VERSION "dbc-export 1 2025.20.8"

NS_ :

BS_:

BU_: BMS CC CMP CMPD CP DAS DI DIF DIR EPBL EPBR EVSE FC GTW HCML HCMR HVP ICR PCS PM PMF PMR PTC SCCM SCM SCS SDCR TAS UMC VC VCFRONT VCLEFT VCRIGHT VCSEC

BO_ 755 UI_hvacRequest: 8 GTW
 SG_ UI_hvacReqTempSetpointLeft : 0|5@1+ (0.5,15) [15|28] "degC" Vector__XXX
 SG_ UI_hvacReqAutoBlowerLevel : 5|3@1+ (1,0) [0|7] "" Vector__XXX
 SG_ UI_hvacReqTempSetpointRight : 8|5@1+ (0.5,15) [15|28] "degC" Vector__XXX
 SG_ UI_hvacReqAirDistributionMode : 13|3@1+ (1,0) [0|7] "" Vector__XXX
 SG_ UI_hvacReqBlowerSegment : 16|4@1+ (1,0) [0|15] "" Vector__XXX
 SG_ UI_hvacReqRecirc : 20|2@1+ (1,0) [0|3] "" Vector__XXX
 SG_ UI_hvacReqACDisable : 22|2@1+ (1,0) [0|3] "" Vector__XXX
 SG_ UI_hvacDefogState : 24|2@1+ (1,0) [0|3] "" Vector__XXX
 SG_ UI_hvacReqUserPowerState : 26|3@1+ (1,0) [0|7] "" Vector__XXX
 SG_ UI_hvacReqSecondRowState : 29|3@1+ (1,0) [0|7] "" Vector__XXX
 SG_ UI_hvacUseModeledDuctTemp : 32|1@1+ (1,0) [0|1] "" Vector__XXX
 SG_ UI_hvacReqKeepClimateOn : 33|2@1+ (1,0) [0|3] "" Vector__XXX
 SG_ UI_hvacReqBioWeaponDefMode : 35|1@1+ (1,0) [0|1] "" Vector__XXX
 SG_ UI_hvacLatchPassengerPresent : 39|1@1+ (1,0) [0|1] "" Vector__XXX
 SG_ UI_enableHvacControlsFeatures1 : 44|1@1+ (1,0) [0|1] "" Vector__XXX
 SG_ UI_enableHvacNotifications : 45|1@1+ (1,0) [0|1] "" Vector__XXX
 SG_ UI_hvacPhoneCallAirFlowAdjustEna : 46|1@1+ (1,0) [0|1] "" Vector__XXX
 SG_ UI_enableHvacVOCPurgeRoutine : 47|1@1+ (1,0) [0|1] "" Vector__XXX
 SG_ UI_enableCustomerTHSAlerts : 53|1@1+ (1,0) [0|1] "" Vector__XXX
 SG_ UI_evapDryingSelectiveEnable : 54|1@1+ (1,0) [0|1] "" Vector__XXX
 SG_ UI_enableHvacWeatherDataBasedHum : 55|1@1+ (1,0) [0|1] "" Vector__XXX
 SG_ UI_hvacReqTempSetpointCOP : 56|2@1+ (1,0) [0|3] "" Vector__XXX
 SG_ UI_hvacClimateNudgeStatus : 58|3@1+ (1,0) [0|7] "" Vector__XXX
 SG_ UI_enableHvacControlsFeatures2 : 61|1@1+ (1,0) [0|1] "" Vector__XXX
 SG_ UI_enableHvacAPFoggingMonitor : 62|1@1+ (1,0) [0|1] "" Vector__XXX
 SG_ UI_enableHvacLimpMode : 63|1@1+ (1,0) [0|1] "" Vector__XXX

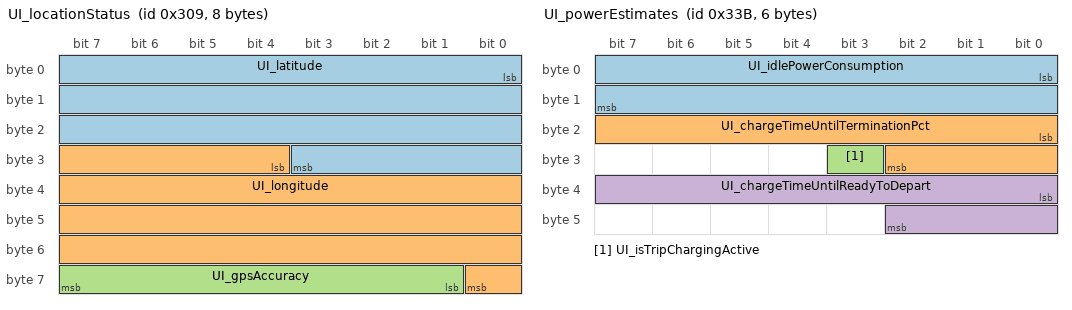
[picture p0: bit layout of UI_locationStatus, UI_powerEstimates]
BO_ 777 UI_locationStatus: 8 GTW
 SG_ UI_latitude : 0|28@1- (1.0e-06,0) [-134.217728|134.217727] "deg" Vector__XXX
 SG_ UI_longitude : 28|29@1- (1.0e-06,0) [-268.435456|268.435455] "deg" Vector__XXX
 SG_ UI_gpsAccuracy : 57|7@1+ (0.2,0) [0|25.2] "m" Vector__XXX

BO_ 1523 UI_odo: 3 GTW
 SG_ UI_odometer : 0|24@1+ (0.1,0) [0|1677721.4] "km" Vector__XXX

BO_ 948 UI_peripheralPowerRequests: 1 GTW
 SG_ UI_usbFrontHubPowerStateRequest : 0|2@1+ (1,0) [1|3] "" Vector__XXX

BO_ 827 UI_powerEstimates: 6 GTW
 SG_ UI_idlePowerConsumption : 0|16@1+ (0.001,0) [0|50] "kW" Vector__XXX
 SG_ UI_chargeTimeUntilTerminationPct : 16|11@1+ (1,0) [0|2046] "min" Vector__XXX
 SG_ UI_isTripChargingActive : 27|1@1+ (1,0) [0|1] "" Vector__XXX
 SG_ UI_chargeTimeUntilReadyToDepart : 32|11@1+ (1,0) [0|2046] "min" Vector__XXX

BO_ 661 UI_powerRationalityConfig: 8 GTW
 SG_ UI_powerRationalityConfigIndex M : 56|8@1+ (1,0) [0|255] "" Vector__XXX
 SG_ UI_vcleftCfgRationalityThreshold m0 : 0|4@1+ (1,0) [1|15] "" Vector__XXX
 SG_ UI_vcleftCfgRationalityTime0 m0 : 4|4@1+ (1,0) [1|15] "" Vector__XXX
 SG_ UI_vcleftCfgRationalityThre_0001 m0 : 8|4@1+ (1,0) [1|15] "" Vector__XXX
 SG_ UI_vcleftCfgRationalityTime1 m0 : 12|4@1+ (1,0) [1|15] "" Vector__XXX
 SG_ UI_vcleftCfgRationalityStaticA m1 : 0|16@1+ (50,0) [0|3276700] "-" Vector__XXX
 SG_ UI_vcleftCfgRationalityStaticB m1 : 16|16@1- (1,0) [-32768|32767] "-" Vector__XXX
 SG_ UI_vcleftCfgRationalityStaticC m1 : 32|16@1- (50,0) [-1638400|1638350] "-" Vector__XXX
 SG_ UI_vcleftCfgRationalityDynamicA m2 : 0|16@1+ (50,0) [0|3276700] "-" Vector__XXX
 SG_ UI_vcleftCfgRationalityDynamicB m2 : 16|16@1- (1,0) [-32768|32767] "-" Vector__XXX
 SG_ UI_vcleftCfgRationalityDynamicC m2 : 32|16@1- (50,0) [-1638400|1638350] "-" Vector__XXX
 SG_ UI_vcrightCfgRationalityThreshol m3 : 0|4@1+ (1,0) [1|15] "" Vector__XXX
 SG_ UI_vcrightCfgRationalityTime0 m3 : 4|4@1+ (1,0) [1|15] "" Vector__XXX
 SG_ UI_vcrightCfgRationalityThr_0001 m3 : 8|4@1+ (1,0) [1|15] "" Vector__XXX
 SG_ UI_vcrightCfgRationalityTime1 m3 : 12|4@1+ (1,0) [1|15] "" Vector__XXX
 SG_ UI_vcrightCfgRationalityStaticA m4 : 0|16@1+ (50,0) [0|3276700] "-" Vector__XXX
 SG_ UI_vcrightCfgRationalityStaticB m4 : 16|16@1- (1,0) [-32768|32767] "-" Vector__XXX
 SG_ UI_vcrightCfgRationalityStaticC m4 : 32|16@1- (50,0) [-1638400|1638350] "-" Vector__XXX
 SG_ UI_vcrightCfgRationalityDynamicA m5 : 0|16@1+ (50,0) [0|3276700] "-" Vector__XXX
 SG_ UI_vcrightCfgRationalityDynamicB m5 : 16|16@1- (1,0) [-32768|32767] "-" Vector__XXX
 SG_ UI_vcrightCfgRationalityDynamicC m5 : 32|16@1- (50,0) [-1638400|1638350] "-" Vector__XXX
 SG_ UI_vcleftCfgCutoffThreshold0 m6 : 0|4@1+ (1,0) [1|15] "" Vector__XXX
 SG_ UI_vcleftCfgCutoffTime0 m6 : 4|4@1+ (1,0) [1|15] "" Vector__XXX
 SG_ UI_vcleftCfgCutoffThreshold1 m6 : 8|4@1+ (1,0) [1|15] "" Vector__XXX
 SG_ UI_vcleftCfgCutoffTime1 m6 : 12|4@1+ (1,0) [1|15] "" Vector__XXX
 SG_ UI_vcleftCfgCutoffStaticA m7 : 0|16@1+ (50,0) [0|3276700] "-" Vector__XXX
 SG_ UI_vcleftCfgCutoffStaticB m7 : 16|16@1- (1,0) [-32768|32767] "-" Vector__XXX
 SG_ UI_vcleftCfgCutoffStaticC m7 : 32|16@1- (50,0) [-1638400|1638350] "-" Vector__XXX
 SG_ UI_vcleftCfgCutoffDynamicA m8 : 0|16@1+ (50,0) [0|3276700] "-" Vector__XXX
 SG_ UI_vcleftCfgCutoffDynamicB m8 : 16|16@1- (1,0) [-32768|32767] "-" Vector__XXX
 SG_ UI_vcleftCfgCutoffDynamicC m8 : 32|16@1- (50,0) [-1638400|1638350] "-" Vector__XXX
 SG_ UI_vcrightCfgCutoffThreshold0 m9 : 0|4@1+ (1,0) [1|15] "" Vector__XXX
 SG_ UI_vcrightCfgCutoffTime0 m9 : 4|4@1+ (1,0) [1|15] "" Vector__XXX
 SG_ UI_vcrightCfgCutoffThreshold1 m9 : 8|4@1+ (1,0) [1|15] "" Vector__XXX
 SG_ UI_vcrightCfgCutoffTime1 m9 : 12|4@1+ (1,0) [1|15] "" Vector__XXX
 SG_ UI_vcrightCfgCutoffStaticA m10 : 0|16@1+ (50,0) [0|3276700] "-" Vector__XXX
 SG_ UI_vcrightCfgCutoffStaticB m10 : 16|16@1- (1,0) [-32768|32767] "-" Vector__XXX
 SG_ UI_vcrightCfgCutoffStaticC m10 : 32|16@1- (50,0) [-1638400|1638350] "-" Vector__XXX
 SG_ UI_vcrightCfgCutoffDynamicA m11 : 0|16@1+ (50,0) [0|3276700] "-" Vector__XXX
 SG_ UI_vcrightCfgCutoffDynamicB m11 : 16|16@1- (1,0) [-32768|32767] "-" Vector__XXX
 SG_ UI_vcrightCfgCutoffDynamicC m11 : 32|16@1- (50,0) [-1638400|1638350] "-" Vector__XXX

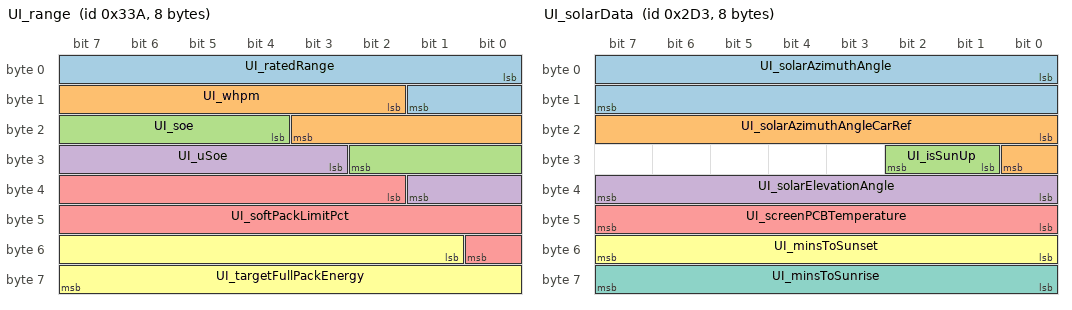
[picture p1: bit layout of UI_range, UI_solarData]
BO_ 826 UI_range: 8 GTW
 SG_ UI_ratedRange : 0|10@1+ (1,0) [0|1023] "mi" Vector__XXX
 SG_ UI_whpm : 10|10@1+ (1,0) [0|1023] "" Vector__XXX
 SG_ UI_soe : 20|7@1+ (1,0) [0|127] "%" Vector__XXX
 SG_ UI_uSoe : 27|7@1+ (1,0) [0|127] "%" Vector__XXX
 SG_ UI_softPackLimitPct : 34|15@1+ (0.003051851,0) [0|100.000001717] "%" Vector__XXX
 SG_ UI_targetFullPackEnergy : 49|15@1+ (0.006103702,0) [0|200.000003434] "kWh" Vector__XXX

BO_ 723 UI_solarData: 8 GTW
 SG_ UI_solarAzimuthAngle : 0|16@1- (1,0) [-32768|32767] "degrees" Vector__XXX
 SG_ UI_solarAzimuthAngleCarRef : 16|9@1- (1,0) [-256|254] "degrees" Vector__XXX
 SG_ UI_isSunUp : 25|2@1+ (1,0) [0|2] "" Vector__XXX
 SG_ UI_solarElevationAngle : 32|8@1- (1,0) [-128|126] "degrees" Vector__XXX
 SG_ UI_screenPCBTemperature : 40|8@1- (0.5,40) [-20|100] "degC" Vector__XXX
 SG_ UI_minsToSunset : 48|8@1+ (10,0) [0|2550] "min" Vector__XXX
 SG_ UI_minsToSunrise : 56|8@1+ (10,0) [0|2550] "min" Vector__XXX

BO_ 851 UI_status: 8 GTW
 SG_ UI_touchActive : 0|1@1+ (1,0) [0|1] "" Vector__XXX
 SG_ UI_audioActive : 1|1@1+ (1,0) [0|1] "" Vector__XXX
 SG_ UI_bluetoothActive : 2|1@1+ (1,0) [0|1] "" Vector__XXX
 SG_ UI_cellActive : 3|1@1+ (1,0) [0|1] "" Vector__XXX
 SG_ UI_displayReady : 4|1@1+ (1,0) [0|1] "" Vector__XXX
 SG_ UI_displayOn : 5|1@1+ (1,0) [0|1] "" Vector__XXX
 SG_ UI_wifiActive : 6|1@1+ (1,0) [0|1] "" Vector__XXX
 SG_ UI_wifiConnected : 7|1@1+ (1,0) [0|1] "" Vector__XXX
 SG_ UI_systemActive : 8|1@1+ (1,0) [0|1] "" Vector__XXX
 SG_ UI_readyForDrive : 9|1@1+ (1,0) [0|1] "" Vector__XXX
 SG_ UI_cellConnected : 10|1@1+ (1,0) [0|1] "" Vector__XXX
 SG_ UI_vpnActive : 11|1@1+ (1,0) [0|1] "" Vector__XXX
 SG_ UI_autopilotTrial : 12|2@1+ (1,0) [0|3] "" Vector__XXX
 SG_ UI_factoryReset : 14|2@1+ (1,0) [1|3] "" Vector__XXX
 SG_ UI_gpsActive : 16|1@1+ (1,0) [0|1] "" Vector__XXX
 SG_ UI_screenshotActive : 17|1@1+ (1,0) [0|1] "" Vector__XXX
 SG_ UI_radioActive : 18|1@1+ (1,0) [0|1] "" Vector__XXX
 SG_ UI_cellNetworkTechnology : 19|4@1+ (1,0) [0|14] "" Vector__XXX
 SG_ UI_cellReceiverPower : 24|8@1+ (1,-128) [-128|127] "dB" Vector__XXX
 SG_ UI_falseTouchCounter : 32|8@1+ (1,0) [0|255] "1" Vector__XXX
 SG_ UI_developmentCar : 40|1@1+ (1,0) [0|1] "" Vector__XXX
 SG_ UI_cameraActive : 41|1@1+ (1,0) [0|1] "" Vector__XXX
 SG_ UI_cellSignalBars : 42|3@1+ (1,0) [0|6] "" Vector__XXX
 SG_ UI_trailerModeTelltale : 45|2@1+ (1,0) [0|3] "" Vector__XXX
 SG_ UI_pcbTemperature : 48|8@1- (1,40) [-20|100] "degC" Vector__XXX
 SG_ UI_cpuTemperature : 56|8@1- (1,40) [-20|100] "degC" Vector__XXX

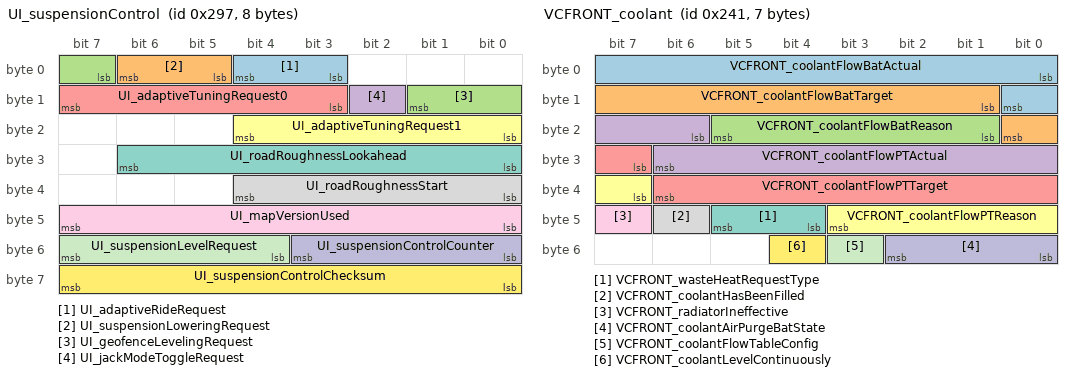
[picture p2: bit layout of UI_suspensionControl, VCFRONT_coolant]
BO_ 663 UI_suspensionControl: 8 GTW
 SG_ UI_adaptiveRideRequest : 3|2@1+ (1,0) [0|3] "" Vector__XXX
 SG_ UI_suspensionLoweringRequest : 5|2@1+ (1,0) [0|2] "" Vector__XXX
 SG_ UI_geofenceLevelingRequest : 7|3@1+ (1,0) [0|7] "" Vector__XXX
 SG_ UI_jackModeToggleRequest : 10|1@1+ (1,0) [0|1] "" Vector__XXX
 SG_ UI_adaptiveTuningRequest0 : 11|5@1- (0.1,0) [-1.6|1.5] "-" Vector__XXX
 SG_ UI_adaptiveTuningRequest1 : 16|5@1- (0.1,0) [-1.6|1.5] "-" Vector__XXX
 SG_ UI_roadRoughnessLookahead : 24|7@1+ (0.01,0) [0|1.26] "%" Vector__XXX
 SG_ UI_roadRoughnessStart : 32|5@1+ (10,0) [0|300] "m" Vector__XXX
 SG_ UI_mapVersionUsed : 40|8@1+ (1,0) [0|254] "-" Vector__XXX
 SG_ UI_suspensionControlCounter : 48|4@1+ (1,0) [0|15] "" Vector__XXX
 SG_ UI_suspensionLevelRequest : 52|4@1+ (1,0) [0|15] "" Vector__XXX
 SG_ UI_suspensionControlChecksum : 56|8@1+ (1,0) [0|255] "" Vector__XXX

BO_ 627 UI_vehicleControl: 8 GTW
 SG_ UI_powerStateRequest : 0|2@1+ (1,0) [0|3] "" Vector__XXX
 SG_ UI_childDoorLockOnRight : 2|1@1+ (1,0) [0|1] "" Vector__XXX
 SG_ UI_frontFogSwitch : 3|1@1+ (1,0) [0|1] "" Vector__XXX
 SG_ UI_summonActive : 4|1@1+ (1,0) [0|1] "" Vector__XXX
 SG_ UI_frunkRequest : 5|1@1+ (1,0) [0|1] "" Vector__XXX
 SG_ UI_wiperMode : 6|2@1+ (1,0) [1|3] "" Vector__XXX
 SG_ UI_steeringBacklightEnabled : 8|1@1+ (1,0) [0|1] "" Vector__XXX
 SG_ UI_steeringButtonMode : 9|3@1+ (1,0) [0|7] "" Vector__XXX
 SG_ UI_walkUpUnlock : 12|1@1+ (1,0) [0|1] "" Vector__XXX
 SG_ UI_walkAwayLock : 13|1@1+ (1,0) [0|1] "" Vector__XXX
 SG_ UI_unlockOnPark : 14|1@1+ (1,0) [0|1] "" Vector__XXX
 SG_ UI_globalUnlockOn : 15|1@1+ (1,0) [0|1] "" Vector__XXX
 SG_ UI_childDoorLockOnLeft : 16|1@1+ (1,0) [0|1] "" Vector__XXX
 SG_ UI_lockRequest : 17|3@1+ (1,0) [0|6] "" Vector__XXX
 SG_ UI_alarmEnabled : 20|1@1+ (1,0) [0|1] "" Vector__XXX
 SG_ UI_intrusionSensorOn : 21|1@1+ (1,0) [0|1] "" Vector__XXX
 SG_ UI_stop12vSupport : 22|1@1+ (1,0) [0|1] "" Vector__XXX
 SG_ UI_rearFogSwitch : 23|1@1+ (1,0) [0|1] "" Vector__XXX
 SG_ UI_mirrorFoldRequest : 24|2@1+ (1,0) [0|2] "" Vector__XXX
 SG_ UI_mirrorHeatRequest : 26|1@1+ (1,0) [0|1] "" Vector__XXX
 SG_ UI_remoteStartRequest : 27|3@1+ (1,0) [0|7] "" Vector__XXX
 SG_ UI_seeYouHomeLightingOn : 30|1@1+ (1,0) [0|1] "" Vector__XXX
 SG_ UI_powerOff : 31|1@1+ (1,0) [0|1] "" Vector__XXX
 SG_ UI_displayBrightnessLevel : 32|8@1+ (0.5,0) [0|127] "%" Vector__XXX
 SG_ UI_ambientLightingEnabled : 40|1@1+ (1,0) [0|1] "" Vector__XXX
 SG_ UI_autoHighBeamEnabled : 41|1@1+ (1,0) [0|1] "" Vector__XXX
 SG_ UI_frontLeftSeatHeatReq : 42|2@1+ (1,0) [0|3] "" Vector__XXX
 SG_ UI_frontRightSeatHeatReq : 44|2@1+ (1,0) [0|3] "" Vector__XXX
 SG_ UI_rearLeftSeatHeatReq : 46|2@1+ (1,0) [0|3] "" Vector__XXX
 SG_ UI_rearCenterSeatHeatReq : 48|2@1+ (1,0) [0|3] "" Vector__XXX
 SG_ UI_rearRightSeatHeatReq : 50|2@1+ (1,0) [0|3] "" Vector__XXX
 SG_ UI_autoFoldMirrorsOn : 52|1@1+ (1,0) [0|1] "" Vector__XXX
 SG_ UI_mirrorDipOnReverse : 53|1@1+ (1,0) [0|1] "" Vector__XXX
 SG_ UI_remoteClosureRequest : 54|2@1+ (1,0) [0|2] "" Vector__XXX
 SG_ UI_wiperRequest : 56|3@1+ (1,0) [1|7] "" Vector__XXX
 SG_ UI_domeLightSwitch : 59|2@1+ (1,0) [0|3] "" Vector__XXX
 SG_ UI_honkHorn : 61|1@1+ (1,0) [0|1] "" Vector__XXX
 SG_ UI_driveStateRequest : 62|1@1+ (1,0) [0|1] "" Vector__XXX
 SG_ UI_rearWindowLockout : 63|1@1+ (1,0) [0|1] "" Vector__XXX

BO_ 1285 UMC_smartAdapterInfo: 8 UMC
 SG_ SA_infoIndex M : 0|8@1+ (1,0) [0|255] "" Vector__XXX
 SG_ SA_genealogyVersion m0 : 8|8@1+ (1,0) [0|255] "" Vector__XXX
 SG_ SA_genealogyCrc m0 : 16|32@1+ (1,0) [0|4294967295] "" Vector__XXX
 SG_ SA_region m0 : 48|4@1+ (1,0) [0|15] "" Vector__XXX
 SG_ SA_OverTempThreshold m0 : 56|8@1+ (1,0) [0|255] "" Vector__XXX
 SG_ SA_partNumInt m31 : 8|32@1+ (1,0) [0|4294967295] "" Vector__XXX
 SG_ SA_partNumRev m31 : 40|8@1+ (1,0) [0|255] "" Vector__XXX
 SG_ SA_currentLimit m31 : 48|8@1+ (1,0) [0|255] "" Vector__XXX
 SG_ SA_l1Voltage m31 : 56|8@1+ (1,0) [0|255] "" Vector__XXX

BO_ 1320 UnixTimeSeconds: 4 Vector__XXX
 SG_ UnixTimeSeconds : 7|32@0+ (1,0) [0|4294967295] "s" Vector__XXX

BO_ 1847 VCFRONT_LVBMS_info: 7 VCFRONT
 SG_ VCFRONT_LVBMS_InfoIndex M : 0|8@1+ (1,0) [0|255] "" Vector__XXX
 SG_ VCFRONT_LVBMS_PcbaId m0 : 8|16@1+ (1,0) [0|65535] "" Vector__XXX
 SG_ VCFRONT_LVBMS_AssemblyId m0 : 24|16@1+ (1,0) [0|65535] "" Vector__XXX
 SG_ VCFRONT_LVBMS_SubUsageId m0 : 40|16@1+ (1,0) [0|65534] "" Vector__XXX
 SG_ VCFRONT_LVBMS_UsageId m1 : 8|16@1+ (1,0) [0|65535] "" Vector__XXX
 SG_ VCFRONT_LVBMS_AppCRC m1 : 24|32@1+ (1,0) [0|4294967295] "" Vector__XXX
 SG_ VCFRONT_LVBMS_FWBuildType m3 : 8|8@1+ (1,0) [0|255] "" Vector__XXX

BO_ 700 VCFRONT_LVThermalMotors10Hz: 8 VCFRONT
 SG_ VCFRONT_LVThermalMotorsIndex M : 0|4@1+ (1,0) [0|15] "" Vector__XXX
 SG_ VCFRONT_radiatorFanState m0 : 4|3@1+ (1,0) [0|7] "" Vector__XXX
 SG_ VCFRONT_radiatorFanTorque m0 : 8|10@1+ (0.006,-1.5) [-1.5|4.5] "Nm" Vector__XXX
 SG_ VCFRONT_radiatorFanIDc m0 : 24|7@1+ (0.5,0) [0|63] "A" Vector__XXX
 SG_ VCFRONT_mlxLINCurrentSchedule m0 : 32|2@1+ (1,0) [0|3] "" Vector__XXX
 SG_ VCFRONT_pumpPowertrainState m3 : 4|3@1+ (1,0) [0|7] "" Vector__XXX
 SG_ VCFRONT_pumpPowertrainTorque m3 : 8|10@1+ (0.006,-1.5) [-1.5|4.5] "Nm" Vector__XXX
 SG_ VCFRONT_pumpPowertrainIDc m3 : 24|7@1+ (0.5,0) [0|63] "A" Vector__XXX
 SG_ VCFRONT_pumpBatteryState m6 : 4|3@1+ (1,0) [0|7] "" Vector__XXX
 SG_ VCFRONT_pumpBatteryTorque m6 : 8|10@1+ (0.006,-1.5) [-1.5|4.5] "Nm" Vector__XXX
 SG_ VCFRONT_pumpBatteryIDc m6 : 24|7@1+ (0.5,0) [0|63] "A" Vector__XXX

BO_ 577 VCFRONT_coolant: 7 VCFRONT
 SG_ VCFRONT_coolantFlowBatActual : 0|9@1+ (0.1,0) [0|40] "LPM" Vector__XXX
 SG_ VCFRONT_coolantFlowBatTarget : 9|8@1+ (0.2,0) [0|40] "LPM" Vector__XXX
 SG_ VCFRONT_coolantFlowBatReason : 17|5@1+ (1,0) [0|31] "" Vector__XXX
 SG_ VCFRONT_coolantFlowPTActual : 22|9@1+ (0.1,0) [0|40] "LPM" Vector__XXX
 SG_ VCFRONT_coolantFlowPTTarget : 31|8@1+ (0.2,0) [0|40] "LPM" Vector__XXX
 SG_ VCFRONT_coolantFlowPTReason : 39|5@1+ (1,0) [0|31] "" Vector__XXX
 SG_ VCFRONT_wasteHeatRequestType : 44|2@1+ (1,0) [0|3] "" Vector__XXX
 SG_ VCFRONT_coolantHasBeenFilled : 46|1@1+ (1,0) [0|1] "" Vector__XXX
 SG_ VCFRONT_radiatorIneffective : 47|1@1+ (1,0) [0|1] "" Vector__XXX
 SG_ VCFRONT_coolantAirPurgeBatState : 48|3@1+ (1,0) [0|7] "" Vector__XXX
 SG_ VCFRONT_coolantFlowTableConfig : 51|1@1+ (1,0) [0|1] "" Vector__XXX
 SG_ VCFRONT_coolantLevelContinuously : 52|1@1+ (1,0) [0|1] "" Vector__XXX

BO_ 1014 VCFRONT_lightStatus: 8 VCFRONT
 SG_ VCFRONT_lowBeamLeftStatus : 0|2@1+ (1,0) [0|2] "" Vector__XXX
 SG_ VCFRONT_lowBeamRightStatus : 2|2@1+ (1,0) [0|2] "" Vector__XXX
 SG_ VCFRONT_highBeamLeftStatus : 4|2@1+ (1,0) [0|2] "" Vector__XXX
 SG_ VCFRONT_highBeamRightStatus : 6|2@1+ (1,0) [0|2] "" Vector__XXX
 SG_ VCFRONT_DRLLeftStatus : 8|2@1+ (1,0) [0|2] "" Vector__XXX
 SG_ VCFRONT_DRLRightStatus : 10|2@1+ (1,0) [0|2] "" Vector__XXX
 SG_ VCFRONT_fogLeftStatus : 12|2@1+ (1,0) [0|2] "" Vector__XXX
 SG_ VCFRONT_fogRightStatus : 14|2@1+ (1,0) [0|2] "" Vector__XXX
 SG_ VCFRONT_sideMarkersStatus : 16|2@1+ (1,0) [0|2] "" Vector__XXX
 SG_ VCFRONT_sideRepeaterLeftStatus : 18|2@1+ (1,0) [0|2] "" Vector__XXX
 SG_ VCFRONT_sideRepeaterRightStatus : 20|2@1+ (1,0) [0|2] "" Vector__XXX
 SG_ VCFRONT_turnSignalLeftStatus : 22|2@1+ (1,0) [0|2] "" Vector__XXX
 SG_ VCFRONT_turnSignalRightStatus : 24|2@1+ (1,0) [0|2] "" Vector__XXX
 SG_ VCFRONT_parkLeftStatus : 26|2@1+ (1,0) [0|2] "" Vector__XXX
 SG_ VCFRONT_parkRightStatus : 28|2@1+ (1,0) [0|2] "" Vector__XXX
 SG_ VCFRONT_lowBeamLeftReadyForAimin : 30|1@1+ (1,0) [0|1] "" Vector__XXX
 SG_ VCFRONT_lowBeamRightReadyForAimi : 31|1@1+ (1,0) [0|1] "" Vector__XXX
 SG_ VCFRONT_lowBeamsOnForDRL : 32|1@1+ (1,0) [0|1] "" Vector__XXX
 SG_ VC_rightHeadlampHealth : 33|3@1+ (1,0) [0|7] "" Vector__XXX
 SG_ VC_leftHeadlampHealth : 36|3@1+ (1,0) [0|7] "" Vector__XXX
 SG_ VCFRONT_lightStatusMuxIndex M : 39|3@1+ (1,0) [0|7] "" Vector__XXX
 SG_ VCFRONT_isAdaptiveHighBeamAvaila m1 : 42|1@1+ (1,0) [0|1] "" Vector__XXX
 SG_ VCFRONT_isAdaptiveHighBeamFaulte m1 : 43|1@1+ (1,0) [0|1] "" Vector__XXX
 SG_ VCFRONT_isBendLightingAvailable m1 : 44|1@1+ (1,0) [0|1] "" Vector__XXX
 SG_ VCFRONT_advancedDrivingBeamStatu m1 : 45|2@1+ (1,0) [0|3] "" Vector__XXX
 SG_ VCFRONT_headlampBendAngle m1 : 47|8@1- (0.1,0) [-12.7|12.7] "deg" Vector__XXX
 SG_ VCFRONT_headlampRoadClass m1 : 55|2@1+ (1,0) [0|3] "" Vector__XXX

BO_ 1013 VCFRONT_lighting: 8 VCFRONT
 SG_ VCFRONT_indicatorLeftRequest : 0|2@1+ (1,0) [0|3] "" Vector__XXX
 SG_ VCFRONT_indicatorRightRequest : 2|2@1+ (1,0) [0|3] "" Vector__XXX
 SG_ VCFRONT_hazardLightRequest : 4|4@1+ (1,0) [0|15] "" Vector__XXX
 SG_ VCFRONT_ambientLightingBrightnes : 8|8@1+ (0.5,0) [0|127] "%" Vector__XXX
 SG_ VCFRONT_switchLightingBrightness : 16|8@1+ (0.5,0) [0|127] "%" Vector__XXX
 SG_ VCFRONT_courtesyLightingRequest : 24|1@1+ (1,0) [0|1] "" Vector__XXX
 SG_ VCFRONT_hazardSwitchBacklight : 27|1@1+ (1,0) [0|1] "" Vector__XXX
 SG_ VCFRONT_highBeamControlState : 28|2@1+ (1,0) [0|3] "" Vector__XXX
 SG_ VCFRONT_dynamicBrakeLightState : 30|2@1+ (1,0) [0|3] "" Vector__XXX
 SG_ VCFRONT_lightingCoreState : 32|4@1+ (1,0) [0|14] "" Vector__XXX
 SG_ VCFRONT_intHighBeamsFunctionStat : 36|1@1+ (1,0) [0|1] "" Vector__XXX
 SG_ VCFRONT_latchedHighBeamsFunction : 37|1@1+ (1,0) [0|1] "" Vector__XXX
 SG_ VCFRONT_frontFogFunctionState : 38|1@1+ (1,0) [0|1] "" Vector__XXX
 SG_ VCFRONT_headlightsReadyOrTimedOu : 39|1@1+ (1,0) [0|1] "" Vector__XXX
 SG_ VCFRONT_turnIndicatorStalk : 40|2@1+ (1,0) [0|2] "" Vector__XXX
 SG_ VCFRONT_highBeamLatchingState : 42|2@1+ (1,0) [1|3] "" Vector__XXX
 SG_ VCFRONT_lightingCustomState : 44|5@1+ (1,0) [0|31] "" Vector__XXX
 SG_ VC_fastFlashHazardsActive : 49|1@1+ (1,0) [0|1] "" Vector__XXX
 SG_ VCFRONT_indicatorLeftInternal : 50|2@1+ (1,0) [0|3] "" Vector__XXX
 SG_ VCFRONT_indicatorRightInternal : 52|2@1+ (1,0) [0|3] "" Vector__XXX

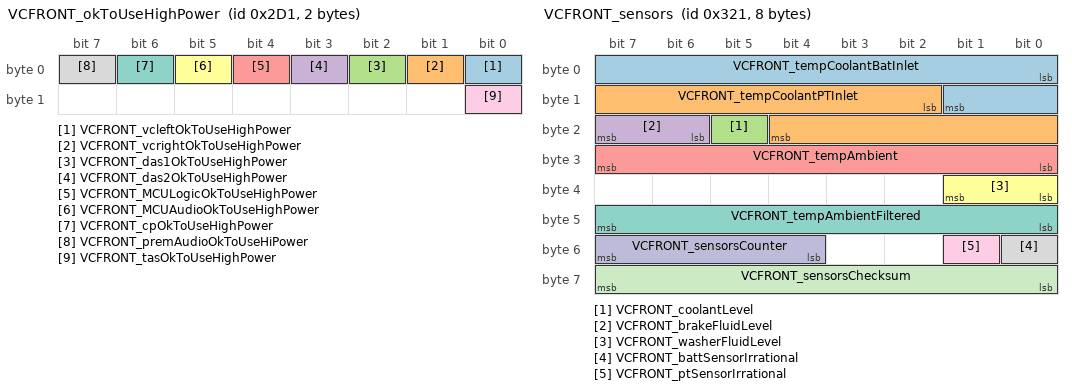
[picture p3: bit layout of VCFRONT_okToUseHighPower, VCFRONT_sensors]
BO_ 721 VCFRONT_okToUseHighPower: 2 VCFRONT
 SG_ VCFRONT_vcleftOkToUseHighPower : 0|1@1+ (1,0) [0|1] "" Vector__XXX
 SG_ VCFRONT_vcrightOkToUseHighPower : 1|1@1+ (1,0) [0|1] "" Vector__XXX
 SG_ VCFRONT_das1OkToUseHighPower : 2|1@1+ (1,0) [0|1] "" Vector__XXX
 SG_ VCFRONT_das2OkToUseHighPower : 3|1@1+ (1,0) [0|1] "" Vector__XXX
 SG_ VCFRONT_MCULogicOkToUseHighPower : 4|1@1+ (1,0) [0|1] "" Vector__XXX
 SG_ VCFRONT_MCUAudioOkToUseHighPower : 5|1@1+ (1,0) [0|1] "" Vector__XXX
 SG_ VCFRONT_cpOkToUseHighPower : 6|1@1+ (1,0) [0|1] "" Vector__XXX
 SG_ VCFRONT_premAudioOkToUseHiPower : 7|1@1+ (1,0) [0|1] "" Vector__XXX
 SG_ VCFRONT_tasOkToUseHighPower : 8|1@1+ (1,0) [0|1] "" Vector__XXX

BO_ 957 VCFRONT_parkedEnergyLoss: 8 VCFRONT
 SG_ VCFRONT_energyLossIndex M : 0|3@1+ (1,0) [0|7] "" Vector__XXX
 SG_ VCFRONT_userEnergyLossSinceDrive m1 : 8|14@1+ (0.01,0) [0|163.83] "kWh" Vector__XXX
 SG_ VCFRONT_preconditioningEner_0001 m1 : 22|14@1+ (0.01,0) [0|163.83] "kWh" Vector__XXX
 SG_ VCFRONT_cabinOverheatEnergy_0001 m1 : 36|14@1+ (0.01,0) [0|163.83] "kWh" Vector__XXX
 SG_ VCFRONT_mobileAppEnergyLoss_0001 m1 : 50|14@1+ (0.01,0) [0|163.83] "kWh" Vector__XXX
 SG_ VCFRONT_summonStandbyEnergy_0001 m2 : 8|14@1+ (0.01,0) [0|163.83] "kWh" Vector__XXX
 SG_ VCFRONT_sentryModeEnergyLos_0001 m2 : 22|14@1+ (0.01,0) [0|163.83] "kWh" Vector__XXX
 SG_ VCFRONT_backgroundEnergyLos_0001 m2 : 36|14@1+ (0.01,0) [0|163.83] "kWh" Vector__XXX
 SG_ VCFRONT_evapDryingEnergyLos_0001 m2 : 50|14@1+ (0.01,0) [0|163.83] "kWh" Vector__XXX
 SG_ VCFRONT_userEnergyLossSinceCharg m3 : 8|14@1+ (0.01,0) [0|163.83] "kWh" Vector__XXX
 SG_ VCFRONT_preconditioningEnergyLos m3 : 22|14@1+ (0.01,0) [0|163.83] "kWh" Vector__XXX
 SG_ VCFRONT_cabinOverheatEnergyLossS m3 : 36|14@1+ (0.01,0) [0|163.83] "kWh" Vector__XXX
 SG_ VCFRONT_mobileAppEnergyLossSince m3 : 50|14@1+ (0.01,0) [0|163.83] "kWh" Vector__XXX
 SG_ VCFRONT_summonStandbyEnergyLossS m4 : 8|14@1+ (0.01,0) [0|163.83] "kWh" Vector__XXX
 SG_ VCFRONT_sentryModeEnergyLossSinc m4 : 22|14@1+ (0.01,0) [0|163.83] "kWh" Vector__XXX
 SG_ VCFRONT_backgroundEnergyLossSinc m4 : 36|14@1+ (0.01,0) [0|163.83] "kWh" Vector__XXX
 SG_ VCFRONT_evapDryingEnergyLossSinc m4 : 50|14@1+ (0.01,0) [0|163.83] "kWh" Vector__XXX

BO_ 801 VCFRONT_sensors: 8 VCFRONT
 SG_ VCFRONT_tempCoolantBatInlet : 0|10@1+ (0.125,-40) [-40|85] "degC" Vector__XXX
 SG_ VCFRONT_tempCoolantPTInlet : 10|11@1+ (0.125,-40) [-40|200] "degC" Vector__XXX
 SG_ VCFRONT_coolantLevel : 21|1@1+ (1,0) [0|1] "" Vector__XXX
 SG_ VCFRONT_brakeFluidLevel : 22|2@1+ (1,0) [1|3] "" Vector__XXX
 SG_ VCFRONT_tempAmbient : 24|8@1+ (0.5,-40) [-39.5|80] "degC" Vector__XXX
 SG_ VCFRONT_washerFluidLevel : 32|2@1+ (1,0) [1|3] "" Vector__XXX
 SG_ VCFRONT_tempAmbientFiltered : 40|8@1+ (0.5,-40) [-39.5|80] "degC" Vector__XXX
 SG_ VCFRONT_battSensorIrrational : 48|1@1+ (1,0) [0|1] "" Vector__XXX
 SG_ VCFRONT_ptSensorIrrational : 49|1@1+ (1,0) [0|1] "" Vector__XXX
 SG_ VCFRONT_sensorsCounter : 52|4@1+ (1,0) [0|15] "" Vector__XXX
 SG_ VCFRONT_sensorsChecksum : 56|8@1+ (1,0) [0|255] "" Vector__XXX

BO_ 1349 VCFRONT_systemStatus: 8 VCFRONT
 SG_ VCFRONT_systemStatusMuxIndex M : 0|2@1+ (1,0) [0|3] "" Vector__XXX
 SG_ VCFRONT_systemStatusCounter : 52|4@1+ (1,0) [0|15] "" Vector__XXX
 SG_ VCFRONT_systemStatusChecksum : 56|8@1+ (1,0) [0|255] "" Vector__XXX
 SG_ VCFRONT_loadShedReason m1 : 3|9@1+ (1,0) [0|511] "" Vector__XXX
 SG_ VCFRONT_VCRightEFuseLoadShedStag m1 : 12|5@1+ (1,0) [0|31] "" Vector__XXX
 SG_ VCFRONT_VCLeftEFuseLoadShedStage m1 : 20|5@1+ (1,0) [0|31] "" Vector__XXX
 SG_ VCFRONT_DCDCSaturationLoadShedSt m1 : 28|5@1+ (1,0) [0|31] "" Vector__XXX
 SG_ VCFRONT_vehicleLoadShedStage m1 : 36|2@1+ (1,0) [0|3] "" Vector__XXX
 SG_ VCFRONT_HVFaultVehicleLoadShedRe m1 : 38|1@1+ (1,0) [0|1] "" Vector__XXX
 SG_ VCFRONT_postCrashVehicleLoadShed m1 : 39|1@1+ (1,0) [0|1] "" Vector__XXX
 SG_ VCFRONT_HVFaultVehicleLoadShedAc m1 : 40|1@1+ (1,0) [0|1] "" Vector__XXX
 SG_ VCFRONT_factoryVehicleLoadShedAc m1 : 41|1@1+ (1,0) [0|1] "" Vector__XXX
 SG_ VCFRONT_anyVehicleLoadShedActive m1 : 42|1@1+ (1,0) [0|1] "" Vector__XXX
 SG_ VCFRONT_DIVehLoadShedActive m1 : 43|1@1+ (1,0) [0|1] "" Vector__XXX
 SG_ VCFRONT_HVFaultLoadShedStateDBG m1 : 44|2@1+ (1,0) [0|3] "" Vector__XXX
 SG_ VCFRONT_LVUnhealthyVehicleLoadSh m1 : 46|1@1+ (1,0) [0|1] "" Vector__XXX
 SG_ VCFRONT_loadShedStsCondenserFan m2 : 3|1@1+ (1,0) [0|1] "" Vector__XXX
 SG_ VCFRONT_loadShedStsPTPump m2 : 6|1@1+ (1,0) [0|1] "" Vector__XXX
 SG_ VCFRONT_loadShedMCUAudio m2 : 10|1@1+ (1,0) [0|1] "" Vector__XXX
 SG_ VCFRONT_loadShedHVDownTriggerDBG m2 : 11|1@1+ (1,0) [0|1] "" Vector__XXX
 SG_ VCFRONT_loadShedPCSSatTriggerDBG m2 : 12|1@1+ (1,0) [0|1] "" Vector__XXX
 SG_ VCFRONT_loadShedStsBatteryPump m2 : 13|1@1+ (1,0) [0|1] "" Vector__XXX
 SG_ VCFRONT_loadShedStsAPGlassHeater m2 : 14|1@1+ (1,0) [0|1] "" Vector__XXX
 SG_ VCFRONT_loadShedStsMCUGraphics m2 : 15|1@1+ (1,0) [0|1] "" Vector__XXX
 SG_ VCFRONT_IBSCurrentRMS_loadShed m2 : 16|7@1+ (0.05,0) [0|6.35] "A" Vector__XXX
 SG_ VCFRONT_loadShedAhLeakyBktCntDBG m2 : 23|9@1+ (0.001,0) [0|0.511] "Ah" Vector__XXX
 SG_ VCFRONT_loadShedPcs m2 : 33|1@1+ (1,0) [0|1] "" Vector__XXX
 SG_ VCFRONT_loadShedGTWDownstrmRails m2 : 35|1@1+ (1,0) [0|1] "" Vector__XXX
 SG_ VCFRONT_loadShedPCSMIATriggerDBG m2 : 36|1@1+ (1,0) [0|1] "" Vector__XXX
 SG_ VCFRONT_loadShedTAS m2 : 37|1@1+ (1,0) [0|1] "" Vector__XXX
 SG_ VCFRONT_loadShedBackStopBktCntDB m2 : 38|5@1+ (0.05,0) [0|1.55] "Ah" Vector__XXX
 SG_ VCFRONT_loadShedPCSLeakyBktCtDBG m2 : 44|6@1+ (100,0) [0|6300] "mV" Vector__XXX
 SG_ VCFRONT_loadShedUI m2 : 50|1@1+ (1,0) [0|1] "" Vector__XXX
 SG_ VCFRONT_loadShedAutoPilot m2 : 51|1@1+ (1,0) [0|1] "" Vector__XXX

BO_ 507 VCLEFT_TLCStatus: 8 VCLEFT
 SG_ VCLEFT_TLCStatusIndex M : 0|2@1+ (1,0) [0|3] "" Vector__XXX
 SG_ VCLEFT_TLCTemperature m1 : 2|8@1- (1,68) [-59|195] "degC" Vector__XXX
 SG_ VCLEFT_TLCLeftTurnVoltage m1 : 10|8@1+ (0.1,0) [0|25.4] "V" Vector__XXX
 SG_ VCLEFT_TLCRightTurnVoltage m1 : 18|8@1+ (0.1,0) [0|25.4] "V" Vector__XXX
 SG_ VCLEFT_TLCState_LeftTurn m1 : 26|3@1+ (1,0) [0|7] "" Vector__XXX
 SG_ VCLEFT_TLCState_RightTurn m1 : 29|3@1+ (1,0) [0|7] "" Vector__XXX
 SG_ VCLEFT_TLCState_Tail m1 : 32|3@1+ (1,0) [0|7] "" Vector__XXX
 SG_ VCLEFT_TLCState_Stop m1 : 35|3@1+ (1,0) [0|7] "" Vector__XXX
 SG_ VCLEFT_TLCState_Fog m1 : 38|3@1+ (1,0) [0|7] "" Vector__XXX
 SG_ VCLEFT_TLCState_Reverse m1 : 41|3@1+ (1,0) [0|7] "" Vector__XXX

BO_ 290 VCLEFT_doorStatus2: 8 VCLEFT
 SG_ VCLEFT_doorStatus2Index M : 0|1@1+ (1,0) [0|1] "" Vector__XXX
 SG_ VCLEFT_frontLatchRelDuty m1 : 8|8@1+ (1,0) [0|255] "%" Vector__XXX
 SG_ VCLEFT_BPillarCameraHeaterState m1 : 16|3@1+ (1,0) [1|7] "" Vector__XXX
 SG_ VCLEFT_doorLatchAjarSwitchVoltag m1 : 24|8@1+ (0.02,0) [0|5] "V" Vector__XXX
 SG_ VCLEFT_doorLatchAjarSwitchV_0001 m1 : 32|8@1+ (0.02,0) [0|5] "V" Vector__XXX
 SG_ VCLEFT_BPillarCameraHeaterCurren m1 : 40|6@1+ (0.02,0) [0|1.24] "A" Vector__XXX
 SG_ VCLEFT_mirrorTiltXOffset m1 : 48|8@1- (0.02,0) [-2.5|2.5] "V" Vector__XXX
 SG_ VCLEFT_mirrorTiltYOffset m1 : 56|8@1- (0.02,0) [-2.5|2.5] "V" Vector__XXX

BO_ 1186 VCLEFT_etcBluetoothStatus: 1 VCLEFT
 SG_ VCLEFT_etcBluetoothStatus : 0|2@1+ (1,0) [0|3] "" Vector__XXX

BO_ 642 VCLEFT_hvacBlowerFeedback: 8 VCLEFT
 SG_ VCLEFT_hvacBlowerFeedbackIndex M : 0|1@1+ (1,0) [0|1] "" Vector__XXX
 SG_ VCLEFT_hvacBlowerEnabled m0 : 2|1@1+ (1,0) [0|1] "" Vector__XXX
 SG_ VCLEFT_hvacBlowerOutputDuty m0 : 3|7@1+ (1,0) [0|100] "%" Vector__XXX
 SG_ VCLEFT_hvacBlowerRPMTarget m0 : 10|10@1+ (10,0) [0|10000] "rpm" Vector__XXX
 SG_ VCLEFT_hvacBlowerRPMActual m0 : 20|10@1+ (10,0) [0|10000] "rpm" Vector__XXX
 SG_ VCLEFT_hvacBlowerTorque m0 : 34|10@1+ (0.006,-1.5) [-1.5|4.5] "Nm" Vector__XXX
 SG_ VCLEFT_hvacBlowerFETTemp m0 : 44|7@1+ (2,-50) [-50|180] "degC" Vector__XXX
 SG_ VCLEFT_hvacBlowerIDc m0 : 51|7@1+ (0.5,0) [0|63] "A" Vector__XXX
 SG_ VCLEFT_hvacBlowerInitd m0 : 58|1@1+ (1,0) [0|1] "" Vector__XXX
 SG_ VCLEFT_hvacBlowerFault m0 : 59|1@1+ (1,0) [0|1] "" Vector__XXX
 SG_ VCLEFT_hvacBlowerLimitFETTemps m0 : 60|1@1+ (1,0) [0|1] "" Vector__XXX
 SG_ VCLEFT_hvacBlowerPowerOn m0 : 61|1@1+ (1,0) [0|1] "" Vector__XXX
 SG_ VCLEFT_hvacBlowerMotorID m0 : 62|2@1+ (1,0) [0|3] "" Vector__XXX

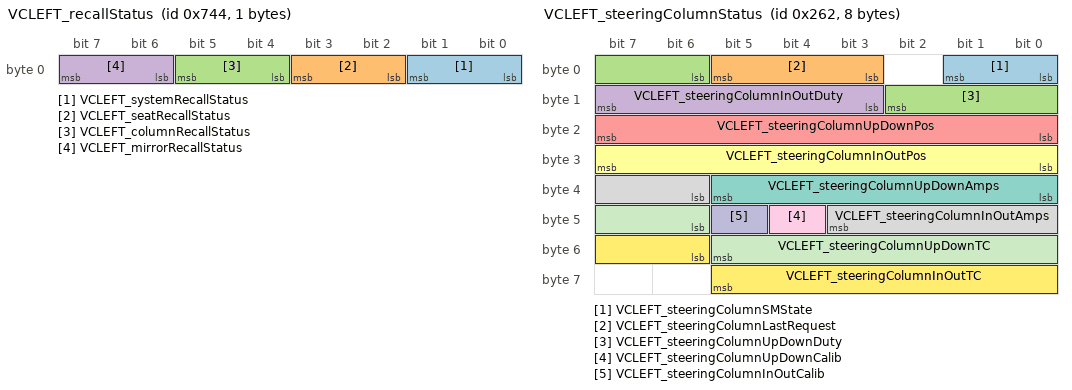
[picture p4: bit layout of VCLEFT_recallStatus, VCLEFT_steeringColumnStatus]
BO_ 1860 VCLEFT_recallStatus: 1 VCLEFT
 SG_ VCLEFT_systemRecallStatus : 0|2@1+ (1,0) [1|3] "" Vector__XXX
 SG_ VCLEFT_seatRecallStatus : 2|2@1+ (1,0) [1|3] "" Vector__XXX
 SG_ VCLEFT_columnRecallStatus : 4|2@1+ (1,0) [1|3] "" Vector__XXX
 SG_ VCLEFT_mirrorRecallStatus : 6|2@1+ (1,0) [1|3] "" Vector__XXX

BO_ 610 VCLEFT_steeringColumnStatus: 8 VCLEFT
 SG_ VCLEFT_steeringColumnSMState : 0|2@1+ (1,0) [1|3] "" Vector__XXX
 SG_ VCLEFT_steeringColumnLastRequest : 3|3@1+ (1,0) [1|7] "" Vector__XXX
 SG_ VCLEFT_steeringColumnUpDownDuty : 6|5@1- (7,0) [-100|100] "%" Vector__XXX
 SG_ VCLEFT_steeringColumnInOutDuty : 11|5@1- (7,0) [-100|100] "%" Vector__XXX
 SG_ VCLEFT_steeringColumnUpDownPos : 16|8@1- (1,103) [-25|230] "mm" Vector__XXX
 SG_ VCLEFT_steeringColumnInOutPos : 24|8@1- (1,103) [-25|230] "mm" Vector__XXX
 SG_ VCLEFT_steeringColumnUpDownAmps : 32|6@1- (0.63,0) [-20|19.53] "A" Vector__XXX
 SG_ VCLEFT_steeringColumnInOutAmps : 38|6@1- (0.63,0) [-20|19.53] "A" Vector__XXX
 SG_ VCLEFT_steeringColumnUpDownCalib : 44|1@1+ (1,0) [0|1] "" Vector__XXX
 SG_ VCLEFT_steeringColumnInOutCalib : 45|1@1+ (1,0) [0|1] "" Vector__XXX
 SG_ VCLEFT_steeringColumnUpDownTC : 46|8@1+ (0.5,-10) [-10|117.5] "s" Vector__XXX
 SG_ VCLEFT_steeringColumnInOutTC : 54|8@1+ (0.5,-10) [-10|117.5] "s" Vector__XXX

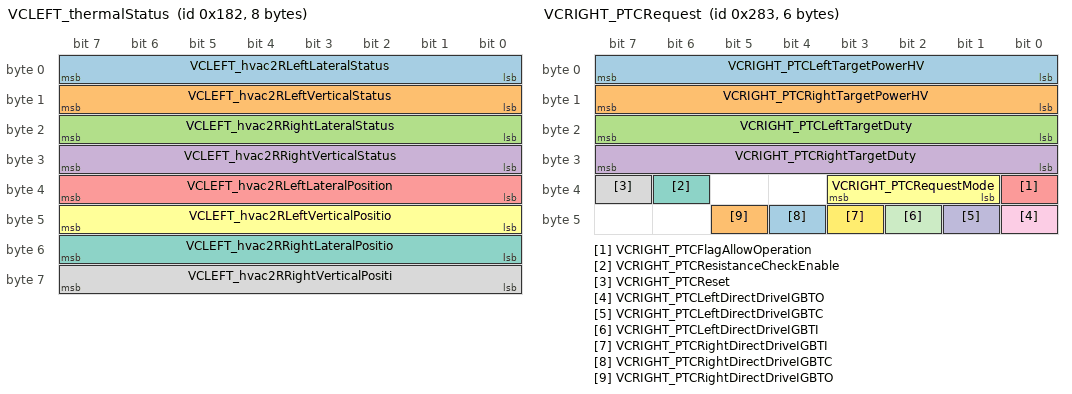
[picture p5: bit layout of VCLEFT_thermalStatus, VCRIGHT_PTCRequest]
BO_ 386 VCLEFT_thermalStatus: 8 VCLEFT
 SG_ VCLEFT_hvac2RLeftLateralStatus : 0|8@1+ (1,0) [0|255] "" Vector__XXX
 SG_ VCLEFT_hvac2RLeftVerticalStatus : 8|8@1+ (1,0) [0|255] "" Vector__XXX
 SG_ VCLEFT_hvac2RRightLateralStatus : 16|8@1+ (1,0) [0|255] "" Vector__XXX
 SG_ VCLEFT_hvac2RRightVerticalStatus : 24|8@1+ (1,0) [0|255] "" Vector__XXX
 SG_ VCLEFT_hvac2RLeftLateralPosition : 32|8@1+ (0.4,0) [0|100] "%" Vector__XXX
 SG_ VCLEFT_hvac2RLeftVerticalPositio : 40|8@1+ (0.4,0) [0|100] "%" Vector__XXX
 SG_ VCLEFT_hvac2RRightLateralPositio : 48|8@1+ (0.4,0) [0|100] "%" Vector__XXX
 SG_ VCLEFT_hvac2RRightVerticalPositi : 56|8@1+ (0.4,0) [0|100] "%" Vector__XXX

BO_ 706 VCLEFT_windowStatus: 8 VCLEFT
 SG_ VCLEFT_windowStatusIndex M : 0|1@1+ (1,0) [0|1] "" Vector__XXX
 SG_ VCLEFT_windowStateLF m0 : 1|4@1+ (1,0) [0|15] "" Vector__XXX
 SG_ VCLEFT_windowTrimClearMoveReques m0 : 5|2@1+ (1,0) [0|3] "" Vector__XXX
 SG_ VCLEFT_windowDutyLF m0 : 8|6@1- (5,0) [-100|100] "%" Vector__XXX
 SG_ VCLEFT_windowTrimClearActiveRequ m0 : 14|2@1+ (1,0) [1|3] "" Vector__XXX
 SG_ VCLEFT_windowCurrentLF m0 : 16|6@1- (0.5,0) [-15|15] "A" Vector__XXX
 SG_ VCLEFT_windowPositionLF m0 : 22|9@1- (1.25,265) [-50|580] "mm" Vector__XXX
 SG_ VCLEFT_windowCalibratedLF m0 : 32|1@1+ (1,0) [0|1] "" Vector__XXX
 SG_ VCLEFT_windowStateLR m0 : 33|4@1+ (1,0) [0|15] "" Vector__XXX
 SG_ VCLEFT_windowDutyLR m0 : 40|6@1- (5,0) [-100|100] "%" Vector__XXX
 SG_ VCLEFT_windowCurrentLR m0 : 48|6@1- (0.5,0) [-15|15] "A" Vector__XXX
 SG_ VCLEFT_windowPositionLR m0 : 54|9@1- (1.25,265) [-50|580] "mm" Vector__XXX
 SG_ VCLEFT_windowCalibratedLR m0 : 63|1@1+ (1,0) [0|1] "" Vector__XXX
 SG_ VCLEFT_windowThermalTCLF m1 : 1|8@1+ (1,0) [0|255] "s" Vector__XXX
 SG_ VCLEFT_windowThermalModeLF m1 : 9|2@1+ (1,0) [1|3] "" Vector__XXX
 SG_ VCLEFT_windowStopReasonLF m1 : 11|3@1+ (1,0) [0|7] "" Vector__XXX
 SG_ VCLEFT_windowStopReqReasonLF m1 : 14|4@1+ (1,0) [0|15] "" Vector__XXX
 SG_ VCLEFT_windowThermalTCLR m1 : 18|8@1+ (1,0) [0|255] "s" Vector__XXX
 SG_ VCLEFT_windowThermalModeLR m1 : 26|2@1+ (1,0) [1|3] "" Vector__XXX
 SG_ VCLEFT_windowStopReasonLR m1 : 28|3@1+ (1,0) [0|7] "" Vector__XXX
 SG_ VCLEFT_windowStopReqReasonLR m1 : 31|4@1+ (1,0) [0|15] "" Vector__XXX
 SG_ VCLEFT_windowControlStateLF m1 : 35|2@1+ (1,0) [0|3] "" Vector__XXX
 SG_ VCLEFT_windowCtrlUnavailableLF m1 : 38|3@1+ (1,0) [0|7] "" Vector__XXX
 SG_ VCLEFT_windowControlStateLR m1 : 42|2@1+ (1,0) [0|3] "" Vector__XXX
 SG_ VCLEFT_windowCtrlUnavailableLR m1 : 45|3@1+ (1,0) [0|7] "" Vector__XXX
 SG_ VCLEFT_windowPositionStateLF m1 : 49|3@1+ (1,0) [0|7] "" Vector__XXX
 SG_ VCLEFT_windowPositionStateLR m1 : 52|3@1+ (1,0) [0|7] "" Vector__XXX
 SG_ VCLEFT_windowVehGearStateLF m1 : 56|2@1+ (1,0) [1|3] "" Vector__XXX
 SG_ VCLEFT_windowVehGearStateLR m1 : 58|2@1+ (1,0) [1|3] "" Vector__XXX
 SG_ VCLEFT_windowSpeedTableStatusLF m1 : 60|2@1+ (1,0) [1|3] "" Vector__XXX
 SG_ VCLEFT_windowSpeedTableStatusLR m1 : 62|2@1+ (1,0) [1|3] "" Vector__XXX

BO_ 643 VCRIGHT_PTCRequest: 6 VCRIGHT
 SG_ VCRIGHT_PTCLeftTargetPowerHV : 0|8@1+ (30,0) [0|7650] "W" Vector__XXX
 SG_ VCRIGHT_PTCRightTargetPowerHV : 8|8@1+ (30,0) [0|7650] "W" Vector__XXX
 SG_ VCRIGHT_PTCLeftTargetDuty : 16|8@1+ (0.5,0) [0|100] "%" Vector__XXX
 SG_ VCRIGHT_PTCRightTargetDuty : 24|8@1+ (0.5,0) [0|100] "%" Vector__XXX
 SG_ VCRIGHT_PTCFlagAllowOperation : 32|1@1+ (1,0) [0|1] "" Vector__XXX
 SG_ VCRIGHT_PTCRequestMode : 33|3@1+ (1,0) [0|7] "" Vector__XXX
 SG_ VCRIGHT_PTCResistanceCheckEnable : 38|1@1+ (1,0) [0|1] "" Vector__XXX
 SG_ VCRIGHT_PTCReset : 39|1@1+ (1,0) [0|1] "" Vector__XXX
 SG_ VCRIGHT_PTCLeftDirectDriveIGBTO : 40|1@1+ (1,0) [0|1] "" Vector__XXX
 SG_ VCRIGHT_PTCLeftDirectDriveIGBTC : 41|1@1+ (1,0) [0|1] "" Vector__XXX
 SG_ VCRIGHT_PTCLeftDirectDriveIGBTI : 42|1@1+ (1,0) [0|1] "" Vector__XXX
 SG_ VCRIGHT_PTCRightDirectDriveIGBTI : 43|1@1+ (1,0) [0|1] "" Vector__XXX
 SG_ VCRIGHT_PTCRightDirectDriveIGBTC : 44|1@1+ (1,0) [0|1] "" Vector__XXX
 SG_ VCRIGHT_PTCRightDirectDriveIGBTO : 45|1@1+ (1,0) [0|1] "" Vector__XXX

BO_ 291 VCRIGHT_doorStatus2: 8 VCRIGHT
 SG_ VCRIGHT_doorStatus2Index M : 0|1@1+ (1,0) [0|1] "" Vector__XXX
 SG_ VCRIGHT_frontLatchRelDuty m1 : 8|8@1+ (1,0) [0|255] "%" Vector__XXX
 SG_ VCRIGHT_BPillarCameraHeaterState m1 : 16|3@1+ (1,0) [1|7] "" Vector__XXX
 SG_ VCRIGHT_doorLatchAjarSwitchVolta m1 : 24|8@1+ (0.02,0) [0|5] "V" Vector__XXX
 SG_ VCRIGHT_doorLatchAjarSwitch_0001 m1 : 32|8@1+ (0.02,0) [0|5] "V" Vector__XXX
 SG_ VCRIGHT_BPillarCameraHeaterCurre m1 : 40|6@1+ (0.02,0) [0|1.24] "A" Vector__XXX
 SG_ VCRIGHT_mirrorTiltXOffset m1 : 48|8@1- (0.02,0) [-2.5|2.5] "V" Vector__XXX
 SG_ VCRIGHT_mirrorTiltYOffset m1 : 56|8@1- (0.02,0) [-2.5|2.5] "V" Vector__XXX

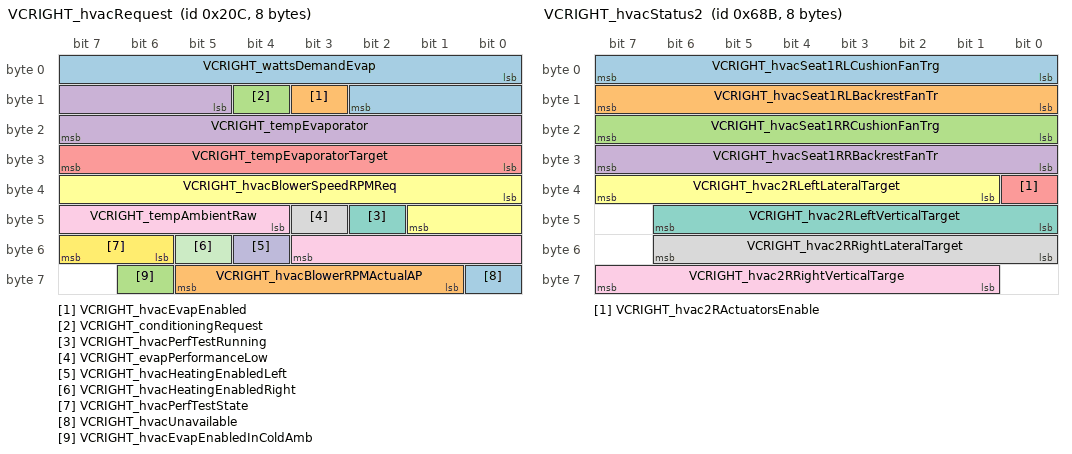
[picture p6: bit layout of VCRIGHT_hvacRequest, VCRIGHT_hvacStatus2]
BO_ 524 VCRIGHT_hvacRequest: 8 VCRIGHT
 SG_ VCRIGHT_wattsDemandEvap : 0|11@1+ (5,0) [0|10000] "W" Vector__XXX
 SG_ VCRIGHT_hvacEvapEnabled : 11|1@1+ (1,0) [0|1] "" Vector__XXX
 SG_ VCRIGHT_conditioningRequest : 12|1@1+ (1,0) [0|1] "" Vector__XXX
 SG_ VCRIGHT_tempEvaporator : 13|11@1+ (0.1,-40) [-40|105] "degC" Vector__XXX
 SG_ VCRIGHT_tempEvaporatorTarget : 24|8@1+ (0.2,0) [0|50] "degC" Vector__XXX
 SG_ VCRIGHT_hvacBlowerSpeedRPMReq : 32|10@1+ (5,0) [0|5115] "RPM" Vector__XXX
 SG_ VCRIGHT_hvacPerfTestRunning : 42|1@1+ (1,0) [0|1] "" Vector__XXX
 SG_ VCRIGHT_evapPerformanceLow : 43|1@1+ (1,0) [0|1] "" Vector__XXX
 SG_ VCRIGHT_tempAmbientRaw : 44|8@1+ (0.5,-40) [-39.5|80] "degC" Vector__XXX
 SG_ VCRIGHT_hvacHeatingEnabledLeft : 52|1@1+ (1,0) [0|1] "" Vector__XXX
 SG_ VCRIGHT_hvacHeatingEnabledRight : 53|1@1+ (1,0) [0|1] "" Vector__XXX
 SG_ VCRIGHT_hvacPerfTestState : 54|2@1+ (1,0) [0|3] "" Vector__XXX
 SG_ VCRIGHT_hvacUnavailable : 56|1@1+ (1,0) [0|1] "" Vector__XXX
 SG_ VCRIGHT_hvacBlowerRPMActualAP : 57|5@1+ (200,0) [0|4200] "rpm" Vector__XXX
 SG_ VCRIGHT_hvacEvapEnabledInColdAmb : 62|1@1+ (1,0) [0|1] "" Vector__XXX

BO_ 1675 VCRIGHT_hvacStatus2: 8 VCRIGHT
 SG_ VCRIGHT_hvacSeat1RLCushionFanTrg : 0|8@1+ (0.5,0) [0|100] "%" Vector__XXX
 SG_ VCRIGHT_hvacSeat1RLBackrestFanTr : 8|8@1+ (0.5,0) [0|100] "%" Vector__XXX
 SG_ VCRIGHT_hvacSeat1RRCushionFanTrg : 16|8@1+ (0.5,0) [0|100] "%" Vector__XXX
 SG_ VCRIGHT_hvacSeat1RRBackrestFanTr : 24|8@1+ (0.5,0) [0|100] "%" Vector__XXX
 SG_ VCRIGHT_hvac2RActuatorsEnable : 32|1@1+ (1,0) [0|1] "" Vector__XXX
 SG_ VCRIGHT_hvac2RLeftLateralTarget : 33|7@1+ (1,0) [0|100] "%" Vector__XXX
 SG_ VCRIGHT_hvac2RLeftVerticalTarget : 40|7@1+ (1,0) [0|100] "%" Vector__XXX
 SG_ VCRIGHT_hvac2RRightLateralTarget : 48|7@1+ (1,0) [0|100] "%" Vector__XXX
 SG_ VCRIGHT_hvac2RRightVerticalTarge : 57|7@1+ (1,0) [0|100] "%" Vector__XXX

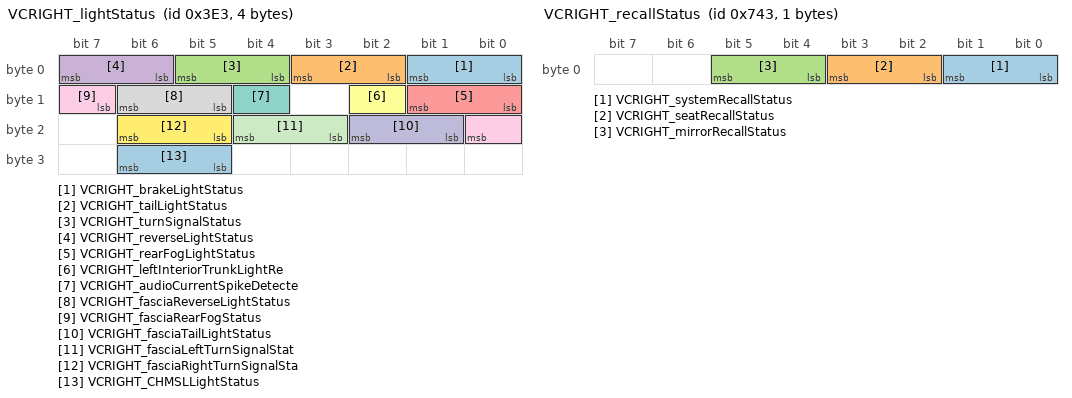
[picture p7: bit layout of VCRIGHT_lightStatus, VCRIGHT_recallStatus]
BO_ 995 VCRIGHT_lightStatus: 4 VCRIGHT
 SG_ VCRIGHT_brakeLightStatus : 0|2@1+ (1,0) [0|2] "" Vector__XXX
 SG_ VCRIGHT_tailLightStatus : 2|2@1+ (1,0) [0|2] "" Vector__XXX
 SG_ VCRIGHT_turnSignalStatus : 4|2@1+ (1,0) [0|2] "" Vector__XXX
 SG_ VCRIGHT_reverseLightStatus : 6|2@1+ (1,0) [0|2] "" Vector__XXX
 SG_ VCRIGHT_rearFogLightStatus : 8|2@1+ (1,0) [0|2] "" Vector__XXX
 SG_ VCRIGHT_leftInteriorTrunkLightRe : 10|1@1+ (1,0) [0|1] "" Vector__XXX
 SG_ VCRIGHT_audioCurrentSpikeDetecte : 12|1@1+ (1,0) [0|1] "" Vector__XXX
 SG_ VCRIGHT_fasciaReverseLightStatus : 13|2@1+ (1,0) [0|2] "" Vector__XXX
 SG_ VCRIGHT_fasciaRearFogStatus : 15|2@1+ (1,0) [0|2] "" Vector__XXX
 SG_ VCRIGHT_fasciaTailLightStatus : 17|2@1+ (1,0) [0|2] "" Vector__XXX
 SG_ VCRIGHT_fasciaLeftTurnSignalStat : 19|2@1+ (1,0) [0|2] "" Vector__XXX
 SG_ VCRIGHT_fasciaRightTurnSignalSta : 21|2@1+ (1,0) [0|2] "" Vector__XXX
 SG_ VCRIGHT_CHMSLLightStatus : 29|2@1+ (1,0) [0|2] "" Vector__XXX

BO_ 1859 VCRIGHT_recallStatus: 1 VCRIGHT
 SG_ VCRIGHT_systemRecallStatus : 0|2@1+ (1,0) [1|3] "" Vector__XXX
 SG_ VCRIGHT_seatRecallStatus : 2|2@1+ (1,0) [1|3] "" Vector__XXX
 SG_ VCRIGHT_mirrorRecallStatus : 4|2@1+ (1,0) [1|3] "" Vector__XXX

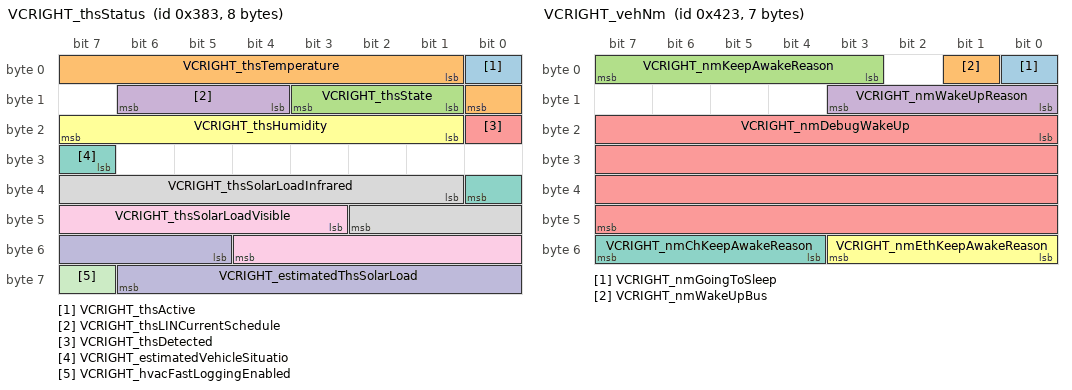
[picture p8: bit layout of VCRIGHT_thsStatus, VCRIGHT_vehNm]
BO_ 899 VCRIGHT_thsStatus: 8 VCRIGHT
 SG_ VCRIGHT_thsActive : 0|1@1+ (1,0) [0|1] "" Vector__XXX
 SG_ VCRIGHT_thsTemperature : 1|8@1+ (1,-40) [-40|150] "degC" Vector__XXX
 SG_ VCRIGHT_thsState : 9|3@1+ (1,0) [0|7] "" Vector__XXX
 SG_ VCRIGHT_thsLINCurrentSchedule : 12|3@1+ (1,0) [0|7] "" Vector__XXX
 SG_ VCRIGHT_thsDetected : 16|1@1+ (1,0) [0|1] "" Vector__XXX
 SG_ VCRIGHT_thsHumidity : 17|7@1+ (1,0) [0|100] "%" Vector__XXX
 SG_ VCRIGHT_estimatedVehicleSituatio : 31|2@1+ (1,0) [0|3] "" Vector__XXX
 SG_ VCRIGHT_thsSolarLoadInfrared : 33|10@1+ (2,0) [0|2044] "W/m2" Vector__XXX
 SG_ VCRIGHT_thsSolarLoadVisible : 43|10@1+ (2,0) [0|2044] "W/m2" Vector__XXX
 SG_ VCRIGHT_estimatedThsSolarLoad : 53|10@1+ (1,0) [0|1022] "W/m2" Vector__XXX
 SG_ VCRIGHT_hvacFastLoggingEnabled : 63|1@1+ (1,0) [0|1] "" Vector__XXX

BO_ 1059 VCRIGHT_vehNm: 7 VCRIGHT
 SG_ VCRIGHT_nmGoingToSleep : 0|1@1+ (1,0) [0|1] "" Vector__XXX
 SG_ VCRIGHT_nmWakeUpBus : 1|1@1+ (1,0) [0|1] "" Vector__XXX
 SG_ VCRIGHT_nmKeepAwakeReason : 3|5@1+ (1,0) [1|31] "" Vector__XXX
 SG_ VCRIGHT_nmWakeUpReason : 8|4@1+ (1,0) [0|15] "" Vector__XXX
 SG_ VCRIGHT_nmDebugWakeUp : 16|32@1+ (1,0) [0|4294967295] "" Vector__XXX
 SG_ VCRIGHT_nmEthKeepAwakeReason : 48|4@1+ (1,0) [1|15] "" Vector__XXX
 SG_ VCRIGHT_nmChKeepAwakeReason : 52|4@1+ (1,0) [1|15] "" Vector__XXX

BO_ 707 VCRIGHT_windowStatus: 8 VCRIGHT
 SG_ VCRIGHT_windowStatusIndex M : 0|1@1+ (1,0) [0|1] "" Vector__XXX
 SG_ VCRIGHT_windowStateRF m0 : 1|4@1+ (1,0) [0|15] "" Vector__XXX
 SG_ VCRIGHT_windowTrimClearMoveReque m0 : 5|2@1+ (1,0) [0|3] "" Vector__XXX
 SG_ VCRIGHT_windowDutyRF m0 : 8|6@1- (5,0) [-100|100] "%" Vector__XXX
 SG_ VCRIGHT_windowTrimClearActiveReq m0 : 14|2@1+ (1,0) [1|3] "" Vector__XXX
 SG_ VCRIGHT_windowCurrentRF m0 : 16|6@1- (0.5,0) [-15|15] "A" Vector__XXX
 SG_ VCRIGHT_windowPositionRF m0 : 22|9@1- (1.25,265) [-50|580] "mm" Vector__XXX
 SG_ VCRIGHT_windowCalibratedRF m0 : 32|1@1+ (1,0) [0|1] "" Vector__XXX
 SG_ VCRIGHT_windowStateRR m0 : 33|4@1+ (1,0) [0|15] "" Vector__XXX
 SG_ VCRIGHT_windowDutyRR m0 : 40|6@1- (5,0) [-100|100] "%" Vector__XXX
 SG_ VCRIGHT_windowCurrentRR m0 : 48|6@1- (0.5,0) [-15|15] "A" Vector__XXX
 SG_ VCRIGHT_windowPositionRR m0 : 54|9@1- (1.25,265) [-50|580] "mm" Vector__XXX
 SG_ VCRIGHT_windowCalibratedRR m0 : 63|1@1+ (1,0) [0|1] "" Vector__XXX
 SG_ VCRIGHT_windowThermalTCRF m1 : 1|8@1+ (1,0) [0|255] "s" Vector__XXX
 SG_ VCRIGHT_windowThermalModeRF m1 : 9|2@1+ (1,0) [1|3] "" Vector__XXX
 SG_ VCRIGHT_windowStopReasonRF m1 : 11|3@1+ (1,0) [0|7] "" Vector__XXX
 SG_ VCRIGHT_windowStopReqReasonRF m1 : 14|4@1+ (1,0) [0|15] "" Vector__XXX
 SG_ VCRIGHT_windowThermalTCRR m1 : 18|8@1+ (1,0) [0|255] "s" Vector__XXX
 SG_ VCRIGHT_windowThermalModeRR m1 : 26|2@1+ (1,0) [1|3] "" Vector__XXX
 SG_ VCRIGHT_windowStopReasonRR m1 : 28|3@1+ (1,0) [0|7] "" Vector__XXX
 SG_ VCRIGHT_windowStopReqReasonRR m1 : 31|4@1+ (1,0) [0|15] "" Vector__XXX
 SG_ VCRIGHT_windowControlStateRF m1 : 35|2@1+ (1,0) [0|3] "" Vector__XXX
 SG_ VCRIGHT_windowCtrlUnavailableRF m1 : 38|3@1+ (1,0) [0|7] "" Vector__XXX
 SG_ VCRIGHT_windowControlStateRR m1 : 42|2@1+ (1,0) [0|3] "" Vector__XXX
 SG_ VCRIGHT_windowCtrlUnavailableRR m1 : 45|3@1+ (1,0) [0|7] "" Vector__XXX
 SG_ VCRIGHT_windowPositionStateRF m1 : 49|3@1+ (1,0) [0|7] "" Vector__XXX
 SG_ VCRIGHT_windowPositionStateRR m1 : 52|3@1+ (1,0) [0|7] "" Vector__XXX
 SG_ VCRIGHT_windowVehGearStateRF m1 : 56|2@1+ (1,0) [1|3] "" Vector__XXX
 SG_ VCRIGHT_windowVehGearStateRR m1 : 58|2@1+ (1,0) [1|3] "" Vector__XXX
 SG_ VCRIGHT_windowSpeedTableStatusRF m1 : 60|2@1+ (1,0) [1|3] "" Vector__XXX
 SG_ VCRIGHT_windowSpeedTableStatusRR m1 : 62|2@1+ (1,0) [1|3] "" Vector__XXX

BO_TX_BU_ 755 : GTW;
BO_TX_BU_ 777 : GTW;
BO_TX_BU_ 1523 : GTW;
BO_TX_BU_ 948 : GTW;
BO_TX_BU_ 827 : GTW;
BO_TX_BU_ 661 : GTW;
BO_TX_BU_ 826 : GTW;
BO_TX_BU_ 723 : GTW;
BO_TX_BU_ 851 : GTW;
BO_TX_BU_ 663 : GTW;
BO_TX_BU_ 627 : GTW;
BO_TX_BU_ 1285 : UMC;
BO_TX_BU_ 1847 : VCFRONT;
BO_TX_BU_ 700 : VCFRONT;
BO_TX_BU_ 577 : VCFRONT;
BO_TX_BU_ 1014 : VCFRONT;
BO_TX_BU_ 1013 : VCFRONT;
BO_TX_BU_ 721 : VCFRONT;
BO_TX_BU_ 957 : VCFRONT;
BO_TX_BU_ 801 : VCFRONT;
BO_TX_BU_ 1349 : VCFRONT;
BO_TX_BU_ 507 : VCLEFT;
BO_TX_BU_ 290 : VCLEFT;
BO_TX_BU_ 1186 : VCLEFT;
BO_TX_BU_ 642 : VCLEFT;
BO_TX_BU_ 1860 : VCLEFT;
BO_TX_BU_ 610 : VCLEFT;
BO_TX_BU_ 386 : VCLEFT;
BO_TX_BU_ 706 : VCLEFT;
BO_TX_BU_ 643 : VCRIGHT;
BO_TX_BU_ 291 : VCRIGHT;
BO_TX_BU_ 524 : VCRIGHT;
BO_TX_BU_ 1675 : VCRIGHT;
BO_TX_BU_ 995 : VCRIGHT;
BO_TX_BU_ 1859 : VCRIGHT;
BO_TX_BU_ 899 : VCRIGHT;
BO_TX_BU_ 1059 : VCRIGHT;
BO_TX_BU_ 707 : VCRIGHT;
CM_ BO_ 755 "Touchscreen user interface computer message: hvac request; forwarded onto this bus by the gateway; frame length observed on a vehicle bus";
CM_ SG_ 755 UI_hvacReqTempSetpointLeft "HVAC left set temperature.";
CM_ SG_ 755 UI_hvacReqAutoBlowerLevel "Reports the auto Heating, Ventilation, and Air Conditioning (HVAC) speed aggressiveness setting.";
CM_ SG_ 755 UI_hvacReqTempSetpointRight "HVAC right set temperature.";
CM_ SG_ 755 UI_hvacReqAirDistributionMode "Request for air distribution mode.";
CM_ SG_ 755 UI_hvacReqBlowerSegment "HVAC manual blower request (GUI_hvacManualBlowerRequest)";
CM_ SG_ 755 UI_hvacReqRecirc "HVAC recirculation mode";
CM_ SG_ 755 UI_hvacReqACDisable "Request to disable AC.";
CM_ SG_ 755 UI_hvacDefogState "HVAC defog state.";
CM_ SG_ 755 UI_hvacReqUserPowerState "Reports HVAC power state.";
CM_ SG_ 755 UI_hvacReqSecondRowState "HVAC rear fan request speed.";
CM_ SG_ 755 UI_hvacUseModeledDuctTemp "Touchscreen user interface computer: hvac use modeled duct temp";
CM_ SG_ 755 UI_hvacReqKeepClimateOn "Request accessory power";
CM_ SG_ 755 UI_hvacReqBioWeaponDefMode "Request for BioWeapon Defense Mode";
CM_ SG_ 755 UI_hvacLatchPassengerPresent "Touchscreen user interface computer: hvac latch passenger present";
CM_ SG_ 755 UI_enableHvacControlsFeatures1 "Touchscreen user interface computer: enable hvac controls features1";
CM_ SG_ 755 UI_enableHvacNotifications "Touchscreen user interface computer: enable hvac notifications";
CM_ SG_ 755 UI_hvacPhoneCallAirFlowAdjustEna "Touchscreen user interface computer: hvac phone call air flow adjust enabled";
CM_ SG_ 755 UI_enableHvacVOCPurgeRoutine "Touchscreen user interface computer: enable hvac VOC purge routine";
CM_ SG_ 755 UI_enableCustomerTHSAlerts "Touchscreen user interface computer: enable customer THS alerts";
CM_ SG_ 755 UI_evapDryingSelectiveEnable "Touchscreen user interface computer: evap drying selective enable";
CM_ SG_ 755 UI_enableHvacWeatherDataBasedHum "Touchscreen user interface computer: enable hvac weather data based humidity controls";
CM_ SG_ 755 UI_hvacReqTempSetpointCOP "HVAC cabin overheat protection set temperature.";
CM_ SG_ 755 UI_hvacClimateNudgeStatus "Touchscreen user interface computer: hvac climate nudge status";
CM_ SG_ 755 UI_enableHvacControlsFeatures2 "Touchscreen user interface computer: enable hvac controls features2";
CM_ SG_ 755 UI_enableHvacAPFoggingMonitor "Touchscreen user interface computer: enable hvac AP fogging monitor";
CM_ SG_ 755 UI_enableHvacLimpMode "Touchscreen user interface computer: enable hvac limp mode";
CM_ BO_ 777 "Touchscreen user interface computer message: location status; forwarded onto this bus by the gateway; frame length from the layout, not yet observed on a vehicle bus";
CM_ SG_ 777 UI_latitude "Touchscreen user interface computer: latitude";
CM_ SG_ 777 UI_longitude "Touchscreen user interface computer: longitude";
CM_ SG_ 777 UI_gpsAccuracy "Touchscreen user interface computer: gps accuracy; raw 127 = signal not available (SNA)";
CM_ BO_ 1523 "Touchscreen user interface computer message: odo; forwarded onto this bus by the gateway; frame length observed on a vehicle bus";
CM_ SG_ 1523 UI_odometer "Odometer; raw 16777215 = signal not available (SNA)";
CM_ BO_ 948 "Touchscreen user interface computer message: peripheral power requests; forwarded onto this bus by the gateway; frame length from the layout, not yet observed on a vehicle bus";
CM_ SG_ 948 UI_usbFrontHubPowerStateRequest "Reports the Universal Serial Bus (USB) Hub power request; raw 0 = signal not available (SNA)";
CM_ BO_ 827 "Touchscreen user interface computer message: power estimates; forwarded onto this bus by the gateway; frame length from the layout, not yet observed on a vehicle bus";
CM_ SG_ 827 UI_idlePowerConsumption "Power consumption when idle";
CM_ SG_ 827 UI_chargeTimeUntilTerminationPct "Charge time minutes until reached uSoe target; raw 2047 = signal not available (SNA)";
CM_ SG_ 827 UI_isTripChargingActive "Touchscreen user interface computer: is trip charging active";
CM_ SG_ 827 UI_chargeTimeUntilReadyToDepart "Charge time minutes until enough energy to depart for rest of trip; raw 2047 = signal not available (SNA)";
CM_ BO_ 661 "Touchscreen user interface computer message: power rationality config; forwarded onto this bus by the gateway; frame length observed on a vehicle bus";
CM_ SG_ 661 UI_powerRationalityConfigIndex "Touchscreen user interface computer: power rationality config index";
CM_ SG_ 661 UI_vcleftCfgRationalityThreshold "Touchscreen user interface computer: vcleft cfg rationality threshold0; raw 0 = signal not available (SNA)";
CM_ SG_ 661 UI_vcleftCfgRationalityTime0 "Touchscreen user interface computer: vcleft cfg rationality time0; raw 0 = signal not available (SNA)";
CM_ SG_ 661 UI_vcleftCfgRationalityThre_0001 "Touchscreen user interface computer: vcleft cfg rationality threshold1; raw 0 = signal not available (SNA)";
CM_ SG_ 661 UI_vcleftCfgRationalityTime1 "Touchscreen user interface computer: vcleft cfg rationality time1; raw 0 = signal not available (SNA)";
CM_ SG_ 661 UI_vcleftCfgRationalityStaticA "Touchscreen user interface computer: vcleft cfg rationality static a; raw 65535 = signal not available (SNA)";
CM_ SG_ 661 UI_vcleftCfgRationalityStaticB "Touchscreen user interface computer: vcleft cfg rationality static b; raw 32768 = signal not available (SNA)";
CM_ SG_ 661 UI_vcleftCfgRationalityStaticC "Touchscreen user interface computer: vcleft cfg rationality static c; raw 32768 = signal not available (SNA)";
CM_ SG_ 661 UI_vcleftCfgRationalityDynamicA "Touchscreen user interface computer: vcleft cfg rationality dynamic a; raw 65535 = signal not available (SNA)";
CM_ SG_ 661 UI_vcleftCfgRationalityDynamicB "Touchscreen user interface computer: vcleft cfg rationality dynamic b; raw 32768 = signal not available (SNA)";
CM_ SG_ 661 UI_vcleftCfgRationalityDynamicC "Touchscreen user interface computer: vcleft cfg rationality dynamic c; raw 32768 = signal not available (SNA)";
CM_ SG_ 661 UI_vcrightCfgRationalityThreshol "Touchscreen user interface computer: vcright cfg rationality threshold0; raw 0 = signal not available (SNA)";
CM_ SG_ 661 UI_vcrightCfgRationalityTime0 "Touchscreen user interface computer: vcright cfg rationality time0; raw 0 = signal not available (SNA)";
CM_ SG_ 661 UI_vcrightCfgRationalityThr_0001 "Touchscreen user interface computer: vcright cfg rationality threshold1; raw 0 = signal not available (SNA)";
CM_ SG_ 661 UI_vcrightCfgRationalityTime1 "Touchscreen user interface computer: vcright cfg rationality time1; raw 0 = signal not available (SNA)";
CM_ SG_ 661 UI_vcrightCfgRationalityStaticA "Touchscreen user interface computer: vcright cfg rationality static a; raw 65535 = signal not available (SNA)";
CM_ SG_ 661 UI_vcrightCfgRationalityStaticB "Touchscreen user interface computer: vcright cfg rationality static b; raw 32768 = signal not available (SNA)";
CM_ SG_ 661 UI_vcrightCfgRationalityStaticC "Touchscreen user interface computer: vcright cfg rationality static c; raw 32768 = signal not available (SNA)";
CM_ SG_ 661 UI_vcrightCfgRationalityDynamicA "Touchscreen user interface computer: vcright cfg rationality dynamic a; raw 65535 = signal not available (SNA)";
CM_ SG_ 661 UI_vcrightCfgRationalityDynamicB "Touchscreen user interface computer: vcright cfg rationality dynamic b; raw 32768 = signal not available (SNA)";
CM_ SG_ 661 UI_vcrightCfgRationalityDynamicC "Touchscreen user interface computer: vcright cfg rationality dynamic c; raw 32768 = signal not available (SNA)";
CM_ SG_ 661 UI_vcleftCfgCutoffThreshold0 "Touchscreen user interface computer: vcleft cfg cutoff threshold0; raw 0 = signal not available (SNA)";
CM_ SG_ 661 UI_vcleftCfgCutoffTime0 "Touchscreen user interface computer: vcleft cfg cutoff time0; raw 0 = signal not available (SNA)";
CM_ SG_ 661 UI_vcleftCfgCutoffThreshold1 "Touchscreen user interface computer: vcleft cfg cutoff threshold1; raw 0 = signal not available (SNA)";
CM_ SG_ 661 UI_vcleftCfgCutoffTime1 "Touchscreen user interface computer: vcleft cfg cutoff time1; raw 0 = signal not available (SNA)";
CM_ SG_ 661 UI_vcleftCfgCutoffStaticA "Touchscreen user interface computer: vcleft cfg cutoff static a; raw 65535 = signal not available (SNA)";
CM_ SG_ 661 UI_vcleftCfgCutoffStaticB "Touchscreen user interface computer: vcleft cfg cutoff static b; raw 32768 = signal not available (SNA)";
CM_ SG_ 661 UI_vcleftCfgCutoffStaticC "Touchscreen user interface computer: vcleft cfg cutoff static c; raw 32768 = signal not available (SNA)";
CM_ SG_ 661 UI_vcleftCfgCutoffDynamicA "Touchscreen user interface computer: vcleft cfg cutoff dynamic a; raw 65535 = signal not available (SNA)";
CM_ SG_ 661 UI_vcleftCfgCutoffDynamicB "Touchscreen user interface computer: vcleft cfg cutoff dynamic b; raw 32768 = signal not available (SNA)";
CM_ SG_ 661 UI_vcleftCfgCutoffDynamicC "Touchscreen user interface computer: vcleft cfg cutoff dynamic c; raw 32768 = signal not available (SNA)";
CM_ SG_ 661 UI_vcrightCfgCutoffThreshold0 "Touchscreen user interface computer: vcright cfg cutoff threshold0; raw 0 = signal not available (SNA)";
CM_ SG_ 661 UI_vcrightCfgCutoffTime0 "Touchscreen user interface computer: vcright cfg cutoff time0; raw 0 = signal not available (SNA)";
CM_ SG_ 661 UI_vcrightCfgCutoffThreshold1 "Touchscreen user interface computer: vcright cfg cutoff threshold1; raw 0 = signal not available (SNA)";
CM_ SG_ 661 UI_vcrightCfgCutoffTime1 "Touchscreen user interface computer: vcright cfg cutoff time1; raw 0 = signal not available (SNA)";
CM_ SG_ 661 UI_vcrightCfgCutoffStaticA "Touchscreen user interface computer: vcright cfg cutoff static a; raw 65535 = signal not available (SNA)";
CM_ SG_ 661 UI_vcrightCfgCutoffStaticB "Touchscreen user interface computer: vcright cfg cutoff static b; raw 32768 = signal not available (SNA)";
CM_ SG_ 661 UI_vcrightCfgCutoffStaticC "Touchscreen user interface computer: vcright cfg cutoff static c; raw 32768 = signal not available (SNA)";
CM_ SG_ 661 UI_vcrightCfgCutoffDynamicA "Touchscreen user interface computer: vcright cfg cutoff dynamic a; raw 65535 = signal not available (SNA)";
CM_ SG_ 661 UI_vcrightCfgCutoffDynamicB "Touchscreen user interface computer: vcright cfg cutoff dynamic b; raw 32768 = signal not available (SNA)";
CM_ SG_ 661 UI_vcrightCfgCutoffDynamicC "Touchscreen user interface computer: vcright cfg cutoff dynamic c; raw 32768 = signal not available (SNA)";
CM_ BO_ 826 "Touchscreen user interface computer message: range; forwarded onto this bus by the gateway; frame length observed on a vehicle bus";
CM_ SG_ 826 UI_ratedRange "Rated range in miles";
CM_ SG_ 826 UI_whpm "Touchscreen user interface computer: whpm";
CM_ SG_ 826 UI_soe "State of energy";
CM_ SG_ 826 UI_uSoe "Usable state of energy";
CM_ SG_ 826 UI_softPackLimitPct "Touchscreen user interface computer: soft pack limit pct";
CM_ SG_ 826 UI_targetFullPackEnergy "Touchscreen user interface computer: target full pack energy";
CM_ BO_ 723 "Touchscreen user interface computer message: solar data; forwarded onto this bus by the gateway; frame length observed on a vehicle bus";
CM_ SG_ 723 UI_solarAzimuthAngle "Touchscreen user interface computer: solar azimuth angle; raw 32768 = signal not available (SNA)";
CM_ SG_ 723 UI_solarAzimuthAngleCarRef "Touchscreen user interface computer: solar azimuth angle car ref; raw 255 = signal not available (SNA)";
CM_ SG_ 723 UI_isSunUp "is sun up; raw 3 = signal not available (SNA)";
CM_ SG_ 723 UI_solarElevationAngle "Solar Elevation Angle; raw 127 = signal not available (SNA)";
CM_ SG_ 723 UI_screenPCBTemperature "Temperature of display PCB";
CM_ SG_ 723 UI_minsToSunset "time until to sunset";
CM_ SG_ 723 UI_minsToSunrise "time until to sunrise";
CM_ BO_ 851 "Touchscreen user interface computer message: status; forwarded onto this bus by the gateway; frame length observed on a vehicle bus";
CM_ SG_ 851 UI_touchActive "No touchscreen errors";
CM_ SG_ 851 UI_audioActive "Audio system is ready.";
CM_ SG_ 851 UI_bluetoothActive "Touchscreen user interface computer: bluetooth active";
CM_ SG_ 851 UI_cellActive "Cell is powered";
CM_ SG_ 851 UI_displayReady "UI is ready (GUI_allReady) and display is ok (GUI_displayHardwareOK)";
CM_ SG_ 851 UI_displayOn "UI display on/off status";
CM_ SG_ 851 UI_wifiActive "WiFi active.";
CM_ SG_ 851 UI_wifiConnected "WiFi Connected.";
CM_ SG_ 851 UI_systemActive "Touchscreen user interface computer: system active";
CM_ SG_ 851 UI_readyForDrive "Ready for drive (UI ready or self park request)";
CM_ SG_ 851 UI_cellConnected "Detects if the cell is connected to a network.";
CM_ SG_ 851 UI_vpnActive "VPN connected.";
CM_ SG_ 851 UI_autopilotTrial "Touchscreen user interface computer: autopilot trial";
CM_ SG_ 851 UI_factoryReset "UI request for factory reset; raw 0 = signal not available (SNA)";
CM_ SG_ 851 UI_gpsActive "GPS has valid fix";
CM_ SG_ 851 UI_screenshotActive "Touchscreen user interface computer: screenshot active";
CM_ SG_ 851 UI_radioActive "Touchscreen user interface computer: radio active";
CM_ SG_ 851 UI_cellNetworkTechnology "Describes the type of cellular network to which the car computer is connected: GPRS_2G(114Kbps) < EGDE_2G(368Kbps) < 3G(3Mbps) < HSDPA_3G(14Mbps) < HSPAplus_4Gg(168Mbps) < 4G_LTE(299Mbps); raw 15 = signal not available (SNA)";
CM_ SG_ 851 UI_cellReceiverPower "Touchscreen user interface computer: cell receiver power";
CM_ SG_ 851 UI_falseTouchCounter "Count false touches after display is off.";
CM_ SG_ 851 UI_developmentCar "Touchscreen user interface computer: development car";
CM_ SG_ 851 UI_cameraActive "Touchscreen user interface computer: camera active";
CM_ SG_ 851 UI_cellSignalBars "Number of cellular signal bars displayed on the UI, derived from cellSignalStrength; raw 7 = signal not available (SNA)";
CM_ SG_ 851 UI_trailerModeTelltale "Color of the trailer mode telltale";
CM_ SG_ 851 UI_pcbTemperature "PCB digital temp sensor reading in DegC";
CM_ SG_ 851 UI_cpuTemperature "Apollo Lake SOC temperature in DegC";
CM_ BO_ 663 "Touchscreen user interface computer message: suspension control; forwarded onto this bus by the gateway; frame length from the layout, not yet observed on a vehicle bus";
CM_ SG_ 663 UI_adaptiveRideRequest "UI customer adaptive ride request for air suspension.";
CM_ SG_ 663 UI_suspensionLoweringRequest "Touchscreen user interface computer: suspension lowering request; raw 3 = signal not available (SNA)";
CM_ SG_ 663 UI_geofenceLevelingRequest "Geofence level request from customer; raw 5 = signal not available (SNA)";
CM_ SG_ 663 UI_jackModeToggleRequest "Touchscreen user interface computer: jack mode toggle request";
CM_ SG_ 663 UI_adaptiveTuningRequest0 "Touchscreen user interface computer: adaptive tuning request0";
CM_ SG_ 663 UI_adaptiveTuningRequest1 "Touchscreen user interface computer: adaptive tuning request1";
CM_ SG_ 663 UI_roadRoughnessLookahead "Touchscreen user interface computer: road roughness lookahead; raw 127 = signal not available (SNA)";
CM_ SG_ 663 UI_roadRoughnessStart "Touchscreen user interface computer: road roughness start; raw 31 = signal not available (SNA)";
CM_ SG_ 663 UI_mapVersionUsed "Touchscreen user interface computer: map version used; raw 255 = signal not available (SNA)";
CM_ SG_ 663 UI_suspensionControlCounter "Touchscreen user interface computer: suspension control counter";
CM_ SG_ 663 UI_suspensionLevelRequest "Touchscreen user interface computer: suspension level request";
CM_ SG_ 663 UI_suspensionControlChecksum "Touchscreen user interface computer: suspension control checksum";
CM_ BO_ 627 "Touchscreen user interface computer message: vehicle control; forwarded onto this bus by the gateway; frame length observed on a vehicle bus";
CM_ SG_ 627 UI_powerStateRequest "Request accessory power";
CM_ SG_ 627 UI_childDoorLockOnRight "UI child door lock request status.";
CM_ SG_ 627 UI_frontFogSwitch "Request for front fog lights to be on";
CM_ SG_ 627 UI_summonActive "Summon is active";
CM_ SG_ 627 UI_frunkRequest "Request open frunk";
CM_ SG_ 627 UI_wiperMode "Wiper mode state; raw 0 = signal not available (SNA)";
CM_ SG_ 627 UI_steeringBacklightEnabled "Touchscreen user interface computer: steering backlight enabled";
CM_ SG_ 627 UI_steeringButtonMode "Steering wheel control mode";
CM_ SG_ 627 UI_walkUpUnlock "Walk up unlock request (datavalue defaults to false)";
CM_ SG_ 627 UI_walkAwayLock "Walk away door lock setting.";
CM_ SG_ 627 UI_unlockOnPark "Unlock on park setting";
CM_ SG_ 627 UI_globalUnlockOn "Global Unlock Setting";
CM_ SG_ 627 UI_childDoorLockOnLeft "UI child door lock request status.";
CM_ SG_ 627 UI_lockRequest "Lock or unlock request; raw 7 = signal not available (SNA)";
CM_ SG_ 627 UI_alarmEnabled "UI customer level request to enable alarm.";
CM_ SG_ 627 UI_intrusionSensorOn "Touchscreen user interface computer: intrusion sensor on";
CM_ SG_ 627 UI_stop12vSupport "UI request to stop rails as 12v support";
CM_ SG_ 627 UI_rearFogSwitch "Request for rear fog lights to be on";
CM_ SG_ 627 UI_mirrorFoldRequest "Fold the mirrors; raw 3 = signal not available (SNA)";
CM_ SG_ 627 UI_mirrorHeatRequest "Customer usage of mirror heater and rear defrost";
CM_ SG_ 627 UI_remoteStartRequest "remote start or self park request; raw 4 = signal not available (SNA)";
CM_ SG_ 627 UI_seeYouHomeLightingOn "Headlights after exit";
CM_ SG_ 627 UI_powerOff "power off rails request.";
CM_ SG_ 627 UI_displayBrightnessLevel "UI brightness; raw 255 = signal not available (SNA)";
CM_ SG_ 627 UI_ambientLightingEnabled "Touchscreen user interface computer: ambient lighting enabled";
CM_ SG_ 627 UI_autoHighBeamEnabled "Enable Automatic High/Low Beams";
CM_ SG_ 627 UI_frontLeftSeatHeatReq "Request for front left seat heat";
CM_ SG_ 627 UI_frontRightSeatHeatReq "Request for front left seat heat";
CM_ SG_ 627 UI_rearLeftSeatHeatReq "UI request for second row left seat heater";
CM_ SG_ 627 UI_rearCenterSeatHeatReq "UI request for second row middle seat heater";
CM_ SG_ 627 UI_rearRightSeatHeatReq "UI request for second row right seat heater";
CM_ SG_ 627 UI_autoFoldMirrorsOn "Enable Automatic Mirror Fold/Unfold";
CM_ SG_ 627 UI_mirrorDipOnReverse "Enable Mirror Dip On Reverse";
CM_ SG_ 627 UI_remoteClosureRequest "remote actuate trunk; raw 3 = signal not available (SNA)";
CM_ SG_ 627 UI_wiperRequest "Wiper speed; raw 0 = signal not available (SNA)";
CM_ SG_ 627 UI_domeLightSwitch "Dome light switch";
CM_ SG_ 627 UI_honkHorn "Touchscreen user interface computer: honk horn";
CM_ SG_ 627 UI_driveStateRequest "Touchscreen user interface computer: drive state request";
CM_ SG_ 627 UI_rearWindowLockout "Touchscreen user interface computer: rear window lockout";
CM_ BO_ 1285 "UMC ECU message: smart adapter info; frame length from the layout, not yet observed on a vehicle bus";
CM_ SG_ 1285 SA_infoIndex "UMC ECU: info index";
CM_ SG_ 1285 SA_genealogyVersion "UMC ECU: genealogy version";
CM_ SG_ 1285 SA_genealogyCrc "UMC ECU: genealogy crc";
CM_ SG_ 1285 SA_region "Reports the smart adapter region from Electrically Erasable Programmable Read-Only Memory (EEPROM).";
CM_ SG_ 1285 SA_OverTempThreshold "Reports the smart adapter overtemperature threshold from Electrically Erasable Programmable Read-Only Memory (EEPROM).";
CM_ SG_ 1285 SA_partNumInt "Reports the smart adapter part number integer representation.";
CM_ SG_ 1285 SA_partNumRev "Reports the smart adapter part number revision.";
CM_ SG_ 1285 SA_currentLimit "Reports the smart adapter current limit from Electrically Erasable Programmable Read-Only Memory (EEPROM).";
CM_ SG_ 1285 SA_l1Voltage "Reports the smart adapter nominal voltage request from Electrically Erasable Programmable Read-Only Memory (EEPROM).";
CM_ BO_ 1320 "Vector__XXX ECU message: unix time seconds; frame length observed on a vehicle bus";
CM_ SG_ 1320 UnixTimeSeconds "Vehicle clock, seconds since 1970-01-01 UTC";
CM_ BO_ 1847 "Front body controller message: LVBMS info; frame length observed on a vehicle bus";
CM_ SG_ 1847 VCFRONT_LVBMS_InfoIndex "Front body controller: LVBMS info index";
CM_ SG_ 1847 VCFRONT_LVBMS_PcbaId "Front body controller: LVBMS pcba id";
CM_ SG_ 1847 VCFRONT_LVBMS_AssemblyId "Front body controller: LVBMS assembly id";
CM_ SG_ 1847 VCFRONT_LVBMS_SubUsageId "LVBMS Sub Usage ID; raw 65535 = signal not available (SNA)";
CM_ SG_ 1847 VCFRONT_LVBMS_UsageId "Front body controller: LVBMS usage id";
CM_ SG_ 1847 VCFRONT_LVBMS_AppCRC "LVBMS application cyclic redundancy check";
CM_ SG_ 1847 VCFRONT_LVBMS_FWBuildType "Front body controller: LVBMS FW build type";
CM_ BO_ 700 "Front body controller message: LV thermal motors10 hz; frame length from the layout, not yet observed on a vehicle bus";
CM_ SG_ 700 VCFRONT_LVThermalMotorsIndex "Front body controller: LV thermal motors index";
CM_ SG_ 700 VCFRONT_radiatorFanState "Radiator Fan motor controller state";
CM_ SG_ 700 VCFRONT_radiatorFanTorque "Radiator Fan motor torque; raw 1023 = signal not available (SNA)";
CM_ SG_ 700 VCFRONT_radiatorFanIDc "Radiator Fan DC current; raw 127 = signal not available (SNA)";
CM_ SG_ 700 VCFRONT_mlxLINCurrentSchedule "Currently set schedule for MLX LIN bus";
CM_ SG_ 700 VCFRONT_pumpPowertrainState "Powertrain Pump motor controller state";
CM_ SG_ 700 VCFRONT_pumpPowertrainTorque "Powertrain Pump motor torque; raw 1023 = signal not available (SNA)";
CM_ SG_ 700 VCFRONT_pumpPowertrainIDc "Powertrain Pump DC current; raw 127 = signal not available (SNA)";
CM_ SG_ 700 VCFRONT_pumpBatteryState "Battery Pump motor controller state";
CM_ SG_ 700 VCFRONT_pumpBatteryTorque "Battery Pump motor torque; raw 1023 = signal not available (SNA)";
CM_ SG_ 700 VCFRONT_pumpBatteryIDc "Battery Pump DC current; raw 127 = signal not available (SNA)";
CM_ BO_ 577 "Front body controller message: coolant; frame length observed on a vehicle bus";
CM_ SG_ 577 VCFRONT_coolantFlowBatActual "Front body controller: coolant flow bat actual";
CM_ SG_ 577 VCFRONT_coolantFlowBatTarget "Front body controller: coolant flow bat target";
CM_ SG_ 577 VCFRONT_coolantFlowBatReason "Front body controller: coolant flow bat reason";
CM_ SG_ 577 VCFRONT_coolantFlowPTActual "Front body controller: coolant flow PT actual";
CM_ SG_ 577 VCFRONT_coolantFlowPTTarget "Front body controller: coolant flow PT target";
CM_ SG_ 577 VCFRONT_coolantFlowPTReason "Front body controller: coolant flow PT reason";
CM_ SG_ 577 VCFRONT_wasteHeatRequestType "Front body controller: waste heat request type";
CM_ SG_ 577 VCFRONT_coolantHasBeenFilled "Front body controller: coolant has been filled";
CM_ SG_ 577 VCFRONT_radiatorIneffective "Indication that the efficiency of the radiator is reduced";
CM_ SG_ 577 VCFRONT_coolantAirPurgeBatState "Front body controller: coolant air purge bat state";
CM_ SG_ 577 VCFRONT_coolantFlowTableConfig "Front body controller: coolant flow table config";
CM_ SG_ 577 VCFRONT_coolantLevelContinuously "Front body controller: coolant level continuously low";
CM_ BO_ 1014 "Front body controller message: light status; frame length observed on a vehicle bus";
CM_ SG_ 1014 VCFRONT_lowBeamLeftStatus "State of the left headlamp low beam light source; raw 3 = signal not available (SNA)";
CM_ SG_ 1014 VCFRONT_lowBeamRightStatus "State of the right headlamp low beam light source; raw 3 = signal not available (SNA)";
CM_ SG_ 1014 VCFRONT_highBeamLeftStatus "State of the left headlamp high beam light source; raw 3 = signal not available (SNA)";
CM_ SG_ 1014 VCFRONT_highBeamRightStatus "State of the right headlamp high beam light source; raw 3 = signal not available (SNA)";
CM_ SG_ 1014 VCFRONT_DRLLeftStatus "Status of the left daytime running light source; raw 3 = signal not available (SNA)";
CM_ SG_ 1014 VCFRONT_DRLRightStatus "Status of the right daytime running light source; raw 3 = signal not available (SNA)";
CM_ SG_ 1014 VCFRONT_fogLeftStatus "State of the left front fog light source; raw 3 = signal not available (SNA)";
CM_ SG_ 1014 VCFRONT_fogRightStatus "State of the right front fog light source; raw 3 = signal not available (SNA)";
CM_ SG_ 1014 VCFRONT_sideMarkersStatus "State of the side marker / auxiliary park light sources (left and right are on a shared HSD); raw 3 = signal not available (SNA)";
CM_ SG_ 1014 VCFRONT_sideRepeaterLeftStatus "State of the left side repeater light source; raw 3 = signal not available (SNA)";
CM_ SG_ 1014 VCFRONT_sideRepeaterRightStatus "State of the right side repeater light source; raw 3 = signal not available (SNA)";
CM_ SG_ 1014 VCFRONT_turnSignalLeftStatus "State of the left front turn signal light source; raw 3 = signal not available (SNA)";
CM_ SG_ 1014 VCFRONT_turnSignalRightStatus "State of the right front turn signal light source; raw 3 = signal not available (SNA)";
CM_ SG_ 1014 VCFRONT_parkLeftStatus "State of the left position/park light source; raw 3 = signal not available (SNA)";
CM_ SG_ 1014 VCFRONT_parkRightStatus "State of the right position/park light source; raw 3 = signal not available (SNA)";
CM_ SG_ 1014 VCFRONT_lowBeamLeftReadyForAimin "Front body controller: low beam left ready for aiming";
CM_ SG_ 1014 VCFRONT_lowBeamRightReadyForAimi "Front body controller: low beam right ready for aiming";
CM_ SG_ 1014 VCFRONT_lowBeamsOnForDRL "Shows if the low beam light source is being used to fulfil the daytime running light function (for Canada)";
CM_ SG_ 1014 VC_rightHeadlampHealth "Signal to report whether the right headlamp is powered and communicating";
CM_ SG_ 1014 VC_leftHeadlampHealth "Signal to report whether the left headlamp is powered and communicating";
CM_ SG_ 1014 VCFRONT_lightStatusMuxIndex "Front body controller: light status mux index";
CM_ SG_ 1014 VCFRONT_isAdaptiveHighBeamAvaila "Indication that the conditions (country code, hardware config, etc.) are acceptable to use the advanced driving beam feature.";
CM_ SG_ 1014 VCFRONT_isAdaptiveHighBeamFaulte "Detects if adaptive high beam functionality is unavailable or not operating as expected due to other dependencies.";
CM_ SG_ 1014 VCFRONT_isBendLightingAvailable "Detects if region and hardware conditions currently allow operation of the bend lighting feature.";
CM_ SG_ 1014 VCFRONT_advancedDrivingBeamStatu "Reports the current advanced driving beam system state.";
CM_ SG_ 1014 VCFRONT_headlampBendAngle "Measures the adaptive headlight bend angle.";
CM_ SG_ 1014 VCFRONT_headlampRoadClass "Reports the road class informing the use of dynamic low beams.";
CM_ BO_ 1013 "Front body controller message: lighting; frame length observed on a vehicle bus";
CM_ SG_ 1013 VCFRONT_indicatorLeftRequest "Front body controller: indicator left request";
CM_ SG_ 1013 VCFRONT_indicatorRightRequest "Front body controller: indicator right request";
CM_ SG_ 1013 VCFRONT_hazardLightRequest "Front body controller: hazard light request";
CM_ SG_ 1013 VCFRONT_ambientLightingBrightnes "Front body controller: ambient lighting brightnes; raw 255 = signal not available (SNA)";
CM_ SG_ 1013 VCFRONT_switchLightingBrightness "Front body controller: switch lighting brightness; raw 255 = signal not available (SNA)";
CM_ SG_ 1013 VCFRONT_courtesyLightingRequest "Flag to request courtesy lighting";
CM_ SG_ 1013 VCFRONT_hazardSwitchBacklight "Front body controller: hazard switch backlight";
CM_ SG_ 1013 VCFRONT_highBeamControlState "State of the virtual high beam stalk";
CM_ SG_ 1013 VCFRONT_dynamicBrakeLightState "Front body controller: dynamic brake light state";
CM_ SG_ 1013 VCFRONT_lightingCoreState "Core lighting state; raw 15 = signal not available (SNA)";
CM_ SG_ 1013 VCFRONT_intHighBeamsFunctionStat "State of the intermittent high beams lighting function";
CM_ SG_ 1013 VCFRONT_latchedHighBeamsFunction "State of the latched high beams lighting function";
CM_ SG_ 1013 VCFRONT_frontFogFunctionState "State of the front fog lighting function";
CM_ SG_ 1013 VCFRONT_headlightsReadyOrTimedOu "Front body controller: headlights ready or timed out";
CM_ SG_ 1013 VCFRONT_turnIndicatorStalk "Front body controller: turn indicator stalk; raw 3 = signal not available (SNA)";
CM_ SG_ 1013 VCFRONT_highBeamLatchingState "State of high beam latching; raw 0 = signal not available (SNA)";
CM_ SG_ 1013 VCFRONT_lightingCustomState "Custom lighting mode substate";
CM_ SG_ 1013 VC_fastFlashHazardsActive "Front body controller: fast flash hazards active";
CM_ SG_ 1013 VCFRONT_indicatorLeftInternal "Front body controller: indicator left internal";
CM_ SG_ 1013 VCFRONT_indicatorRightInternal "Front body controller: indicator right internal";
CM_ BO_ 721 "Front body controller message: ok to use high power; frame length observed on a vehicle bus";
CM_ SG_ 721 VCFRONT_vcleftOkToUseHighPower "Front body controller: vcleft ok to use high power";
CM_ SG_ 721 VCFRONT_vcrightOkToUseHighPower "Front body controller: vcright ok to use high power";
CM_ SG_ 721 VCFRONT_das1OkToUseHighPower "Front body controller: das1 ok to use high power";
CM_ SG_ 721 VCFRONT_das2OkToUseHighPower "Front body controller: das2 ok to use high power";
CM_ SG_ 721 VCFRONT_MCULogicOkToUseHighPower "Front body controller: MCU logic ok to use high power";
CM_ SG_ 721 VCFRONT_MCUAudioOkToUseHighPower "Front body controller: MCU audio ok to use high power";
CM_ SG_ 721 VCFRONT_cpOkToUseHighPower "Front body controller: cp ok to use high power";
CM_ SG_ 721 VCFRONT_premAudioOkToUseHiPower "Front body controller: prem audio ok to use hi power";
CM_ SG_ 721 VCFRONT_tasOkToUseHighPower "Front body controller: tas ok to use high power";
CM_ BO_ 957 "Front body controller message: parked energy loss; frame length observed on a vehicle bus";
CM_ SG_ 957 VCFRONT_energyLossIndex "Front body controller: energy loss index";
CM_ SG_ 957 VCFRONT_userEnergyLossSinceDrive "Energy loss due to user interaction since last drive";
CM_ SG_ 957 VCFRONT_preconditioningEner_0001 "Energy loss due to preconditioning since last drive";
CM_ SG_ 957 VCFRONT_cabinOverheatEnergy_0001 "Energy loss due to cabin overheat protection since last drive";
CM_ SG_ 957 VCFRONT_mobileAppEnergyLoss_0001 "Energy loss due to mobile app interaction since last drive";
CM_ SG_ 957 VCFRONT_summonStandbyEnergy_0001 "Energy loss due to summon standby since last drive";
CM_ SG_ 957 VCFRONT_sentryModeEnergyLos_0001 "Energy loss due to sentry mode since last drive";
CM_ SG_ 957 VCFRONT_backgroundEnergyLos_0001 "Energy loss due to background vehicle op since last drive";
CM_ SG_ 957 VCFRONT_evapDryingEnergyLos_0001 "Energy loss due to evap drying since last drive";
CM_ SG_ 957 VCFRONT_userEnergyLossSinceCharg "Energy loss due to user interaction since last charge";
CM_ SG_ 957 VCFRONT_preconditioningEnergyLos "Energy loss due to preconditioning since last charge";
CM_ SG_ 957 VCFRONT_cabinOverheatEnergyLossS "Energy loss due to cabin overheat protection since last charge";
CM_ SG_ 957 VCFRONT_mobileAppEnergyLossSince "Energy loss due to mobile app interaction since last charge";
CM_ SG_ 957 VCFRONT_summonStandbyEnergyLossS "Energy loss due to summon standby since last charge";
CM_ SG_ 957 VCFRONT_sentryModeEnergyLossSinc "Energy loss due to sentry mode since last charge";
CM_ SG_ 957 VCFRONT_backgroundEnergyLossSinc "Energy loss due to background vehicle op since last charge";
CM_ SG_ 957 VCFRONT_evapDryingEnergyLossSinc "Energy loss due to evap drying since last charge";
CM_ BO_ 801 "Front body controller message: sensors; frame length observed on a vehicle bus";
CM_ SG_ 801 VCFRONT_tempCoolantBatInlet "Battery measured inlet coolant temperature; raw 1023 = signal not available (SNA)";
CM_ SG_ 801 VCFRONT_tempCoolantPTInlet "Powertrain measured inlet coolant temperature; raw 2047 = signal not available (SNA)";
CM_ SG_ 801 VCFRONT_coolantLevel "Front body controller: coolant level";
CM_ SG_ 801 VCFRONT_brakeFluidLevel "Reports detected brake fluid level at the fluid reservoir; raw 0 = signal not available (SNA)";
CM_ SG_ 801 VCFRONT_tempAmbient "Front body controller: temp ambient; raw 0 = signal not available (SNA)";
CM_ SG_ 801 VCFRONT_washerFluidLevel "Indicates that the sensor has detected low windshield washer fluid; raw 0 = signal not available (SNA)";
CM_ SG_ 801 VCFRONT_tempAmbientFiltered "Filtered ambient temperature based on vehicle speed; raw 0 = signal not available (SNA)";
CM_ SG_ 801 VCFRONT_battSensorIrrational "Front body controller: batt sensor irrational";
CM_ SG_ 801 VCFRONT_ptSensorIrrational "Front body controller: pt sensor irrational";
CM_ SG_ 801 VCFRONT_sensorsCounter "Front body controller: sensors counter";
CM_ SG_ 801 VCFRONT_sensorsChecksum "Front body controller: sensors checksum";
CM_ BO_ 1349 "Front body controller message: system status; frame length observed on a vehicle bus";
CM_ SG_ 1349 VCFRONT_systemStatusMuxIndex "Front body controller: system status mux index";
CM_ SG_ 1349 VCFRONT_systemStatusCounter "Front body controller: system status counter";
CM_ SG_ 1349 VCFRONT_systemStatusChecksum "Front body controller: system status checksum";
CM_ SG_ 1349 VCFRONT_loadShedReason "Front body controller: load shed reason";
CM_ SG_ 1349 VCFRONT_VCRightEFuseLoadShedStag "Front body controller: VC right e fuse load shed stage";
CM_ SG_ 1349 VCFRONT_VCLeftEFuseLoadShedStage "Front body controller: VC left e fuse load shed stage";
CM_ SG_ 1349 VCFRONT_DCDCSaturationLoadShedSt "Front body controller: DCDC saturation load shed stage";
CM_ SG_ 1349 VCFRONT_vehicleLoadShedStage "Front body controller: vehicle load shed stage";
CM_ SG_ 1349 VCFRONT_HVFaultVehicleLoadShedRe "Front body controller: HV fault vehicle load shed request";
CM_ SG_ 1349 VCFRONT_postCrashVehicleLoadShed "Front body controller: post crash vehicle load shed active";
CM_ SG_ 1349 VCFRONT_HVFaultVehicleLoadShedAc "Front body controller: HV fault vehicle load shed active";
CM_ SG_ 1349 VCFRONT_factoryVehicleLoadShedAc "Indicates that vehicle is factory load shedding";
CM_ SG_ 1349 VCFRONT_anyVehicleLoadShedActive "Front body controller: any vehicle load shed active";
CM_ SG_ 1349 VCFRONT_DIVehLoadShedActive "Front body controller: DI veh load shed active";
CM_ SG_ 1349 VCFRONT_HVFaultLoadShedStateDBG "Front body controller: HV fault load shed state DBG";
CM_ SG_ 1349 VCFRONT_LVUnhealthyVehicleLoadSh "Front body controller: LV unhealthy vehicle load shed active";
CM_ SG_ 1349 VCFRONT_loadShedStsCondenserFan "Front body controller: load shed sts condenser fan";
CM_ SG_ 1349 VCFRONT_loadShedStsPTPump "Front body controller: load shed sts PT pump";
CM_ SG_ 1349 VCFRONT_loadShedMCUAudio "Front body controller: load shed MCU audio";
CM_ SG_ 1349 VCFRONT_loadShedHVDownTriggerDBG "Front body controller: load shed HV down trigger DBG";
CM_ SG_ 1349 VCFRONT_loadShedPCSSatTriggerDBG "Front body controller: load shed PCS sat trigger DBG";
CM_ SG_ 1349 VCFRONT_loadShedStsBatteryPump "Front body controller: load shed sts battery pump";
CM_ SG_ 1349 VCFRONT_loadShedStsAPGlassHeater "Front body controller: load shed sts AP glass heater";
CM_ SG_ 1349 VCFRONT_loadShedStsMCUGraphics "Front body controller: load shed sts MCU graphics";
CM_ SG_ 1349 VCFRONT_IBSCurrentRMS_loadShed "Front body controller: IBS current RMS load shed";
CM_ SG_ 1349 VCFRONT_loadShedAhLeakyBktCntDBG "Front body controller: load shed ah leaky bkt cnt DBG";
CM_ SG_ 1349 VCFRONT_loadShedPcs "Front body controller: load shed pcs";
CM_ SG_ 1349 VCFRONT_loadShedGTWDownstrmRails "Front body controller: load shed GTW downstrm rails";
CM_ SG_ 1349 VCFRONT_loadShedPCSMIATriggerDBG "Front body controller: load shed PCSMIA trigger DBG";
CM_ SG_ 1349 VCFRONT_loadShedTAS "Front body controller: load shed TAS";
CM_ SG_ 1349 VCFRONT_loadShedBackStopBktCntDB "Front body controller: load shed back stop bkt cnt DBG";
CM_ SG_ 1349 VCFRONT_loadShedPCSLeakyBktCtDBG "Front body controller: load shed PCS leaky bkt ct DBG";
CM_ SG_ 1349 VCFRONT_loadShedUI "Front body controller: load shed UI";
CM_ SG_ 1349 VCFRONT_loadShedAutoPilot "Front body controller: load shed auto pilot";
CM_ BO_ 507 "Left body controller message: TLC status; frame length observed on a vehicle bus";
CM_ SG_ 507 VCLEFT_TLCStatusIndex "Left body controller: TLC status index";
CM_ SG_ 507 VCLEFT_TLCTemperature "Monitors board temperatures for electrical validation; raw 128 = signal not available (SNA)";
CM_ SG_ 507 VCLEFT_TLCLeftTurnVoltage "Reports voltage for analysis of in field issues; raw 255 = signal not available (SNA)";
CM_ SG_ 507 VCLEFT_TLCRightTurnVoltage "Reports voltage for analysis of in field issues; raw 255 = signal not available (SNA)";
CM_ SG_ 507 VCLEFT_TLCState_LeftTurn "Reports trailer light status; raw 5 = signal not available (SNA)";
CM_ SG_ 507 VCLEFT_TLCState_RightTurn "Reports trailer light status; raw 5 = signal not available (SNA)";
CM_ SG_ 507 VCLEFT_TLCState_Tail "Reports trailer light status; raw 5 = signal not available (SNA)";
CM_ SG_ 507 VCLEFT_TLCState_Stop "Reports trailer light status; raw 5 = signal not available (SNA)";
CM_ SG_ 507 VCLEFT_TLCState_Fog "Reports trailer light status; raw 5 = signal not available (SNA)";
CM_ SG_ 507 VCLEFT_TLCState_Reverse "Reports trailer light status; raw 5 = signal not available (SNA)";
CM_ BO_ 290 "Left body controller message: door status2; frame length observed on a vehicle bus";
CM_ SG_ 290 VCLEFT_doorStatus2Index "Left body controller: door status2 index";
CM_ SG_ 290 VCLEFT_frontLatchRelDuty "Front left door latch motor duty cycle.";
CM_ SG_ 290 VCLEFT_BPillarCameraHeaterState "Indicates the state of the left b-pillar camera heater; raw 0 = signal not available (SNA)";
CM_ SG_ 290 VCLEFT_doorLatchAjarSwitchVoltag "Door latch switch voltage feeding switch logic";
CM_ SG_ 290 VCLEFT_doorLatchAjarSwitchV_0001 "Door latch switch voltage feeding switch logic";
CM_ SG_ 290 VCLEFT_BPillarCameraHeaterCurren "Current drawn by the left b-pillar camera heater; raw 63 = signal not available (SNA)";
CM_ SG_ 290 VCLEFT_mirrorTiltXOffset "Communicates post calibration position offset of left side view mirror tilt horizontal position";
CM_ SG_ 290 VCLEFT_mirrorTiltYOffset "Communicates post calibration position offset of left side view mirror tilt vertical position";
CM_ BO_ 1186 "Left body controller message: etc bluetooth status; frame length from the layout, not yet observed on a vehicle bus";
CM_ SG_ 1186 VCLEFT_etcBluetoothStatus "Left body controller: etc bluetooth status";
CM_ BO_ 642 "Left body controller message: hvac blower feedback; frame length observed on a vehicle bus";
CM_ SG_ 642 VCLEFT_hvacBlowerFeedbackIndex "Left body controller: hvac blower feedback index";
CM_ SG_ 642 VCLEFT_hvacBlowerEnabled "Left body controller: hvac blower enabled";
CM_ SG_ 642 VCLEFT_hvacBlowerOutputDuty "Left body controller: hvac blower output duty; raw 127 = signal not available (SNA)";
CM_ SG_ 642 VCLEFT_hvacBlowerRPMTarget "Left body controller: hvac blower RPM target; raw 1023 = signal not available (SNA)";
CM_ SG_ 642 VCLEFT_hvacBlowerRPMActual "Blower speed feedback";
CM_ SG_ 642 VCLEFT_hvacBlowerTorque "Left body controller: hvac blower torque; raw 1023 = signal not available (SNA)";
CM_ SG_ 642 VCLEFT_hvacBlowerFETTemp "Left body controller: hvac blower FET temp; raw 127 = signal not available (SNA)";
CM_ SG_ 642 VCLEFT_hvacBlowerIDc "Left body controller: hvac blower i dc; raw 127 = signal not available (SNA)";
CM_ SG_ 642 VCLEFT_hvacBlowerInitd "Left body controller: hvac blower initd";
CM_ SG_ 642 VCLEFT_hvacBlowerFault "Left body controller: hvac blower fault";
CM_ SG_ 642 VCLEFT_hvacBlowerLimitFETTemps "Left body controller: hvac blower limit FET temps";
CM_ SG_ 642 VCLEFT_hvacBlowerPowerOn "Left body controller: hvac blower power on";
CM_ SG_ 642 VCLEFT_hvacBlowerMotorID "Reports the ID of the HVAC blower motor";
CM_ BO_ 1860 "Left body controller message: recall status; frame length observed on a vehicle bus";
CM_ SG_ 1860 VCLEFT_systemRecallStatus "Left body controller: system recall status; raw 0 = signal not available (SNA)";
CM_ SG_ 1860 VCLEFT_seatRecallStatus "Left body controller: seat recall status; raw 0 = signal not available (SNA)";
CM_ SG_ 1860 VCLEFT_columnRecallStatus "Left body controller: column recall status; raw 0 = signal not available (SNA)";
CM_ SG_ 1860 VCLEFT_mirrorRecallStatus "Recall status for the left side view mirror; raw 0 = signal not available (SNA)";
CM_ BO_ 610 "Left body controller message: steering column status; frame length observed on a vehicle bus";
CM_ SG_ 610 VCLEFT_steeringColumnSMState "Status of steering column state machine; raw 0 = signal not available (SNA)";
CM_ SG_ 610 VCLEFT_steeringColumnLastRequest "Left body controller: steering column last request; raw 0 = signal not available (SNA)";
CM_ SG_ 610 VCLEFT_steeringColumnUpDownDuty "Steering column tilt motor duty cycle";
CM_ SG_ 610 VCLEFT_steeringColumnInOutDuty "Steering column telescope motor duty cycle";
CM_ SG_ 610 VCLEFT_steeringColumnUpDownPos "Motor encoder value representing steering column tilt position";
CM_ SG_ 610 VCLEFT_steeringColumnInOutPos "Motor encoder value representing steering column telescope position";
CM_ SG_ 610 VCLEFT_steeringColumnUpDownAmps "Measures current used by the steering column tilt motor.";
CM_ SG_ 610 VCLEFT_steeringColumnInOutAmps "Measures current used by the steering column telescope motor.";
CM_ SG_ 610 VCLEFT_steeringColumnUpDownCalib "Left body controller: steering column up down calib";
CM_ SG_ 610 VCLEFT_steeringColumnInOutCalib "Left body controller: steering column in out calib";
CM_ SG_ 610 VCLEFT_steeringColumnUpDownTC "Left body controller: steering column up down TC";
CM_ SG_ 610 VCLEFT_steeringColumnInOutTC "Left body controller: steering column in out TC";
CM_ BO_ 386 "Left body controller message: thermal status; frame length from the layout, not yet observed on a vehicle bus";
CM_ SG_ 386 VCLEFT_hvac2RLeftLateralStatus "Left body controller: hvac2 r left lateral status";
CM_ SG_ 386 VCLEFT_hvac2RLeftVerticalStatus "Left body controller: hvac2 r left vertical status";
CM_ SG_ 386 VCLEFT_hvac2RRightLateralStatus "Left body controller: hvac2 r right lateral status";
CM_ SG_ 386 VCLEFT_hvac2RRightVerticalStatus "Left body controller: hvac2 r right vertical status";
CM_ SG_ 386 VCLEFT_hvac2RLeftLateralPosition "Left body controller: hvac2 r left lateral position";
CM_ SG_ 386 VCLEFT_hvac2RLeftVerticalPositio "Left body controller: hvac2 r left vertical position";
CM_ SG_ 386 VCLEFT_hvac2RRightLateralPositio "Left body controller: hvac2 r right lateral position";
CM_ SG_ 386 VCLEFT_hvac2RRightVerticalPositi "Left body controller: hvac2 r right vertical position";
CM_ BO_ 706 "Left body controller message: window status; frame length observed on a vehicle bus";
CM_ SG_ 706 VCLEFT_windowStatusIndex "Left body controller: window status index";
CM_ SG_ 706 VCLEFT_windowStateLF "Status of left front window motor";
CM_ SG_ 706 VCLEFT_windowTrimClearMoveReques "Requests whether windows should enter or exit trim clear. Signal only valid if Vehicle Controller Left (VCLEFT) is on driver side.";
CM_ SG_ 706 VCLEFT_windowDutyLF "Left body controller: window duty LF";
CM_ SG_ 706 VCLEFT_windowTrimClearActiveRequ "Reports whether window trim clear is active. Signal is only valid if Vehicle Controller Left (VCLEFT) is on driver side; raw 0 = signal not available (SNA)";
CM_ SG_ 706 VCLEFT_windowCurrentLF "Current drawn by left front window regulator";
CM_ SG_ 706 VCLEFT_windowPositionLF "Left body controller: window position LF; raw 1 = signal not available (SNA)";
CM_ SG_ 706 VCLEFT_windowCalibratedLF "Calibration status of left front window motor";
CM_ SG_ 706 VCLEFT_windowStateLR "Status of left rear window motor";
CM_ SG_ 706 VCLEFT_windowDutyLR "Left body controller: window duty LR";
CM_ SG_ 706 VCLEFT_windowCurrentLR "Current drawn by left rear window regulator";
CM_ SG_ 706 VCLEFT_windowPositionLR "Left body controller: window position LR";
CM_ SG_ 706 VCLEFT_windowCalibratedLR "Calibraiton status of left rear window motor";
CM_ SG_ 706 VCLEFT_windowThermalTCLF "Left body controller: window thermal TCLF";
CM_ SG_ 706 VCLEFT_windowThermalModeLF "Left body controller: window thermal mode LF; raw 0 = signal not available (SNA)";
CM_ SG_ 706 VCLEFT_windowStopReasonLF "Reason for left front window stopping motion";
CM_ SG_ 706 VCLEFT_windowStopReqReasonLF "Reason for left front window stopping motion";
CM_ SG_ 706 VCLEFT_windowThermalTCLR "Left body controller: window thermal TCLR";
CM_ SG_ 706 VCLEFT_windowThermalModeLR "Left body controller: window thermal mode LR; raw 0 = signal not available (SNA)";
CM_ SG_ 706 VCLEFT_windowStopReasonLR "Reason for left rear window stopping motion";
CM_ SG_ 706 VCLEFT_windowStopReqReasonLR "Reason for left rear window stopping motion";
CM_ SG_ 706 VCLEFT_windowControlStateLF "Window control state";
CM_ SG_ 706 VCLEFT_windowCtrlUnavailableLF "Window control unavailable reason";
CM_ SG_ 706 VCLEFT_windowControlStateLR "Window control state";
CM_ SG_ 706 VCLEFT_windowCtrlUnavailableLR "Window control unavailable reason";
CM_ SG_ 706 VCLEFT_windowPositionStateLF "Window position state";
CM_ SG_ 706 VCLEFT_windowPositionStateLR "Window position state";
CM_ SG_ 706 VCLEFT_windowVehGearStateLF "Window's interpretation of vehicle gear state; raw 0 = signal not available (SNA)";
CM_ SG_ 706 VCLEFT_windowVehGearStateLR "Window's interpretation of vehicle gear state; raw 0 = signal not available (SNA)";
CM_ SG_ 706 VCLEFT_windowSpeedTableStatusLF "Speed table build status of left front window; raw 0 = signal not available (SNA)";
CM_ SG_ 706 VCLEFT_windowSpeedTableStatusLR "Speed table build status of left rear window; raw 0 = signal not available (SNA)";
CM_ BO_ 643 "Right body controller message: PTC request; frame length observed on a vehicle bus";
CM_ SG_ 643 VCRIGHT_PTCLeftTargetPowerHV "Right body controller: PTC left target power HV";
CM_ SG_ 643 VCRIGHT_PTCRightTargetPowerHV "Right body controller: PTC right target power HV";
CM_ SG_ 643 VCRIGHT_PTCLeftTargetDuty "Right body controller: PTC left target duty";
CM_ SG_ 643 VCRIGHT_PTCRightTargetDuty "Right body controller: PTC right target duty";
CM_ SG_ 643 VCRIGHT_PTCFlagAllowOperation "Right body controller: PTC flag allow operation";
CM_ SG_ 643 VCRIGHT_PTCRequestMode "Right body controller: PTC request mode";
CM_ SG_ 643 VCRIGHT_PTCResistanceCheckEnable "Right body controller: PTC resistance check enable";
CM_ SG_ 643 VCRIGHT_PTCReset "Right body controller: PTC reset";
CM_ SG_ 643 VCRIGHT_PTCLeftDirectDriveIGBTO "Right body controller: PTC left direct drive IGBTO";
CM_ SG_ 643 VCRIGHT_PTCLeftDirectDriveIGBTC "Right body controller: PTC left direct drive IGBTC";
CM_ SG_ 643 VCRIGHT_PTCLeftDirectDriveIGBTI "Right body controller: PTC left direct drive IGBTI";
CM_ SG_ 643 VCRIGHT_PTCRightDirectDriveIGBTI "Right body controller: PTC right direct drive IGBTI";
CM_ SG_ 643 VCRIGHT_PTCRightDirectDriveIGBTC "Right body controller: PTC right direct drive IGBTC";
CM_ SG_ 643 VCRIGHT_PTCRightDirectDriveIGBTO "Right body controller: PTC right direct drive IGBTO";
CM_ BO_ 291 "Right body controller message: door status2; frame length observed on a vehicle bus";
CM_ SG_ 291 VCRIGHT_doorStatus2Index "Right body controller: door status2 index";
CM_ SG_ 291 VCRIGHT_frontLatchRelDuty "Front left door latch motor duty cycle.";
CM_ SG_ 291 VCRIGHT_BPillarCameraHeaterState "Indicates the state of the right b-pillar camera heater; raw 0 = signal not available (SNA)";
CM_ SG_ 291 VCRIGHT_doorLatchAjarSwitchVolta "Door latch switch voltage feeding switch logic";
CM_ SG_ 291 VCRIGHT_doorLatchAjarSwitch_0001 "Door latch switch voltage feeding switch logic";
CM_ SG_ 291 VCRIGHT_BPillarCameraHeaterCurre "Current drawn by the right b-pillar camera heater; raw 63 = signal not available (SNA)";
CM_ SG_ 291 VCRIGHT_mirrorTiltXOffset "Communicates post calibration position offset of right side view mirror tilt horizontal position";
CM_ SG_ 291 VCRIGHT_mirrorTiltYOffset "Communicates post calibration position offset of right side view mirror tilt vertical position";
CM_ BO_ 524 "Right body controller message: hvac request; frame length observed on a vehicle bus";
CM_ SG_ 524 VCRIGHT_wattsDemandEvap "Right body controller: watts demand evap";
CM_ SG_ 524 VCRIGHT_hvacEvapEnabled "Right body controller: hvac evap enabled";
CM_ SG_ 524 VCRIGHT_conditioningRequest "Right body controller: conditioning request";
CM_ SG_ 524 VCRIGHT_tempEvaporator "Evaporator temperature; raw 2047 = signal not available (SNA)";
CM_ SG_ 524 VCRIGHT_tempEvaporatorTarget "Evaporator temperature target; raw 255 = signal not available (SNA)";
CM_ SG_ 524 VCRIGHT_hvacBlowerSpeedRPMReq "Right body controller: hvac blower speed RPM req";
CM_ SG_ 524 VCRIGHT_hvacPerfTestRunning "Right body controller: hvac perf test running";
CM_ SG_ 524 VCRIGHT_evapPerformanceLow "Right body controller: evap performance low";
CM_ SG_ 524 VCRIGHT_tempAmbientRaw "Right body controller: temp ambient raw; raw 0 = signal not available (SNA)";
CM_ SG_ 524 VCRIGHT_hvacHeatingEnabledLeft "Right body controller: hvac heating enabled left";
CM_ SG_ 524 VCRIGHT_hvacHeatingEnabledRight "Right body controller: hvac heating enabled right";
CM_ SG_ 524 VCRIGHT_hvacPerfTestState "The HVAC performance test running state";
CM_ SG_ 524 VCRIGHT_hvacUnavailable "Right body controller: hvac unavailable";
CM_ SG_ 524 VCRIGHT_hvacBlowerRPMActualAP "Right body controller: hvac blower RPM actual AP";
CM_ SG_ 524 VCRIGHT_hvacEvapEnabledInColdAmb "Right body controller: hvac evap enabled in cold ambient";
CM_ BO_ 1675 "Right body controller message: hvac status2; frame length from the layout, not yet observed on a vehicle bus";
CM_ SG_ 1675 VCRIGHT_hvacSeat1RLCushionFanTrg "Right body controller: hvac seat1 RL cushion fan trgt";
CM_ SG_ 1675 VCRIGHT_hvacSeat1RLBackrestFanTr "Right body controller: hvac seat1 RL backrest fan trgt";
CM_ SG_ 1675 VCRIGHT_hvacSeat1RRCushionFanTrg "Right body controller: hvac seat1 RR cushion fan trgt";
CM_ SG_ 1675 VCRIGHT_hvacSeat1RRBackrestFanTr "Right body controller: hvac seat1 RR backrest fan trgt";
CM_ SG_ 1675 VCRIGHT_hvac2RActuatorsEnable "Right body controller: hvac2 r actuators enable";
CM_ SG_ 1675 VCRIGHT_hvac2RLeftLateralTarget "Right body controller: hvac2 r left lateral target";
CM_ SG_ 1675 VCRIGHT_hvac2RLeftVerticalTarget "Right body controller: hvac2 r left vertical target";
CM_ SG_ 1675 VCRIGHT_hvac2RRightLateralTarget "Right body controller: hvac2 r right lateral target";
CM_ SG_ 1675 VCRIGHT_hvac2RRightVerticalTarge "Right body controller: hvac2 r right vertical target";
CM_ BO_ 995 "Right body controller message: light status; frame length observed on a vehicle bus";
CM_ SG_ 995 VCRIGHT_brakeLightStatus "Status of rear right brake light source; raw 3 = signal not available (SNA)";
CM_ SG_ 995 VCRIGHT_tailLightStatus "Status of right tail (rear position) light source; raw 3 = signal not available (SNA)";
CM_ SG_ 995 VCRIGHT_turnSignalStatus "Status of rear right turn signal light source; raw 3 = signal not available (SNA)";
CM_ SG_ 995 VCRIGHT_reverseLightStatus "Status of the reverse light source(s); raw 3 = signal not available (SNA)";
CM_ SG_ 995 VCRIGHT_rearFogLightStatus "The desired on/off state of the rear fog light source(s); raw 3 = signal not available (SNA)";
CM_ SG_ 995 VCRIGHT_leftInteriorTrunkLightRe "Right body controller: left interior trunk light req";
CM_ SG_ 995 VCRIGHT_audioCurrentSpikeDetecte "Right body controller: audio current spike detected";
CM_ SG_ 995 VCRIGHT_fasciaReverseLightStatus "Status of fascia reverse lamp; raw 3 = signal not available (SNA)";
CM_ SG_ 995 VCRIGHT_fasciaRearFogStatus "Status of fascia rear fog lamp; raw 3 = signal not available (SNA)";
CM_ SG_ 995 VCRIGHT_fasciaTailLightStatus "Status of fascia tail lamp; raw 3 = signal not available (SNA)";
CM_ SG_ 995 VCRIGHT_fasciaLeftTurnSignalStat "Status of fascia left turn signal; raw 3 = signal not available (SNA)";
CM_ SG_ 995 VCRIGHT_fasciaRightTurnSignalSta "Status of fascia right turn signal; raw 3 = signal not available (SNA)";
CM_ SG_ 995 VCRIGHT_CHMSLLightStatus "Status of center high mount stop lamp; raw 3 = signal not available (SNA)";
CM_ BO_ 1859 "Right body controller message: recall status; frame length observed on a vehicle bus";
CM_ SG_ 1859 VCRIGHT_systemRecallStatus "Recall state of superset of body controls ECUs; raw 0 = signal not available (SNA)";
CM_ SG_ 1859 VCRIGHT_seatRecallStatus "Right body controller: seat recall status; raw 0 = signal not available (SNA)";
CM_ SG_ 1859 VCRIGHT_mirrorRecallStatus "Recall status for the right side view mirror; raw 0 = signal not available (SNA)";
CM_ BO_ 899 "Right body controller message: ths status; frame length observed on a vehicle bus";
CM_ SG_ 899 VCRIGHT_thsActive "Right body controller: ths active";
CM_ SG_ 899 VCRIGHT_thsTemperature "Tesla HVAC sensor temperature; raw 255 = signal not available (SNA)";
CM_ SG_ 899 VCRIGHT_thsState "Right body controller: ths state";
CM_ SG_ 899 VCRIGHT_thsLINCurrentSchedule "Right body controller: ths LIN current schedule";
CM_ SG_ 899 VCRIGHT_thsDetected "Tesla HVAC sensor connection is detected";
CM_ SG_ 899 VCRIGHT_thsHumidity "Tesla HVAC sensor humidity; raw 127 = signal not available (SNA)";
CM_ SG_ 899 VCRIGHT_estimatedVehicleSituatio "Right body controller: estimated vehicle situation";
CM_ SG_ 899 VCRIGHT_thsSolarLoadInfrared "Solar power hitting the vehicle in the infrared spectrum; raw 1023 = signal not available (SNA)";
CM_ SG_ 899 VCRIGHT_thsSolarLoadVisible "Solar power hitting the vehicle in the visible spectrum; raw 1023 = signal not available (SNA)";
CM_ SG_ 899 VCRIGHT_estimatedThsSolarLoad "Right body controller: estimated ths solar load; raw 1023 = signal not available (SNA)";
CM_ SG_ 899 VCRIGHT_hvacFastLoggingEnabled "Right body controller: hvac fast logging enabled";
CM_ BO_ 1059 "Right body controller message: veh nm; frame length observed on a vehicle bus";
CM_ SG_ 1059 VCRIGHT_nmGoingToSleep "Right body controller: nm going to sleep";
CM_ SG_ 1059 VCRIGHT_nmWakeUpBus "Right body controller: nm wake up bus";
CM_ SG_ 1059 VCRIGHT_nmKeepAwakeReason "Reason controller is preventing the vehicle from sleeping; raw 0 = signal not available (SNA)";
CM_ SG_ 1059 VCRIGHT_nmWakeUpReason "Right body controller: nm wake up reason";
CM_ SG_ 1059 VCRIGHT_nmDebugWakeUp "Right body controller: nm debug wake up";
CM_ SG_ 1059 VCRIGHT_nmEthKeepAwakeReason "Right body controller: nm eth keep awake reason; raw 0 = signal not available (SNA)";
CM_ SG_ 1059 VCRIGHT_nmChKeepAwakeReason "Right body controller: nm ch keep awake reason; raw 0 = signal not available (SNA)";
CM_ BO_ 707 "Right body controller message: window status; frame length observed on a vehicle bus";
CM_ SG_ 707 VCRIGHT_windowStatusIndex "Right body controller: window status index";
CM_ SG_ 707 VCRIGHT_windowStateRF "Status of right front window motor";
CM_ SG_ 707 VCRIGHT_windowTrimClearMoveReque "Reports a request for whether windows should enter or exit trim clear mode. Signal is only valid if Vehicle Controller Left (VCLEFT) is on driver side.";
CM_ SG_ 707 VCRIGHT_windowDutyRF "Right body controller: window duty RF";
CM_ SG_ 707 VCRIGHT_windowTrimClearActiveReq "Reports whether window trim clear is active. Signal is only valid if Vehicle Controller Left (VCLEFT) is on driver side; raw 0 = signal not available (SNA)";
CM_ SG_ 707 VCRIGHT_windowCurrentRF "Current drawn by left front window regulator";
CM_ SG_ 707 VCRIGHT_windowPositionRF "Right body controller: window position RF; raw 1 = signal not available (SNA)";
CM_ SG_ 707 VCRIGHT_windowCalibratedRF "Calibration status of right front window motor";
CM_ SG_ 707 VCRIGHT_windowStateRR "Status of right rear window motor";
CM_ SG_ 707 VCRIGHT_windowDutyRR "Right body controller: window duty RR";
CM_ SG_ 707 VCRIGHT_windowCurrentRR "Current drawn by left rear window regulator";
CM_ SG_ 707 VCRIGHT_windowPositionRR "Right body controller: window position RR";
CM_ SG_ 707 VCRIGHT_windowCalibratedRR "Calibration status of right rear window motor";
CM_ SG_ 707 VCRIGHT_windowThermalTCRF "Right body controller: window thermal TCRF";
CM_ SG_ 707 VCRIGHT_windowThermalModeRF "Right body controller: window thermal mode RF; raw 0 = signal not available (SNA)";
CM_ SG_ 707 VCRIGHT_windowStopReasonRF "Reason for right front window stopping motion";
CM_ SG_ 707 VCRIGHT_windowStopReqReasonRF "Reason for right front window stopping motion";
CM_ SG_ 707 VCRIGHT_windowThermalTCRR "Right body controller: window thermal TCRR";
CM_ SG_ 707 VCRIGHT_windowThermalModeRR "Right body controller: window thermal mode RR; raw 0 = signal not available (SNA)";
CM_ SG_ 707 VCRIGHT_windowStopReasonRR "Reason for right rear window stopping motion";
CM_ SG_ 707 VCRIGHT_windowStopReqReasonRR "Reason for right rear window stopping motion";
CM_ SG_ 707 VCRIGHT_windowControlStateRF "Window control state";
CM_ SG_ 707 VCRIGHT_windowCtrlUnavailableRF "Window control unavailable reason";
CM_ SG_ 707 VCRIGHT_windowControlStateRR "Window control state";
CM_ SG_ 707 VCRIGHT_windowCtrlUnavailableRR "Window control unavailable reason";
CM_ SG_ 707 VCRIGHT_windowPositionStateRF "Reports the window position state";
CM_ SG_ 707 VCRIGHT_windowPositionStateRR "Window position state";
CM_ SG_ 707 VCRIGHT_windowVehGearStateRF "Window's interpretation of vehicle gear state; raw 0 = signal not available (SNA)";
CM_ SG_ 707 VCRIGHT_windowVehGearStateRR "Window's interpretation of vehicle gear state; raw 0 = signal not available (SNA)";
CM_ SG_ 707 VCRIGHT_windowSpeedTableStatusRF "Speed table build status of right front window; raw 0 = signal not available (SNA)";
CM_ SG_ 707 VCRIGHT_windowSpeedTableStatusRR "Speed table build status of right rear window; raw 0 = signal not available (SNA)";
BA_DEF_ BO_ "GenMsgCycleTime" INT 0 3600000;
BA_DEF_ BO_ "GenMsgSendType" ENUM "Cyclic","NotUsed","NotUsed","NotUsed","NotUsed","NotUsed","NotUsed","IfActive","NoMsgSendType","NotUsed";
BA_DEF_ BO_ "VFrameFormat" ENUM "StandardCAN","ExtendedCAN","reserved","J1939PG","reserved","reserved","reserved","reserved","reserved","reserved","reserved","reserved","reserved","reserved","StandardCAN_FD","ExtendedCAN_FD";
BA_DEF_ BO_ "CANFD_BRS" ENUM "0","1";
BA_DEF_ SG_ "GenSigSNA" STRING;
BA_DEF_ SG_ "SystemSignalLongSymbol" STRING;
BA_DEF_ SG_ "Confidence" ENUM "validated","plausible","layout-only","contradicted";
BA_DEF_DEF_ "GenMsgCycleTime" 0;
BA_DEF_DEF_ "GenMsgSendType" "NoMsgSendType";
BA_DEF_DEF_ "VFrameFormat" "StandardCAN";
BA_DEF_DEF_ "CANFD_BRS" "1";
BA_DEF_DEF_ "GenSigSNA" "";
BA_DEF_DEF_ "SystemSignalLongSymbol" "";
BA_DEF_DEF_ "Confidence" "layout-only";
BA_ "GenMsgCycleTime" BO_ 755 500;
BA_ "GenMsgSendType" BO_ 755 0;
BA_ "GenMsgCycleTime" BO_ 777 1000;
BA_ "GenMsgSendType" BO_ 777 0;
BA_ "GenMsgCycleTime" BO_ 1523 1000;
BA_ "GenMsgSendType" BO_ 1523 0;
BA_ "GenMsgCycleTime" BO_ 948 500;
BA_ "GenMsgSendType" BO_ 948 0;
BA_ "GenMsgCycleTime" BO_ 827 1000;
BA_ "GenMsgSendType" BO_ 827 0;
BA_ "GenMsgCycleTime" BO_ 661 5000;
BA_ "GenMsgSendType" BO_ 661 0;
BA_ "GenMsgCycleTime" BO_ 826 1000;
BA_ "GenMsgSendType" BO_ 826 0;
BA_ "GenMsgCycleTime" BO_ 723 1000;
BA_ "GenMsgSendType" BO_ 723 0;
BA_ "GenMsgCycleTime" BO_ 851 1000;
BA_ "GenMsgSendType" BO_ 851 0;
BA_ "GenMsgCycleTime" BO_ 663 500;
BA_ "GenMsgSendType" BO_ 663 0;
BA_ "GenMsgCycleTime" BO_ 627 500;
BA_ "GenMsgSendType" BO_ 627 0;
BA_ "GenMsgCycleTime" BO_ 1285 100;
BA_ "GenMsgSendType" BO_ 1285 0;
BA_ "GenMsgCycleTime" BO_ 1320 1000;
BA_ "GenMsgSendType" BO_ 1320 0;
BA_ "GenMsgCycleTime" BO_ 1847 1000;
BA_ "GenMsgSendType" BO_ 1847 0;
BA_ "GenMsgCycleTime" BO_ 700 8;
BA_ "GenMsgSendType" BO_ 700 0;
BA_ "GenMsgCycleTime" BO_ 577 100;
BA_ "GenMsgSendType" BO_ 577 0;
BA_ "GenMsgCycleTime" BO_ 1014 1000;
BA_ "GenMsgSendType" BO_ 1014 0;
BA_ "GenMsgCycleTime" BO_ 1013 100;
BA_ "GenMsgSendType" BO_ 1013 0;
BA_ "GenMsgCycleTime" BO_ 721 100;
BA_ "GenMsgSendType" BO_ 721 0;
BA_ "GenMsgCycleTime" BO_ 957 1000;
BA_ "GenMsgSendType" BO_ 957 0;
BA_ "GenMsgCycleTime" BO_ 801 1000;
BA_ "GenMsgSendType" BO_ 801 0;
BA_ "GenMsgCycleTime" BO_ 1349 33;
BA_ "GenMsgSendType" BO_ 1349 0;
BA_ "GenMsgCycleTime" BO_ 507 50;
BA_ "GenMsgSendType" BO_ 507 0;
BA_ "GenMsgCycleTime" BO_ 290 100;
BA_ "GenMsgSendType" BO_ 290 0;
BA_ "GenMsgCycleTime" BO_ 1186 1000;
BA_ "GenMsgSendType" BO_ 1186 0;
BA_ "GenMsgCycleTime" BO_ 642 100;
BA_ "GenMsgSendType" BO_ 642 0;
BA_ "GenMsgCycleTime" BO_ 1860 1000;
BA_ "GenMsgSendType" BO_ 1860 0;
BA_ "GenMsgCycleTime" BO_ 610 100;
BA_ "GenMsgSendType" BO_ 610 0;
BA_ "GenMsgCycleTime" BO_ 386 100;
BA_ "GenMsgSendType" BO_ 386 0;
BA_ "GenMsgCycleTime" BO_ 706 100;
BA_ "GenMsgSendType" BO_ 706 0;
BA_ "GenMsgCycleTime" BO_ 643 100;
BA_ "GenMsgSendType" BO_ 643 0;
BA_ "GenMsgCycleTime" BO_ 291 100;
BA_ "GenMsgSendType" BO_ 291 0;
BA_ "GenMsgCycleTime" BO_ 524 100;
BA_ "GenMsgSendType" BO_ 524 0;
BA_ "GenMsgCycleTime" BO_ 1675 100;
BA_ "GenMsgSendType" BO_ 1675 0;
BA_ "GenMsgCycleTime" BO_ 995 200;
BA_ "GenMsgSendType" BO_ 995 0;
BA_ "GenMsgCycleTime" BO_ 1859 1000;
BA_ "GenMsgSendType" BO_ 1859 0;
BA_ "GenMsgCycleTime" BO_ 899 100;
BA_ "GenMsgSendType" BO_ 899 0;
BA_ "GenMsgCycleTime" BO_ 1059 100;
BA_ "GenMsgSendType" BO_ 1059 0;
BA_ "GenMsgCycleTime" BO_ 707 100;
BA_ "GenMsgSendType" BO_ 707 0;
BA_ "Confidence" SG_ 755 UI_hvacReqTempSetpointLeft 0;
BA_ "Confidence" SG_ 755 UI_hvacReqAutoBlowerLevel 0;
BA_ "Confidence" SG_ 755 UI_hvacReqTempSetpointRight 0;
BA_ "Confidence" SG_ 755 UI_hvacReqAirDistributionMode 0;
BA_ "Confidence" SG_ 755 UI_hvacReqBlowerSegment 0;
BA_ "Confidence" SG_ 755 UI_hvacReqRecirc 0;
BA_ "Confidence" SG_ 755 UI_hvacReqACDisable 0;
BA_ "Confidence" SG_ 755 UI_hvacDefogState 0;
BA_ "Confidence" SG_ 755 UI_hvacReqUserPowerState 0;
BA_ "Confidence" SG_ 755 UI_hvacReqSecondRowState 0;
BA_ "Confidence" SG_ 755 UI_hvacUseModeledDuctTemp 1;
BA_ "Confidence" SG_ 755 UI_hvacReqKeepClimateOn 0;
BA_ "Confidence" SG_ 755 UI_hvacReqBioWeaponDefMode 0;
BA_ "Confidence" SG_ 755 UI_hvacLatchPassengerPresent 1;
BA_ "Confidence" SG_ 755 UI_enableHvacControlsFeatures1 1;
BA_ "Confidence" SG_ 755 UI_enableHvacNotifications 1;
BA_ "Confidence" SG_ 755 UI_hvacPhoneCallAirFlowAdjustEna 1;
BA_ "SystemSignalLongSymbol" SG_ 755 UI_hvacPhoneCallAirFlowAdjustEna "UI_hvacPhoneCallAirFlowAdjustEnabled";
BA_ "Confidence" SG_ 755 UI_enableHvacVOCPurgeRoutine 1;
BA_ "Confidence" SG_ 755 UI_enableCustomerTHSAlerts 1;
BA_ "Confidence" SG_ 755 UI_evapDryingSelectiveEnable 1;
BA_ "Confidence" SG_ 755 UI_enableHvacWeatherDataBasedHum 1;
BA_ "SystemSignalLongSymbol" SG_ 755 UI_enableHvacWeatherDataBasedHum "UI_enableHvacWeatherDataBasedHumidityControls";
BA_ "Confidence" SG_ 755 UI_hvacReqTempSetpointCOP 0;
BA_ "Confidence" SG_ 755 UI_hvacClimateNudgeStatus 1;
BA_ "Confidence" SG_ 755 UI_enableHvacControlsFeatures2 1;
BA_ "Confidence" SG_ 755 UI_enableHvacAPFoggingMonitor 1;
BA_ "Confidence" SG_ 755 UI_enableHvacLimpMode 1;
BA_ "Confidence" SG_ 777 UI_latitude 1;
BA_ "Confidence" SG_ 777 UI_longitude 1;
BA_ "Confidence" SG_ 777 UI_gpsAccuracy 1;
BA_ "GenSigSNA" SG_ 777 UI_gpsAccuracy "127";
BA_ "Confidence" SG_ 1523 UI_odometer 0;
BA_ "GenSigSNA" SG_ 1523 UI_odometer "16777215";
BA_ "Confidence" SG_ 948 UI_usbFrontHubPowerStateRequest 0;
BA_ "GenSigSNA" SG_ 948 UI_usbFrontHubPowerStateRequest "0";
BA_ "Confidence" SG_ 827 UI_idlePowerConsumption 0;
BA_ "Confidence" SG_ 827 UI_chargeTimeUntilTerminationPct 0;
BA_ "GenSigSNA" SG_ 827 UI_chargeTimeUntilTerminationPct "2047";
BA_ "Confidence" SG_ 827 UI_chargeTimeUntilReadyToDepart 0;
BA_ "GenSigSNA" SG_ 827 UI_chargeTimeUntilReadyToDepart "2047";
BA_ "Confidence" SG_ 661 UI_powerRationalityConfigIndex 1;
BA_ "Confidence" SG_ 661 UI_vcleftCfgRationalityThreshold 1;
BA_ "GenSigSNA" SG_ 661 UI_vcleftCfgRationalityThreshold "0";
BA_ "SystemSignalLongSymbol" SG_ 661 UI_vcleftCfgRationalityThreshold "UI_vcleftCfgRationalityThreshold0";
BA_ "Confidence" SG_ 661 UI_vcleftCfgRationalityTime0 1;
BA_ "GenSigSNA" SG_ 661 UI_vcleftCfgRationalityTime0 "0";
BA_ "Confidence" SG_ 661 UI_vcleftCfgRationalityThre_0001 1;
BA_ "GenSigSNA" SG_ 661 UI_vcleftCfgRationalityThre_0001 "0";
BA_ "SystemSignalLongSymbol" SG_ 661 UI_vcleftCfgRationalityThre_0001 "UI_vcleftCfgRationalityThreshold1";
BA_ "Confidence" SG_ 661 UI_vcleftCfgRationalityTime1 1;
BA_ "GenSigSNA" SG_ 661 UI_vcleftCfgRationalityTime1 "0";
BA_ "Confidence" SG_ 661 UI_vcleftCfgRationalityStaticA 1;
BA_ "GenSigSNA" SG_ 661 UI_vcleftCfgRationalityStaticA "65535";
BA_ "Confidence" SG_ 661 UI_vcleftCfgRationalityStaticB 1;
BA_ "GenSigSNA" SG_ 661 UI_vcleftCfgRationalityStaticB "32768";
BA_ "Confidence" SG_ 661 UI_vcleftCfgRationalityStaticC 1;
BA_ "GenSigSNA" SG_ 661 UI_vcleftCfgRationalityStaticC "32768";
BA_ "Confidence" SG_ 661 UI_vcleftCfgRationalityDynamicA 1;
BA_ "GenSigSNA" SG_ 661 UI_vcleftCfgRationalityDynamicA "65535";
BA_ "Confidence" SG_ 661 UI_vcleftCfgRationalityDynamicB 1;
BA_ "GenSigSNA" SG_ 661 UI_vcleftCfgRationalityDynamicB "32768";
BA_ "Confidence" SG_ 661 UI_vcleftCfgRationalityDynamicC 1;
BA_ "GenSigSNA" SG_ 661 UI_vcleftCfgRationalityDynamicC "32768";
BA_ "Confidence" SG_ 661 UI_vcrightCfgRationalityThreshol 1;
BA_ "GenSigSNA" SG_ 661 UI_vcrightCfgRationalityThreshol "0";
BA_ "SystemSignalLongSymbol" SG_ 661 UI_vcrightCfgRationalityThreshol "UI_vcrightCfgRationalityThreshold0";
BA_ "Confidence" SG_ 661 UI_vcrightCfgRationalityTime0 1;
BA_ "GenSigSNA" SG_ 661 UI_vcrightCfgRationalityTime0 "0";
BA_ "Confidence" SG_ 661 UI_vcrightCfgRationalityThr_0001 1;
BA_ "GenSigSNA" SG_ 661 UI_vcrightCfgRationalityThr_0001 "0";
BA_ "SystemSignalLongSymbol" SG_ 661 UI_vcrightCfgRationalityThr_0001 "UI_vcrightCfgRationalityThreshold1";
BA_ "Confidence" SG_ 661 UI_vcrightCfgRationalityTime1 1;
BA_ "GenSigSNA" SG_ 661 UI_vcrightCfgRationalityTime1 "0";
BA_ "Confidence" SG_ 661 UI_vcrightCfgRationalityStaticA 1;
BA_ "GenSigSNA" SG_ 661 UI_vcrightCfgRationalityStaticA "65535";
BA_ "Confidence" SG_ 661 UI_vcrightCfgRationalityStaticB 1;
BA_ "GenSigSNA" SG_ 661 UI_vcrightCfgRationalityStaticB "32768";
BA_ "Confidence" SG_ 661 UI_vcrightCfgRationalityStaticC 1;
BA_ "GenSigSNA" SG_ 661 UI_vcrightCfgRationalityStaticC "32768";
BA_ "Confidence" SG_ 661 UI_vcrightCfgRationalityDynamicA 1;
BA_ "GenSigSNA" SG_ 661 UI_vcrightCfgRationalityDynamicA "65535";
BA_ "Confidence" SG_ 661 UI_vcrightCfgRationalityDynamicB 1;
BA_ "GenSigSNA" SG_ 661 UI_vcrightCfgRationalityDynamicB "32768";
BA_ "Confidence" SG_ 661 UI_vcrightCfgRationalityDynamicC 1;
BA_ "GenSigSNA" SG_ 661 UI_vcrightCfgRationalityDynamicC "32768";
BA_ "Confidence" SG_ 661 UI_vcleftCfgCutoffThreshold0 1;
BA_ "GenSigSNA" SG_ 661 UI_vcleftCfgCutoffThreshold0 "0";
BA_ "Confidence" SG_ 661 UI_vcleftCfgCutoffTime0 1;
BA_ "GenSigSNA" SG_ 661 UI_vcleftCfgCutoffTime0 "0";
BA_ "Confidence" SG_ 661 UI_vcleftCfgCutoffThreshold1 1;
BA_ "GenSigSNA" SG_ 661 UI_vcleftCfgCutoffThreshold1 "0";
BA_ "Confidence" SG_ 661 UI_vcleftCfgCutoffTime1 1;
BA_ "GenSigSNA" SG_ 661 UI_vcleftCfgCutoffTime1 "0";
BA_ "Confidence" SG_ 661 UI_vcleftCfgCutoffStaticA 1;
BA_ "GenSigSNA" SG_ 661 UI_vcleftCfgCutoffStaticA "65535";
BA_ "Confidence" SG_ 661 UI_vcleftCfgCutoffStaticB 1;
BA_ "GenSigSNA" SG_ 661 UI_vcleftCfgCutoffStaticB "32768";
BA_ "Confidence" SG_ 661 UI_vcleftCfgCutoffStaticC 1;
BA_ "GenSigSNA" SG_ 661 UI_vcleftCfgCutoffStaticC "32768";
BA_ "Confidence" SG_ 661 UI_vcleftCfgCutoffDynamicA 1;
BA_ "GenSigSNA" SG_ 661 UI_vcleftCfgCutoffDynamicA "65535";
BA_ "Confidence" SG_ 661 UI_vcleftCfgCutoffDynamicB 1;
BA_ "GenSigSNA" SG_ 661 UI_vcleftCfgCutoffDynamicB "32768";
BA_ "Confidence" SG_ 661 UI_vcleftCfgCutoffDynamicC 1;
BA_ "GenSigSNA" SG_ 661 UI_vcleftCfgCutoffDynamicC "32768";
BA_ "Confidence" SG_ 661 UI_vcrightCfgCutoffThreshold0 1;
BA_ "GenSigSNA" SG_ 661 UI_vcrightCfgCutoffThreshold0 "0";
BA_ "Confidence" SG_ 661 UI_vcrightCfgCutoffTime0 1;
BA_ "GenSigSNA" SG_ 661 UI_vcrightCfgCutoffTime0 "0";
BA_ "Confidence" SG_ 661 UI_vcrightCfgCutoffThreshold1 1;
BA_ "GenSigSNA" SG_ 661 UI_vcrightCfgCutoffThreshold1 "0";
BA_ "Confidence" SG_ 661 UI_vcrightCfgCutoffTime1 1;
BA_ "GenSigSNA" SG_ 661 UI_vcrightCfgCutoffTime1 "0";
BA_ "Confidence" SG_ 661 UI_vcrightCfgCutoffStaticA 1;
BA_ "GenSigSNA" SG_ 661 UI_vcrightCfgCutoffStaticA "65535";
BA_ "Confidence" SG_ 661 UI_vcrightCfgCutoffStaticB 1;
BA_ "GenSigSNA" SG_ 661 UI_vcrightCfgCutoffStaticB "32768";
BA_ "Confidence" SG_ 661 UI_vcrightCfgCutoffStaticC 1;
BA_ "GenSigSNA" SG_ 661 UI_vcrightCfgCutoffStaticC "32768";
BA_ "Confidence" SG_ 661 UI_vcrightCfgCutoffDynamicA 1;
BA_ "GenSigSNA" SG_ 661 UI_vcrightCfgCutoffDynamicA "65535";
BA_ "Confidence" SG_ 661 UI_vcrightCfgCutoffDynamicB 1;
BA_ "GenSigSNA" SG_ 661 UI_vcrightCfgCutoffDynamicB "32768";
BA_ "Confidence" SG_ 661 UI_vcrightCfgCutoffDynamicC 1;
BA_ "GenSigSNA" SG_ 661 UI_vcrightCfgCutoffDynamicC "32768";
BA_ "Confidence" SG_ 826 UI_ratedRange 0;
BA_ "Confidence" SG_ 826 UI_whpm 1;
BA_ "Confidence" SG_ 826 UI_soe 0;
BA_ "Confidence" SG_ 826 UI_uSoe 0;
BA_ "Confidence" SG_ 826 UI_softPackLimitPct 1;
BA_ "Confidence" SG_ 826 UI_targetFullPackEnergy 1;
BA_ "Confidence" SG_ 723 UI_solarAzimuthAngle 1;
BA_ "GenSigSNA" SG_ 723 UI_solarAzimuthAngle "32768";
BA_ "Confidence" SG_ 723 UI_solarAzimuthAngleCarRef 1;
BA_ "GenSigSNA" SG_ 723 UI_solarAzimuthAngleCarRef "255";
BA_ "Confidence" SG_ 723 UI_isSunUp 0;
BA_ "GenSigSNA" SG_ 723 UI_isSunUp "3";
BA_ "Confidence" SG_ 723 UI_solarElevationAngle 0;
BA_ "GenSigSNA" SG_ 723 UI_solarElevationAngle "127";
BA_ "Confidence" SG_ 723 UI_screenPCBTemperature 0;
BA_ "Confidence" SG_ 723 UI_minsToSunset 0;
BA_ "Confidence" SG_ 723 UI_minsToSunrise 0;
BA_ "Confidence" SG_ 851 UI_touchActive 0;
BA_ "Confidence" SG_ 851 UI_audioActive 0;
BA_ "Confidence" SG_ 851 UI_bluetoothActive 1;
BA_ "Confidence" SG_ 851 UI_cellActive 0;
BA_ "Confidence" SG_ 851 UI_displayReady 0;
BA_ "Confidence" SG_ 851 UI_displayOn 0;
BA_ "Confidence" SG_ 851 UI_wifiActive 0;
BA_ "Confidence" SG_ 851 UI_wifiConnected 0;
BA_ "Confidence" SG_ 851 UI_systemActive 1;
BA_ "Confidence" SG_ 851 UI_readyForDrive 0;
BA_ "Confidence" SG_ 851 UI_cellConnected 0;
BA_ "Confidence" SG_ 851 UI_vpnActive 0;
BA_ "Confidence" SG_ 851 UI_autopilotTrial 1;
BA_ "Confidence" SG_ 851 UI_factoryReset 0;
BA_ "GenSigSNA" SG_ 851 UI_factoryReset "0";
BA_ "Confidence" SG_ 851 UI_gpsActive 0;
BA_ "Confidence" SG_ 851 UI_screenshotActive 1;
BA_ "Confidence" SG_ 851 UI_radioActive 1;
BA_ "Confidence" SG_ 851 UI_cellNetworkTechnology 0;
BA_ "GenSigSNA" SG_ 851 UI_cellNetworkTechnology "15";
BA_ "Confidence" SG_ 851 UI_cellReceiverPower 1;
BA_ "Confidence" SG_ 851 UI_falseTouchCounter 0;
BA_ "Confidence" SG_ 851 UI_developmentCar 1;
BA_ "Confidence" SG_ 851 UI_cameraActive 1;
BA_ "Confidence" SG_ 851 UI_cellSignalBars 0;
BA_ "GenSigSNA" SG_ 851 UI_cellSignalBars "7";
BA_ "Confidence" SG_ 851 UI_trailerModeTelltale 0;
BA_ "Confidence" SG_ 851 UI_pcbTemperature 0;
BA_ "Confidence" SG_ 851 UI_cpuTemperature 0;
BA_ "Confidence" SG_ 663 UI_adaptiveRideRequest 0;
BA_ "Confidence" SG_ 663 UI_suspensionLoweringRequest 1;
BA_ "GenSigSNA" SG_ 663 UI_suspensionLoweringRequest "3";
BA_ "Confidence" SG_ 663 UI_geofenceLevelingRequest 0;
BA_ "GenSigSNA" SG_ 663 UI_geofenceLevelingRequest "5";
BA_ "Confidence" SG_ 663 UI_jackModeToggleRequest 1;
BA_ "Confidence" SG_ 663 UI_adaptiveTuningRequest0 1;
BA_ "Confidence" SG_ 663 UI_adaptiveTuningRequest1 1;
BA_ "Confidence" SG_ 663 UI_roadRoughnessLookahead 1;
BA_ "GenSigSNA" SG_ 663 UI_roadRoughnessLookahead "127";
BA_ "Confidence" SG_ 663 UI_roadRoughnessStart 1;
BA_ "GenSigSNA" SG_ 663 UI_roadRoughnessStart "31";
BA_ "Confidence" SG_ 663 UI_mapVersionUsed 1;
BA_ "GenSigSNA" SG_ 663 UI_mapVersionUsed "255";
BA_ "Confidence" SG_ 663 UI_suspensionLevelRequest 1;
BA_ "Confidence" SG_ 627 UI_powerStateRequest 0;
BA_ "Confidence" SG_ 627 UI_childDoorLockOnRight 0;
BA_ "Confidence" SG_ 627 UI_frontFogSwitch 0;
BA_ "Confidence" SG_ 627 UI_summonActive 0;
BA_ "Confidence" SG_ 627 UI_frunkRequest 0;
BA_ "Confidence" SG_ 627 UI_wiperMode 0;
BA_ "GenSigSNA" SG_ 627 UI_wiperMode "0";
BA_ "Confidence" SG_ 627 UI_steeringBacklightEnabled 1;
BA_ "Confidence" SG_ 627 UI_steeringButtonMode 0;
BA_ "Confidence" SG_ 627 UI_walkUpUnlock 0;
BA_ "Confidence" SG_ 627 UI_walkAwayLock 0;
BA_ "Confidence" SG_ 627 UI_unlockOnPark 0;
BA_ "Confidence" SG_ 627 UI_globalUnlockOn 0;
BA_ "Confidence" SG_ 627 UI_childDoorLockOnLeft 0;
BA_ "Confidence" SG_ 627 UI_lockRequest 0;
BA_ "GenSigSNA" SG_ 627 UI_lockRequest "7";
BA_ "Confidence" SG_ 627 UI_alarmEnabled 0;
BA_ "Confidence" SG_ 627 UI_intrusionSensorOn 1;
BA_ "Confidence" SG_ 627 UI_stop12vSupport 0;
BA_ "Confidence" SG_ 627 UI_rearFogSwitch 0;
BA_ "Confidence" SG_ 627 UI_mirrorFoldRequest 0;
BA_ "GenSigSNA" SG_ 627 UI_mirrorFoldRequest "3";
BA_ "Confidence" SG_ 627 UI_mirrorHeatRequest 0;
BA_ "Confidence" SG_ 627 UI_remoteStartRequest 0;
BA_ "GenSigSNA" SG_ 627 UI_remoteStartRequest "4";
BA_ "Confidence" SG_ 627 UI_seeYouHomeLightingOn 0;
BA_ "Confidence" SG_ 627 UI_powerOff 0;
BA_ "Confidence" SG_ 627 UI_displayBrightnessLevel 0;
BA_ "GenSigSNA" SG_ 627 UI_displayBrightnessLevel "255";
BA_ "Confidence" SG_ 627 UI_ambientLightingEnabled 1;
BA_ "Confidence" SG_ 627 UI_autoHighBeamEnabled 0;
BA_ "Confidence" SG_ 627 UI_frontLeftSeatHeatReq 0;
BA_ "Confidence" SG_ 627 UI_frontRightSeatHeatReq 0;
BA_ "Confidence" SG_ 627 UI_rearLeftSeatHeatReq 0;
BA_ "Confidence" SG_ 627 UI_rearCenterSeatHeatReq 0;
BA_ "Confidence" SG_ 627 UI_rearRightSeatHeatReq 0;
BA_ "Confidence" SG_ 627 UI_autoFoldMirrorsOn 0;
BA_ "Confidence" SG_ 627 UI_mirrorDipOnReverse 0;
BA_ "Confidence" SG_ 627 UI_remoteClosureRequest 0;
BA_ "GenSigSNA" SG_ 627 UI_remoteClosureRequest "3";
BA_ "Confidence" SG_ 627 UI_wiperRequest 0;
BA_ "GenSigSNA" SG_ 627 UI_wiperRequest "0";
BA_ "Confidence" SG_ 627 UI_domeLightSwitch 0;
BA_ "Confidence" SG_ 627 UI_honkHorn 1;
BA_ "Confidence" SG_ 627 UI_driveStateRequest 1;
BA_ "Confidence" SG_ 627 UI_rearWindowLockout 1;
BA_ "Confidence" SG_ 1285 SA_infoIndex 1;
BA_ "Confidence" SG_ 1285 SA_genealogyVersion 0;
BA_ "Confidence" SG_ 1285 SA_genealogyCrc 0;
BA_ "Confidence" SG_ 1285 SA_region 0;
BA_ "Confidence" SG_ 1285 SA_OverTempThreshold 0;
BA_ "Confidence" SG_ 1285 SA_partNumInt 0;
BA_ "Confidence" SG_ 1285 SA_partNumRev 0;
BA_ "Confidence" SG_ 1285 SA_currentLimit 0;
BA_ "Confidence" SG_ 1285 SA_l1Voltage 0;
BA_ "Confidence" SG_ 1320 UnixTimeSeconds 0;
BA_ "Confidence" SG_ 1847 VCFRONT_LVBMS_InfoIndex 1;
BA_ "Confidence" SG_ 1847 VCFRONT_LVBMS_PcbaId 0;
BA_ "Confidence" SG_ 1847 VCFRONT_LVBMS_AssemblyId 0;
BA_ "Confidence" SG_ 1847 VCFRONT_LVBMS_SubUsageId 0;
BA_ "GenSigSNA" SG_ 1847 VCFRONT_LVBMS_SubUsageId "65535";
BA_ "Confidence" SG_ 1847 VCFRONT_LVBMS_UsageId 0;
BA_ "Confidence" SG_ 1847 VCFRONT_LVBMS_AppCRC 0;
BA_ "Confidence" SG_ 1847 VCFRONT_LVBMS_FWBuildType 0;
BA_ "Confidence" SG_ 700 VCFRONT_LVThermalMotorsIndex 1;
BA_ "Confidence" SG_ 700 VCFRONT_radiatorFanState 0;
BA_ "Confidence" SG_ 700 VCFRONT_radiatorFanTorque 0;
BA_ "GenSigSNA" SG_ 700 VCFRONT_radiatorFanTorque "1023";
BA_ "Confidence" SG_ 700 VCFRONT_radiatorFanIDc 0;
BA_ "GenSigSNA" SG_ 700 VCFRONT_radiatorFanIDc "127";
BA_ "Confidence" SG_ 700 VCFRONT_mlxLINCurrentSchedule 0;
BA_ "Confidence" SG_ 700 VCFRONT_pumpPowertrainState 0;
BA_ "Confidence" SG_ 700 VCFRONT_pumpPowertrainTorque 0;
BA_ "GenSigSNA" SG_ 700 VCFRONT_pumpPowertrainTorque "1023";
BA_ "Confidence" SG_ 700 VCFRONT_pumpPowertrainIDc 0;
BA_ "GenSigSNA" SG_ 700 VCFRONT_pumpPowertrainIDc "127";
BA_ "Confidence" SG_ 700 VCFRONT_pumpBatteryState 0;
BA_ "Confidence" SG_ 700 VCFRONT_pumpBatteryTorque 0;
BA_ "GenSigSNA" SG_ 700 VCFRONT_pumpBatteryTorque "1023";
BA_ "Confidence" SG_ 700 VCFRONT_pumpBatteryIDc 0;
BA_ "GenSigSNA" SG_ 700 VCFRONT_pumpBatteryIDc "127";
BA_ "Confidence" SG_ 577 VCFRONT_coolantFlowBatActual 0;
BA_ "Confidence" SG_ 577 VCFRONT_coolantFlowBatTarget 0;
BA_ "Confidence" SG_ 577 VCFRONT_coolantFlowBatReason 0;
BA_ "Confidence" SG_ 577 VCFRONT_coolantFlowPTActual 0;
BA_ "Confidence" SG_ 577 VCFRONT_coolantFlowPTTarget 0;
BA_ "Confidence" SG_ 577 VCFRONT_coolantFlowPTReason 0;
BA_ "Confidence" SG_ 577 VCFRONT_wasteHeatRequestType 0;
BA_ "Confidence" SG_ 577 VCFRONT_coolantHasBeenFilled 0;
BA_ "Confidence" SG_ 577 VCFRONT_radiatorIneffective 0;
BA_ "Confidence" SG_ 577 VCFRONT_coolantAirPurgeBatState 0;
BA_ "Confidence" SG_ 577 VCFRONT_coolantFlowTableConfig 0;
BA_ "Confidence" SG_ 577 VCFRONT_coolantLevelContinuously 0;
BA_ "SystemSignalLongSymbol" SG_ 577 VCFRONT_coolantLevelContinuously "VCFRONT_coolantLevelContinuouslyLow";
BA_ "Confidence" SG_ 1014 VCFRONT_lowBeamLeftStatus 0;
BA_ "GenSigSNA" SG_ 1014 VCFRONT_lowBeamLeftStatus "3";
BA_ "Confidence" SG_ 1014 VCFRONT_lowBeamRightStatus 0;
BA_ "GenSigSNA" SG_ 1014 VCFRONT_lowBeamRightStatus "3";
BA_ "Confidence" SG_ 1014 VCFRONT_highBeamLeftStatus 0;
BA_ "GenSigSNA" SG_ 1014 VCFRONT_highBeamLeftStatus "3";
BA_ "Confidence" SG_ 1014 VCFRONT_highBeamRightStatus 0;
BA_ "GenSigSNA" SG_ 1014 VCFRONT_highBeamRightStatus "3";
BA_ "Confidence" SG_ 1014 VCFRONT_DRLLeftStatus 0;
BA_ "GenSigSNA" SG_ 1014 VCFRONT_DRLLeftStatus "3";
BA_ "Confidence" SG_ 1014 VCFRONT_DRLRightStatus 0;
BA_ "GenSigSNA" SG_ 1014 VCFRONT_DRLRightStatus "3";
BA_ "Confidence" SG_ 1014 VCFRONT_fogLeftStatus 0;
BA_ "GenSigSNA" SG_ 1014 VCFRONT_fogLeftStatus "3";
BA_ "Confidence" SG_ 1014 VCFRONT_fogRightStatus 0;
BA_ "GenSigSNA" SG_ 1014 VCFRONT_fogRightStatus "3";
BA_ "Confidence" SG_ 1014 VCFRONT_sideMarkersStatus 0;
BA_ "GenSigSNA" SG_ 1014 VCFRONT_sideMarkersStatus "3";
BA_ "Confidence" SG_ 1014 VCFRONT_sideRepeaterLeftStatus 0;
BA_ "GenSigSNA" SG_ 1014 VCFRONT_sideRepeaterLeftStatus "3";
BA_ "Confidence" SG_ 1014 VCFRONT_sideRepeaterRightStatus 0;
BA_ "GenSigSNA" SG_ 1014 VCFRONT_sideRepeaterRightStatus "3";
BA_ "Confidence" SG_ 1014 VCFRONT_turnSignalLeftStatus 0;
BA_ "GenSigSNA" SG_ 1014 VCFRONT_turnSignalLeftStatus "3";
BA_ "Confidence" SG_ 1014 VCFRONT_turnSignalRightStatus 0;
BA_ "GenSigSNA" SG_ 1014 VCFRONT_turnSignalRightStatus "3";
BA_ "Confidence" SG_ 1014 VCFRONT_parkLeftStatus 0;
BA_ "GenSigSNA" SG_ 1014 VCFRONT_parkLeftStatus "3";
BA_ "Confidence" SG_ 1014 VCFRONT_parkRightStatus 0;
BA_ "GenSigSNA" SG_ 1014 VCFRONT_parkRightStatus "3";
BA_ "Confidence" SG_ 1014 VCFRONT_lowBeamLeftReadyForAimin 0;
BA_ "SystemSignalLongSymbol" SG_ 1014 VCFRONT_lowBeamLeftReadyForAimin "VCFRONT_lowBeamLeftReadyForAiming";
BA_ "Confidence" SG_ 1014 VCFRONT_lowBeamRightReadyForAimi 0;
BA_ "SystemSignalLongSymbol" SG_ 1014 VCFRONT_lowBeamRightReadyForAimi "VCFRONT_lowBeamRightReadyForAiming";
BA_ "Confidence" SG_ 1014 VCFRONT_lowBeamsOnForDRL 0;
BA_ "Confidence" SG_ 1014 VC_rightHeadlampHealth 0;
BA_ "Confidence" SG_ 1014 VC_leftHeadlampHealth 0;
BA_ "Confidence" SG_ 1014 VCFRONT_lightStatusMuxIndex 1;
BA_ "Confidence" SG_ 1014 VCFRONT_isAdaptiveHighBeamAvaila 0;
BA_ "SystemSignalLongSymbol" SG_ 1014 VCFRONT_isAdaptiveHighBeamAvaila "VCFRONT_isAdaptiveHighBeamAvailable";
BA_ "Confidence" SG_ 1014 VCFRONT_isAdaptiveHighBeamFaulte 0;
BA_ "SystemSignalLongSymbol" SG_ 1014 VCFRONT_isAdaptiveHighBeamFaulte "VCFRONT_isAdaptiveHighBeamFaulted";
BA_ "Confidence" SG_ 1014 VCFRONT_isBendLightingAvailable 0;
BA_ "Confidence" SG_ 1014 VCFRONT_advancedDrivingBeamStatu 0;
BA_ "SystemSignalLongSymbol" SG_ 1014 VCFRONT_advancedDrivingBeamStatu "VCFRONT_advancedDrivingBeamStatus";
BA_ "Confidence" SG_ 1014 VCFRONT_headlampBendAngle 0;
BA_ "Confidence" SG_ 1014 VCFRONT_headlampRoadClass 0;
BA_ "Confidence" SG_ 1013 VCFRONT_indicatorLeftRequest 0;
BA_ "Confidence" SG_ 1013 VCFRONT_indicatorRightRequest 0;
BA_ "Confidence" SG_ 1013 VCFRONT_hazardLightRequest 0;
BA_ "Confidence" SG_ 1013 VCFRONT_ambientLightingBrightnes 0;
BA_ "GenSigSNA" SG_ 1013 VCFRONT_ambientLightingBrightnes "255";
BA_ "Confidence" SG_ 1013 VCFRONT_switchLightingBrightness 0;
BA_ "GenSigSNA" SG_ 1013 VCFRONT_switchLightingBrightness "255";
BA_ "Confidence" SG_ 1013 VCFRONT_courtesyLightingRequest 0;
BA_ "Confidence" SG_ 1013 VCFRONT_hazardSwitchBacklight 0;
BA_ "Confidence" SG_ 1013 VCFRONT_highBeamControlState 0;
BA_ "Confidence" SG_ 1013 VCFRONT_dynamicBrakeLightState 0;
BA_ "Confidence" SG_ 1013 VCFRONT_lightingCoreState 0;
BA_ "GenSigSNA" SG_ 1013 VCFRONT_lightingCoreState "15";
BA_ "Confidence" SG_ 1013 VCFRONT_intHighBeamsFunctionStat 0;
BA_ "SystemSignalLongSymbol" SG_ 1013 VCFRONT_intHighBeamsFunctionStat "VCFRONT_intHighBeamsFunctionState";
BA_ "Confidence" SG_ 1013 VCFRONT_latchedHighBeamsFunction 0;
BA_ "SystemSignalLongSymbol" SG_ 1013 VCFRONT_latchedHighBeamsFunction "VCFRONT_latchedHighBeamsFunctionState";
BA_ "Confidence" SG_ 1013 VCFRONT_frontFogFunctionState 0;
BA_ "Confidence" SG_ 1013 VCFRONT_headlightsReadyOrTimedOu 0;
BA_ "SystemSignalLongSymbol" SG_ 1013 VCFRONT_headlightsReadyOrTimedOu "VCFRONT_headlightsReadyOrTimedOut";
BA_ "Confidence" SG_ 1013 VCFRONT_turnIndicatorStalk 0;
BA_ "GenSigSNA" SG_ 1013 VCFRONT_turnIndicatorStalk "3";
BA_ "Confidence" SG_ 1013 VCFRONT_highBeamLatchingState 0;
BA_ "GenSigSNA" SG_ 1013 VCFRONT_highBeamLatchingState "0";
BA_ "Confidence" SG_ 1013 VCFRONT_lightingCustomState 0;
BA_ "Confidence" SG_ 1013 VC_fastFlashHazardsActive 0;
BA_ "Confidence" SG_ 1013 VCFRONT_indicatorLeftInternal 0;
BA_ "Confidence" SG_ 1013 VCFRONT_indicatorRightInternal 0;
BA_ "Confidence" SG_ 721 VCFRONT_vcleftOkToUseHighPower 0;
BA_ "Confidence" SG_ 721 VCFRONT_vcrightOkToUseHighPower 0;
BA_ "Confidence" SG_ 721 VCFRONT_das1OkToUseHighPower 0;
BA_ "Confidence" SG_ 721 VCFRONT_das2OkToUseHighPower 0;
BA_ "Confidence" SG_ 721 VCFRONT_MCULogicOkToUseHighPower 0;
BA_ "Confidence" SG_ 721 VCFRONT_MCUAudioOkToUseHighPower 0;
BA_ "Confidence" SG_ 721 VCFRONT_cpOkToUseHighPower 0;
BA_ "Confidence" SG_ 721 VCFRONT_premAudioOkToUseHiPower 0;
BA_ "Confidence" SG_ 721 VCFRONT_tasOkToUseHighPower 0;
BA_ "Confidence" SG_ 957 VCFRONT_energyLossIndex 1;
BA_ "Confidence" SG_ 957 VCFRONT_userEnergyLossSinceDrive 0;
BA_ "Confidence" SG_ 957 VCFRONT_preconditioningEner_0001 0;
BA_ "SystemSignalLongSymbol" SG_ 957 VCFRONT_preconditioningEner_0001 "VCFRONT_preconditioningEnergyLossSinceDrive";
BA_ "Confidence" SG_ 957 VCFRONT_cabinOverheatEnergy_0001 0;
BA_ "SystemSignalLongSymbol" SG_ 957 VCFRONT_cabinOverheatEnergy_0001 "VCFRONT_cabinOverheatEnergyLossSinceDrive";
BA_ "Confidence" SG_ 957 VCFRONT_mobileAppEnergyLoss_0001 0;
BA_ "SystemSignalLongSymbol" SG_ 957 VCFRONT_mobileAppEnergyLoss_0001 "VCFRONT_mobileAppEnergyLossSinceDrive";
BA_ "Confidence" SG_ 957 VCFRONT_summonStandbyEnergy_0001 0;
BA_ "SystemSignalLongSymbol" SG_ 957 VCFRONT_summonStandbyEnergy_0001 "VCFRONT_summonStandbyEnergyLossSinceDrive";
BA_ "Confidence" SG_ 957 VCFRONT_sentryModeEnergyLos_0001 0;
BA_ "SystemSignalLongSymbol" SG_ 957 VCFRONT_sentryModeEnergyLos_0001 "VCFRONT_sentryModeEnergyLossSinceDrive";
BA_ "Confidence" SG_ 957 VCFRONT_backgroundEnergyLos_0001 0;
BA_ "SystemSignalLongSymbol" SG_ 957 VCFRONT_backgroundEnergyLos_0001 "VCFRONT_backgroundEnergyLossSinceDrive";
BA_ "Confidence" SG_ 957 VCFRONT_evapDryingEnergyLos_0001 0;
BA_ "SystemSignalLongSymbol" SG_ 957 VCFRONT_evapDryingEnergyLos_0001 "VCFRONT_evapDryingEnergyLossSinceDrive";
BA_ "Confidence" SG_ 957 VCFRONT_userEnergyLossSinceCharg 0;
BA_ "SystemSignalLongSymbol" SG_ 957 VCFRONT_userEnergyLossSinceCharg "VCFRONT_userEnergyLossSinceCharge";
BA_ "Confidence" SG_ 957 VCFRONT_preconditioningEnergyLos 0;
BA_ "SystemSignalLongSymbol" SG_ 957 VCFRONT_preconditioningEnergyLos "VCFRONT_preconditioningEnergyLossSinceCharge";
BA_ "Confidence" SG_ 957 VCFRONT_cabinOverheatEnergyLossS 0;
BA_ "SystemSignalLongSymbol" SG_ 957 VCFRONT_cabinOverheatEnergyLossS "VCFRONT_cabinOverheatEnergyLossSinceCharge";
BA_ "Confidence" SG_ 957 VCFRONT_mobileAppEnergyLossSince 0;
BA_ "SystemSignalLongSymbol" SG_ 957 VCFRONT_mobileAppEnergyLossSince "VCFRONT_mobileAppEnergyLossSinceCharge";
BA_ "Confidence" SG_ 957 VCFRONT_summonStandbyEnergyLossS 0;
BA_ "SystemSignalLongSymbol" SG_ 957 VCFRONT_summonStandbyEnergyLossS "VCFRONT_summonStandbyEnergyLossSinceCharge";
BA_ "Confidence" SG_ 957 VCFRONT_sentryModeEnergyLossSinc 0;
BA_ "SystemSignalLongSymbol" SG_ 957 VCFRONT_sentryModeEnergyLossSinc "VCFRONT_sentryModeEnergyLossSinceCharge";
BA_ "Confidence" SG_ 957 VCFRONT_backgroundEnergyLossSinc 0;
BA_ "SystemSignalLongSymbol" SG_ 957 VCFRONT_backgroundEnergyLossSinc "VCFRONT_backgroundEnergyLossSinceCharge";
BA_ "Confidence" SG_ 957 VCFRONT_evapDryingEnergyLossSinc 0;
BA_ "SystemSignalLongSymbol" SG_ 957 VCFRONT_evapDryingEnergyLossSinc "VCFRONT_evapDryingEnergyLossSinceCharge";
BA_ "Confidence" SG_ 801 VCFRONT_tempCoolantBatInlet 0;
BA_ "GenSigSNA" SG_ 801 VCFRONT_tempCoolantBatInlet "1023";
BA_ "Confidence" SG_ 801 VCFRONT_tempCoolantPTInlet 0;
BA_ "GenSigSNA" SG_ 801 VCFRONT_tempCoolantPTInlet "2047";
BA_ "Confidence" SG_ 801 VCFRONT_coolantLevel 0;
BA_ "Confidence" SG_ 801 VCFRONT_brakeFluidLevel 0;
BA_ "GenSigSNA" SG_ 801 VCFRONT_brakeFluidLevel "0";
BA_ "Confidence" SG_ 801 VCFRONT_tempAmbient 0;
BA_ "GenSigSNA" SG_ 801 VCFRONT_tempAmbient "0";
BA_ "Confidence" SG_ 801 VCFRONT_washerFluidLevel 0;
BA_ "GenSigSNA" SG_ 801 VCFRONT_washerFluidLevel "0";
BA_ "Confidence" SG_ 801 VCFRONT_tempAmbientFiltered 0;
BA_ "GenSigSNA" SG_ 801 VCFRONT_tempAmbientFiltered "0";
BA_ "Confidence" SG_ 801 VCFRONT_battSensorIrrational 0;
BA_ "Confidence" SG_ 801 VCFRONT_ptSensorIrrational 0;
BA_ "Confidence" SG_ 801 VCFRONT_sensorsCounter 0;
BA_ "Confidence" SG_ 801 VCFRONT_sensorsChecksum 0;
BA_ "Confidence" SG_ 1349 VCFRONT_systemStatusMuxIndex 1;
BA_ "Confidence" SG_ 1349 VCFRONT_systemStatusCounter 0;
BA_ "Confidence" SG_ 1349 VCFRONT_systemStatusChecksum 0;
BA_ "Confidence" SG_ 1349 VCFRONT_loadShedReason 0;
BA_ "Confidence" SG_ 1349 VCFRONT_VCRightEFuseLoadShedStag 0;
BA_ "SystemSignalLongSymbol" SG_ 1349 VCFRONT_VCRightEFuseLoadShedStag "VCFRONT_VCRightEFuseLoadShedStage";
BA_ "Confidence" SG_ 1349 VCFRONT_VCLeftEFuseLoadShedStage 0;
BA_ "Confidence" SG_ 1349 VCFRONT_DCDCSaturationLoadShedSt 0;
BA_ "SystemSignalLongSymbol" SG_ 1349 VCFRONT_DCDCSaturationLoadShedSt "VCFRONT_DCDCSaturationLoadShedStage";
BA_ "Confidence" SG_ 1349 VCFRONT_vehicleLoadShedStage 0;
BA_ "Confidence" SG_ 1349 VCFRONT_HVFaultVehicleLoadShedRe 0;
BA_ "SystemSignalLongSymbol" SG_ 1349 VCFRONT_HVFaultVehicleLoadShedRe "VCFRONT_HVFaultVehicleLoadShedRequest";
BA_ "Confidence" SG_ 1349 VCFRONT_postCrashVehicleLoadShed 0;
BA_ "SystemSignalLongSymbol" SG_ 1349 VCFRONT_postCrashVehicleLoadShed "VCFRONT_postCrashVehicleLoadShedActive";
BA_ "Confidence" SG_ 1349 VCFRONT_HVFaultVehicleLoadShedAc 0;
BA_ "SystemSignalLongSymbol" SG_ 1349 VCFRONT_HVFaultVehicleLoadShedAc "VCFRONT_HVFaultVehicleLoadShedActive";
BA_ "Confidence" SG_ 1349 VCFRONT_factoryVehicleLoadShedAc 0;
BA_ "SystemSignalLongSymbol" SG_ 1349 VCFRONT_factoryVehicleLoadShedAc "VCFRONT_factoryVehicleLoadShedActive";
BA_ "Confidence" SG_ 1349 VCFRONT_anyVehicleLoadShedActive 0;
BA_ "Confidence" SG_ 1349 VCFRONT_DIVehLoadShedActive 0;
BA_ "Confidence" SG_ 1349 VCFRONT_HVFaultLoadShedStateDBG 0;
BA_ "Confidence" SG_ 1349 VCFRONT_LVUnhealthyVehicleLoadSh 0;
BA_ "SystemSignalLongSymbol" SG_ 1349 VCFRONT_LVUnhealthyVehicleLoadSh "VCFRONT_LVUnhealthyVehicleLoadShedActive";
BA_ "Confidence" SG_ 1349 VCFRONT_loadShedStsCondenserFan 0;
BA_ "Confidence" SG_ 1349 VCFRONT_loadShedStsPTPump 0;
BA_ "Confidence" SG_ 1349 VCFRONT_loadShedMCUAudio 0;
BA_ "Confidence" SG_ 1349 VCFRONT_loadShedHVDownTriggerDBG 0;
BA_ "Confidence" SG_ 1349 VCFRONT_loadShedPCSSatTriggerDBG 0;
BA_ "Confidence" SG_ 1349 VCFRONT_loadShedStsBatteryPump 0;
BA_ "Confidence" SG_ 1349 VCFRONT_loadShedStsAPGlassHeater 0;
BA_ "Confidence" SG_ 1349 VCFRONT_loadShedStsMCUGraphics 0;
BA_ "Confidence" SG_ 1349 VCFRONT_IBSCurrentRMS_loadShed 0;
BA_ "Confidence" SG_ 1349 VCFRONT_loadShedAhLeakyBktCntDBG 0;
BA_ "Confidence" SG_ 1349 VCFRONT_loadShedPcs 0;
BA_ "Confidence" SG_ 1349 VCFRONT_loadShedGTWDownstrmRails 0;
BA_ "Confidence" SG_ 1349 VCFRONT_loadShedPCSMIATriggerDBG 0;
BA_ "Confidence" SG_ 1349 VCFRONT_loadShedTAS 0;
BA_ "Confidence" SG_ 1349 VCFRONT_loadShedBackStopBktCntDB 0;
BA_ "SystemSignalLongSymbol" SG_ 1349 VCFRONT_loadShedBackStopBktCntDB "VCFRONT_loadShedBackStopBktCntDBG";
BA_ "Confidence" SG_ 1349 VCFRONT_loadShedPCSLeakyBktCtDBG 0;
BA_ "Confidence" SG_ 1349 VCFRONT_loadShedUI 0;
BA_ "Confidence" SG_ 1349 VCFRONT_loadShedAutoPilot 0;
BA_ "Confidence" SG_ 507 VCLEFT_TLCStatusIndex 1;
BA_ "Confidence" SG_ 507 VCLEFT_TLCTemperature 0;
BA_ "GenSigSNA" SG_ 507 VCLEFT_TLCTemperature "128";
BA_ "Confidence" SG_ 507 VCLEFT_TLCLeftTurnVoltage 0;
BA_ "GenSigSNA" SG_ 507 VCLEFT_TLCLeftTurnVoltage "255";
BA_ "Confidence" SG_ 507 VCLEFT_TLCRightTurnVoltage 0;
BA_ "GenSigSNA" SG_ 507 VCLEFT_TLCRightTurnVoltage "255";
BA_ "Confidence" SG_ 507 VCLEFT_TLCState_LeftTurn 0;
BA_ "GenSigSNA" SG_ 507 VCLEFT_TLCState_LeftTurn "5";
BA_ "Confidence" SG_ 507 VCLEFT_TLCState_RightTurn 0;
BA_ "GenSigSNA" SG_ 507 VCLEFT_TLCState_RightTurn "5";
BA_ "Confidence" SG_ 507 VCLEFT_TLCState_Tail 0;
BA_ "GenSigSNA" SG_ 507 VCLEFT_TLCState_Tail "5";
BA_ "Confidence" SG_ 507 VCLEFT_TLCState_Stop 0;
BA_ "GenSigSNA" SG_ 507 VCLEFT_TLCState_Stop "5";
BA_ "Confidence" SG_ 507 VCLEFT_TLCState_Fog 0;
BA_ "GenSigSNA" SG_ 507 VCLEFT_TLCState_Fog "5";
BA_ "Confidence" SG_ 507 VCLEFT_TLCState_Reverse 0;
BA_ "GenSigSNA" SG_ 507 VCLEFT_TLCState_Reverse "5";
BA_ "Confidence" SG_ 290 VCLEFT_doorStatus2Index 1;
BA_ "Confidence" SG_ 290 VCLEFT_frontLatchRelDuty 0;
BA_ "Confidence" SG_ 290 VCLEFT_BPillarCameraHeaterState 0;
BA_ "GenSigSNA" SG_ 290 VCLEFT_BPillarCameraHeaterState "0";
BA_ "Confidence" SG_ 290 VCLEFT_doorLatchAjarSwitchVoltag 0;
BA_ "SystemSignalLongSymbol" SG_ 290 VCLEFT_doorLatchAjarSwitchVoltag "VCLEFT_doorLatchAjarSwitchVoltageF";
BA_ "Confidence" SG_ 290 VCLEFT_doorLatchAjarSwitchV_0001 0;
BA_ "SystemSignalLongSymbol" SG_ 290 VCLEFT_doorLatchAjarSwitchV_0001 "VCLEFT_doorLatchAjarSwitchVoltageR";
BA_ "Confidence" SG_ 290 VCLEFT_BPillarCameraHeaterCurren 0;
BA_ "GenSigSNA" SG_ 290 VCLEFT_BPillarCameraHeaterCurren "63";
BA_ "SystemSignalLongSymbol" SG_ 290 VCLEFT_BPillarCameraHeaterCurren "VCLEFT_BPillarCameraHeaterCurrent";
BA_ "Confidence" SG_ 290 VCLEFT_mirrorTiltXOffset 0;
BA_ "Confidence" SG_ 290 VCLEFT_mirrorTiltYOffset 0;
BA_ "Confidence" SG_ 1186 VCLEFT_etcBluetoothStatus 0;
BA_ "Confidence" SG_ 642 VCLEFT_hvacBlowerFeedbackIndex 1;
BA_ "Confidence" SG_ 642 VCLEFT_hvacBlowerEnabled 0;
BA_ "Confidence" SG_ 642 VCLEFT_hvacBlowerOutputDuty 0;
BA_ "GenSigSNA" SG_ 642 VCLEFT_hvacBlowerOutputDuty "127";
BA_ "Confidence" SG_ 642 VCLEFT_hvacBlowerRPMTarget 0;
BA_ "GenSigSNA" SG_ 642 VCLEFT_hvacBlowerRPMTarget "1023";
BA_ "Confidence" SG_ 642 VCLEFT_hvacBlowerRPMActual 0;
BA_ "Confidence" SG_ 642 VCLEFT_hvacBlowerTorque 0;
BA_ "GenSigSNA" SG_ 642 VCLEFT_hvacBlowerTorque "1023";
BA_ "Confidence" SG_ 642 VCLEFT_hvacBlowerFETTemp 0;
BA_ "GenSigSNA" SG_ 642 VCLEFT_hvacBlowerFETTemp "127";
BA_ "Confidence" SG_ 642 VCLEFT_hvacBlowerIDc 0;
BA_ "GenSigSNA" SG_ 642 VCLEFT_hvacBlowerIDc "127";
BA_ "Confidence" SG_ 642 VCLEFT_hvacBlowerInitd 0;
BA_ "Confidence" SG_ 642 VCLEFT_hvacBlowerFault 0;
BA_ "Confidence" SG_ 642 VCLEFT_hvacBlowerLimitFETTemps 0;
BA_ "Confidence" SG_ 642 VCLEFT_hvacBlowerPowerOn 0;
BA_ "Confidence" SG_ 642 VCLEFT_hvacBlowerMotorID 0;
BA_ "Confidence" SG_ 1860 VCLEFT_systemRecallStatus 0;
BA_ "GenSigSNA" SG_ 1860 VCLEFT_systemRecallStatus "0";
BA_ "Confidence" SG_ 1860 VCLEFT_seatRecallStatus 0;
BA_ "GenSigSNA" SG_ 1860 VCLEFT_seatRecallStatus "0";
BA_ "Confidence" SG_ 1860 VCLEFT_columnRecallStatus 0;
BA_ "GenSigSNA" SG_ 1860 VCLEFT_columnRecallStatus "0";
BA_ "Confidence" SG_ 1860 VCLEFT_mirrorRecallStatus 0;
BA_ "GenSigSNA" SG_ 1860 VCLEFT_mirrorRecallStatus "0";
BA_ "Confidence" SG_ 610 VCLEFT_steeringColumnSMState 0;
BA_ "GenSigSNA" SG_ 610 VCLEFT_steeringColumnSMState "0";
BA_ "Confidence" SG_ 610 VCLEFT_steeringColumnLastRequest 0;
BA_ "GenSigSNA" SG_ 610 VCLEFT_steeringColumnLastRequest "0";
BA_ "Confidence" SG_ 610 VCLEFT_steeringColumnUpDownDuty 0;
BA_ "Confidence" SG_ 610 VCLEFT_steeringColumnInOutDuty 0;
BA_ "Confidence" SG_ 610 VCLEFT_steeringColumnUpDownPos 0;
BA_ "Confidence" SG_ 610 VCLEFT_steeringColumnInOutPos 0;
BA_ "Confidence" SG_ 610 VCLEFT_steeringColumnUpDownAmps 0;
BA_ "Confidence" SG_ 610 VCLEFT_steeringColumnInOutAmps 0;
BA_ "Confidence" SG_ 610 VCLEFT_steeringColumnUpDownCalib 0;
BA_ "Confidence" SG_ 610 VCLEFT_steeringColumnInOutCalib 0;
BA_ "Confidence" SG_ 610 VCLEFT_steeringColumnUpDownTC 0;
BA_ "Confidence" SG_ 610 VCLEFT_steeringColumnInOutTC 0;
BA_ "Confidence" SG_ 386 VCLEFT_hvac2RLeftLateralStatus 0;
BA_ "Confidence" SG_ 386 VCLEFT_hvac2RLeftVerticalStatus 0;
BA_ "Confidence" SG_ 386 VCLEFT_hvac2RRightLateralStatus 0;
BA_ "Confidence" SG_ 386 VCLEFT_hvac2RRightVerticalStatus 0;
BA_ "Confidence" SG_ 386 VCLEFT_hvac2RLeftLateralPosition 0;
BA_ "Confidence" SG_ 386 VCLEFT_hvac2RLeftVerticalPositio 0;
BA_ "SystemSignalLongSymbol" SG_ 386 VCLEFT_hvac2RLeftVerticalPositio "VCLEFT_hvac2RLeftVerticalPosition";
BA_ "Confidence" SG_ 386 VCLEFT_hvac2RRightLateralPositio 0;
BA_ "SystemSignalLongSymbol" SG_ 386 VCLEFT_hvac2RRightLateralPositio "VCLEFT_hvac2RRightLateralPosition";
BA_ "Confidence" SG_ 386 VCLEFT_hvac2RRightVerticalPositi 0;
BA_ "SystemSignalLongSymbol" SG_ 386 VCLEFT_hvac2RRightVerticalPositi "VCLEFT_hvac2RRightVerticalPosition";
BA_ "Confidence" SG_ 706 VCLEFT_windowStatusIndex 1;
BA_ "Confidence" SG_ 706 VCLEFT_windowStateLF 0;
BA_ "Confidence" SG_ 706 VCLEFT_windowTrimClearMoveReques 0;
BA_ "SystemSignalLongSymbol" SG_ 706 VCLEFT_windowTrimClearMoveReques "VCLEFT_windowTrimClearMoveRequest";
BA_ "Confidence" SG_ 706 VCLEFT_windowDutyLF 0;
BA_ "Confidence" SG_ 706 VCLEFT_windowTrimClearActiveRequ 0;
BA_ "GenSigSNA" SG_ 706 VCLEFT_windowTrimClearActiveRequ "0";
BA_ "SystemSignalLongSymbol" SG_ 706 VCLEFT_windowTrimClearActiveRequ "VCLEFT_windowTrimClearActiveRequest";
BA_ "Confidence" SG_ 706 VCLEFT_windowCurrentLF 0;
BA_ "Confidence" SG_ 706 VCLEFT_windowPositionLF 0;
BA_ "GenSigSNA" SG_ 706 VCLEFT_windowPositionLF "1";
BA_ "Confidence" SG_ 706 VCLEFT_windowCalibratedLF 0;
BA_ "Confidence" SG_ 706 VCLEFT_windowStateLR 0;
BA_ "Confidence" SG_ 706 VCLEFT_windowDutyLR 0;
BA_ "Confidence" SG_ 706 VCLEFT_windowCurrentLR 0;
BA_ "Confidence" SG_ 706 VCLEFT_windowPositionLR 0;
BA_ "Confidence" SG_ 706 VCLEFT_windowCalibratedLR 0;
BA_ "Confidence" SG_ 706 VCLEFT_windowThermalTCLF 0;
BA_ "Confidence" SG_ 706 VCLEFT_windowThermalModeLF 0;
BA_ "GenSigSNA" SG_ 706 VCLEFT_windowThermalModeLF "0";
BA_ "Confidence" SG_ 706 VCLEFT_windowStopReasonLF 0;
BA_ "Confidence" SG_ 706 VCLEFT_windowStopReqReasonLF 0;
BA_ "Confidence" SG_ 706 VCLEFT_windowThermalTCLR 0;
BA_ "Confidence" SG_ 706 VCLEFT_windowThermalModeLR 0;
BA_ "GenSigSNA" SG_ 706 VCLEFT_windowThermalModeLR "0";
BA_ "Confidence" SG_ 706 VCLEFT_windowStopReasonLR 0;
BA_ "Confidence" SG_ 706 VCLEFT_windowStopReqReasonLR 0;
BA_ "Confidence" SG_ 706 VCLEFT_windowControlStateLF 0;
BA_ "Confidence" SG_ 706 VCLEFT_windowCtrlUnavailableLF 0;
BA_ "Confidence" SG_ 706 VCLEFT_windowControlStateLR 0;
BA_ "Confidence" SG_ 706 VCLEFT_windowCtrlUnavailableLR 0;
BA_ "Confidence" SG_ 706 VCLEFT_windowPositionStateLF 0;
BA_ "Confidence" SG_ 706 VCLEFT_windowPositionStateLR 0;
BA_ "Confidence" SG_ 706 VCLEFT_windowVehGearStateLF 0;
BA_ "GenSigSNA" SG_ 706 VCLEFT_windowVehGearStateLF "0";
BA_ "Confidence" SG_ 706 VCLEFT_windowVehGearStateLR 0;
BA_ "GenSigSNA" SG_ 706 VCLEFT_windowVehGearStateLR "0";
BA_ "Confidence" SG_ 706 VCLEFT_windowSpeedTableStatusLF 0;
BA_ "GenSigSNA" SG_ 706 VCLEFT_windowSpeedTableStatusLF "0";
BA_ "Confidence" SG_ 706 VCLEFT_windowSpeedTableStatusLR 0;
BA_ "GenSigSNA" SG_ 706 VCLEFT_windowSpeedTableStatusLR "0";
BA_ "Confidence" SG_ 643 VCRIGHT_PTCLeftTargetPowerHV 0;
BA_ "Confidence" SG_ 643 VCRIGHT_PTCRightTargetPowerHV 0;
BA_ "Confidence" SG_ 643 VCRIGHT_PTCLeftTargetDuty 0;
BA_ "Confidence" SG_ 643 VCRIGHT_PTCRightTargetDuty 0;
BA_ "Confidence" SG_ 643 VCRIGHT_PTCFlagAllowOperation 0;
BA_ "Confidence" SG_ 643 VCRIGHT_PTCRequestMode 0;
BA_ "Confidence" SG_ 643 VCRIGHT_PTCResistanceCheckEnable 0;
BA_ "Confidence" SG_ 643 VCRIGHT_PTCReset 0;
BA_ "Confidence" SG_ 643 VCRIGHT_PTCLeftDirectDriveIGBTO 0;
BA_ "Confidence" SG_ 643 VCRIGHT_PTCLeftDirectDriveIGBTC 0;
BA_ "Confidence" SG_ 643 VCRIGHT_PTCLeftDirectDriveIGBTI 0;
BA_ "Confidence" SG_ 643 VCRIGHT_PTCRightDirectDriveIGBTI 0;
BA_ "Confidence" SG_ 643 VCRIGHT_PTCRightDirectDriveIGBTC 0;
BA_ "Confidence" SG_ 643 VCRIGHT_PTCRightDirectDriveIGBTO 0;
BA_ "Confidence" SG_ 291 VCRIGHT_doorStatus2Index 1;
BA_ "Confidence" SG_ 291 VCRIGHT_frontLatchRelDuty 0;
BA_ "Confidence" SG_ 291 VCRIGHT_BPillarCameraHeaterState 0;
BA_ "GenSigSNA" SG_ 291 VCRIGHT_BPillarCameraHeaterState "0";
BA_ "Confidence" SG_ 291 VCRIGHT_doorLatchAjarSwitchVolta 0;
BA_ "SystemSignalLongSymbol" SG_ 291 VCRIGHT_doorLatchAjarSwitchVolta "VCRIGHT_doorLatchAjarSwitchVoltageF";
BA_ "Confidence" SG_ 291 VCRIGHT_doorLatchAjarSwitch_0001 0;
BA_ "SystemSignalLongSymbol" SG_ 291 VCRIGHT_doorLatchAjarSwitch_0001 "VCRIGHT_doorLatchAjarSwitchVoltageR";
BA_ "Confidence" SG_ 291 VCRIGHT_BPillarCameraHeaterCurre 0;
BA_ "GenSigSNA" SG_ 291 VCRIGHT_BPillarCameraHeaterCurre "63";
BA_ "SystemSignalLongSymbol" SG_ 291 VCRIGHT_BPillarCameraHeaterCurre "VCRIGHT_BPillarCameraHeaterCurrent";
BA_ "Confidence" SG_ 291 VCRIGHT_mirrorTiltXOffset 0;
BA_ "Confidence" SG_ 291 VCRIGHT_mirrorTiltYOffset 0;
BA_ "Confidence" SG_ 524 VCRIGHT_wattsDemandEvap 0;
BA_ "Confidence" SG_ 524 VCRIGHT_hvacEvapEnabled 0;
BA_ "Confidence" SG_ 524 VCRIGHT_conditioningRequest 0;
BA_ "Confidence" SG_ 524 VCRIGHT_tempEvaporator 0;
BA_ "GenSigSNA" SG_ 524 VCRIGHT_tempEvaporator "2047";
BA_ "Confidence" SG_ 524 VCRIGHT_tempEvaporatorTarget 0;
BA_ "GenSigSNA" SG_ 524 VCRIGHT_tempEvaporatorTarget "255";
BA_ "Confidence" SG_ 524 VCRIGHT_hvacBlowerSpeedRPMReq 0;
BA_ "Confidence" SG_ 524 VCRIGHT_hvacPerfTestRunning 0;
BA_ "Confidence" SG_ 524 VCRIGHT_evapPerformanceLow 0;
BA_ "Confidence" SG_ 524 VCRIGHT_tempAmbientRaw 0;
BA_ "GenSigSNA" SG_ 524 VCRIGHT_tempAmbientRaw "0";
BA_ "Confidence" SG_ 524 VCRIGHT_hvacHeatingEnabledLeft 0;
BA_ "Confidence" SG_ 524 VCRIGHT_hvacHeatingEnabledRight 0;
BA_ "Confidence" SG_ 524 VCRIGHT_hvacPerfTestState 0;
BA_ "Confidence" SG_ 524 VCRIGHT_hvacUnavailable 0;
BA_ "Confidence" SG_ 524 VCRIGHT_hvacBlowerRPMActualAP 0;
BA_ "Confidence" SG_ 524 VCRIGHT_hvacEvapEnabledInColdAmb 0;
BA_ "SystemSignalLongSymbol" SG_ 524 VCRIGHT_hvacEvapEnabledInColdAmb "VCRIGHT_hvacEvapEnabledInColdAmbient";
BA_ "Confidence" SG_ 1675 VCRIGHT_hvacSeat1RLCushionFanTrg 0;
BA_ "SystemSignalLongSymbol" SG_ 1675 VCRIGHT_hvacSeat1RLCushionFanTrg "VCRIGHT_hvacSeat1RLCushionFanTrgt";
BA_ "Confidence" SG_ 1675 VCRIGHT_hvacSeat1RLBackrestFanTr 0;
BA_ "SystemSignalLongSymbol" SG_ 1675 VCRIGHT_hvacSeat1RLBackrestFanTr "VCRIGHT_hvacSeat1RLBackrestFanTrgt";
BA_ "Confidence" SG_ 1675 VCRIGHT_hvacSeat1RRCushionFanTrg 0;
BA_ "SystemSignalLongSymbol" SG_ 1675 VCRIGHT_hvacSeat1RRCushionFanTrg "VCRIGHT_hvacSeat1RRCushionFanTrgt";
BA_ "Confidence" SG_ 1675 VCRIGHT_hvacSeat1RRBackrestFanTr 0;
BA_ "SystemSignalLongSymbol" SG_ 1675 VCRIGHT_hvacSeat1RRBackrestFanTr "VCRIGHT_hvacSeat1RRBackrestFanTrgt";
BA_ "Confidence" SG_ 1675 VCRIGHT_hvac2RActuatorsEnable 0;
BA_ "Confidence" SG_ 1675 VCRIGHT_hvac2RLeftLateralTarget 0;
BA_ "Confidence" SG_ 1675 VCRIGHT_hvac2RLeftVerticalTarget 0;
BA_ "Confidence" SG_ 1675 VCRIGHT_hvac2RRightLateralTarget 0;
BA_ "Confidence" SG_ 1675 VCRIGHT_hvac2RRightVerticalTarge 0;
BA_ "SystemSignalLongSymbol" SG_ 1675 VCRIGHT_hvac2RRightVerticalTarge "VCRIGHT_hvac2RRightVerticalTarget";
BA_ "Confidence" SG_ 995 VCRIGHT_brakeLightStatus 0;
BA_ "GenSigSNA" SG_ 995 VCRIGHT_brakeLightStatus "3";
BA_ "Confidence" SG_ 995 VCRIGHT_tailLightStatus 0;
BA_ "GenSigSNA" SG_ 995 VCRIGHT_tailLightStatus "3";
BA_ "Confidence" SG_ 995 VCRIGHT_turnSignalStatus 0;
BA_ "GenSigSNA" SG_ 995 VCRIGHT_turnSignalStatus "3";
BA_ "Confidence" SG_ 995 VCRIGHT_reverseLightStatus 0;
BA_ "GenSigSNA" SG_ 995 VCRIGHT_reverseLightStatus "3";
BA_ "Confidence" SG_ 995 VCRIGHT_rearFogLightStatus 0;
BA_ "GenSigSNA" SG_ 995 VCRIGHT_rearFogLightStatus "3";
BA_ "Confidence" SG_ 995 VCRIGHT_leftInteriorTrunkLightRe 0;
BA_ "SystemSignalLongSymbol" SG_ 995 VCRIGHT_leftInteriorTrunkLightRe "VCRIGHT_leftInteriorTrunkLightReq";
BA_ "Confidence" SG_ 995 VCRIGHT_audioCurrentSpikeDetecte 0;
BA_ "SystemSignalLongSymbol" SG_ 995 VCRIGHT_audioCurrentSpikeDetecte "VCRIGHT_audioCurrentSpikeDetected";
BA_ "Confidence" SG_ 995 VCRIGHT_fasciaReverseLightStatus 0;
BA_ "GenSigSNA" SG_ 995 VCRIGHT_fasciaReverseLightStatus "3";
BA_ "Confidence" SG_ 995 VCRIGHT_fasciaRearFogStatus 0;
BA_ "GenSigSNA" SG_ 995 VCRIGHT_fasciaRearFogStatus "3";
BA_ "Confidence" SG_ 995 VCRIGHT_fasciaTailLightStatus 0;
BA_ "GenSigSNA" SG_ 995 VCRIGHT_fasciaTailLightStatus "3";
BA_ "Confidence" SG_ 995 VCRIGHT_fasciaLeftTurnSignalStat 0;
BA_ "GenSigSNA" SG_ 995 VCRIGHT_fasciaLeftTurnSignalStat "3";
BA_ "SystemSignalLongSymbol" SG_ 995 VCRIGHT_fasciaLeftTurnSignalStat "VCRIGHT_fasciaLeftTurnSignalStatus";
BA_ "Confidence" SG_ 995 VCRIGHT_fasciaRightTurnSignalSta 0;
BA_ "GenSigSNA" SG_ 995 VCRIGHT_fasciaRightTurnSignalSta "3";
BA_ "SystemSignalLongSymbol" SG_ 995 VCRIGHT_fasciaRightTurnSignalSta "VCRIGHT_fasciaRightTurnSignalStatus";
BA_ "Confidence" SG_ 995 VCRIGHT_CHMSLLightStatus 0;
BA_ "GenSigSNA" SG_ 995 VCRIGHT_CHMSLLightStatus "3";
BA_ "Confidence" SG_ 1859 VCRIGHT_systemRecallStatus 0;
BA_ "GenSigSNA" SG_ 1859 VCRIGHT_systemRecallStatus "0";
BA_ "Confidence" SG_ 1859 VCRIGHT_seatRecallStatus 0;
BA_ "GenSigSNA" SG_ 1859 VCRIGHT_seatRecallStatus "0";
BA_ "Confidence" SG_ 1859 VCRIGHT_mirrorRecallStatus 0;
BA_ "GenSigSNA" SG_ 1859 VCRIGHT_mirrorRecallStatus "0";
BA_ "Confidence" SG_ 899 VCRIGHT_thsActive 0;
BA_ "Confidence" SG_ 899 VCRIGHT_thsTemperature 0;
BA_ "GenSigSNA" SG_ 899 VCRIGHT_thsTemperature "255";
BA_ "Confidence" SG_ 899 VCRIGHT_thsState 0;
BA_ "Confidence" SG_ 899 VCRIGHT_thsLINCurrentSchedule 0;
BA_ "Confidence" SG_ 899 VCRIGHT_thsDetected 0;
BA_ "Confidence" SG_ 899 VCRIGHT_thsHumidity 0;
BA_ "GenSigSNA" SG_ 899 VCRIGHT_thsHumidity "127";
BA_ "Confidence" SG_ 899 VCRIGHT_estimatedVehicleSituatio 0;
BA_ "SystemSignalLongSymbol" SG_ 899 VCRIGHT_estimatedVehicleSituatio "VCRIGHT_estimatedVehicleSituation";
BA_ "Confidence" SG_ 899 VCRIGHT_thsSolarLoadInfrared 0;
BA_ "GenSigSNA" SG_ 899 VCRIGHT_thsSolarLoadInfrared "1023";
BA_ "Confidence" SG_ 899 VCRIGHT_thsSolarLoadVisible 0;
BA_ "GenSigSNA" SG_ 899 VCRIGHT_thsSolarLoadVisible "1023";
BA_ "Confidence" SG_ 899 VCRIGHT_estimatedThsSolarLoad 0;
BA_ "GenSigSNA" SG_ 899 VCRIGHT_estimatedThsSolarLoad "1023";
BA_ "Confidence" SG_ 899 VCRIGHT_hvacFastLoggingEnabled 0;
BA_ "Confidence" SG_ 1059 VCRIGHT_nmGoingToSleep 0;
BA_ "Confidence" SG_ 1059 VCRIGHT_nmWakeUpBus 0;
BA_ "Confidence" SG_ 1059 VCRIGHT_nmKeepAwakeReason 0;
BA_ "GenSigSNA" SG_ 1059 VCRIGHT_nmKeepAwakeReason "0";
BA_ "Confidence" SG_ 1059 VCRIGHT_nmWakeUpReason 0;
BA_ "Confidence" SG_ 1059 VCRIGHT_nmDebugWakeUp 0;
BA_ "Confidence" SG_ 1059 VCRIGHT_nmEthKeepAwakeReason 0;
BA_ "GenSigSNA" SG_ 1059 VCRIGHT_nmEthKeepAwakeReason "0";
BA_ "Confidence" SG_ 1059 VCRIGHT_nmChKeepAwakeReason 0;
BA_ "GenSigSNA" SG_ 1059 VCRIGHT_nmChKeepAwakeReason "0";
BA_ "Confidence" SG_ 707 VCRIGHT_windowStatusIndex 1;
BA_ "Confidence" SG_ 707 VCRIGHT_windowStateRF 0;
BA_ "Confidence" SG_ 707 VCRIGHT_windowTrimClearMoveReque 0;
BA_ "SystemSignalLongSymbol" SG_ 707 VCRIGHT_windowTrimClearMoveReque "VCRIGHT_windowTrimClearMoveRequest";
BA_ "Confidence" SG_ 707 VCRIGHT_windowDutyRF 0;
BA_ "Confidence" SG_ 707 VCRIGHT_windowTrimClearActiveReq 0;
BA_ "GenSigSNA" SG_ 707 VCRIGHT_windowTrimClearActiveReq "0";
BA_ "SystemSignalLongSymbol" SG_ 707 VCRIGHT_windowTrimClearActiveReq "VCRIGHT_windowTrimClearActiveRequest";
BA_ "Confidence" SG_ 707 VCRIGHT_windowCurrentRF 0;
BA_ "Confidence" SG_ 707 VCRIGHT_windowPositionRF 0;
BA_ "GenSigSNA" SG_ 707 VCRIGHT_windowPositionRF "1";
BA_ "Confidence" SG_ 707 VCRIGHT_windowCalibratedRF 0;
BA_ "Confidence" SG_ 707 VCRIGHT_windowStateRR 0;
BA_ "Confidence" SG_ 707 VCRIGHT_windowDutyRR 0;
BA_ "Confidence" SG_ 707 VCRIGHT_windowCurrentRR 0;
BA_ "Confidence" SG_ 707 VCRIGHT_windowPositionRR 0;
BA_ "Confidence" SG_ 707 VCRIGHT_windowCalibratedRR 0;
BA_ "Confidence" SG_ 707 VCRIGHT_windowThermalTCRF 0;
BA_ "Confidence" SG_ 707 VCRIGHT_windowThermalModeRF 0;
BA_ "GenSigSNA" SG_ 707 VCRIGHT_windowThermalModeRF "0";
BA_ "Confidence" SG_ 707 VCRIGHT_windowStopReasonRF 0;
BA_ "Confidence" SG_ 707 VCRIGHT_windowStopReqReasonRF 0;
BA_ "Confidence" SG_ 707 VCRIGHT_windowThermalTCRR 0;
BA_ "Confidence" SG_ 707 VCRIGHT_windowThermalModeRR 0;
BA_ "GenSigSNA" SG_ 707 VCRIGHT_windowThermalModeRR "0";
BA_ "Confidence" SG_ 707 VCRIGHT_windowStopReasonRR 0;
BA_ "Confidence" SG_ 707 VCRIGHT_windowStopReqReasonRR 0;
BA_ "Confidence" SG_ 707 VCRIGHT_windowControlStateRF 0;
BA_ "Confidence" SG_ 707 VCRIGHT_windowCtrlUnavailableRF 0;
BA_ "Confidence" SG_ 707 VCRIGHT_windowControlStateRR 0;
BA_ "Confidence" SG_ 707 VCRIGHT_windowCtrlUnavailableRR 0;
BA_ "Confidence" SG_ 707 VCRIGHT_windowPositionStateRF 0;
BA_ "Confidence" SG_ 707 VCRIGHT_windowPositionStateRR 0;
BA_ "Confidence" SG_ 707 VCRIGHT_windowVehGearStateRF 0;
BA_ "GenSigSNA" SG_ 707 VCRIGHT_windowVehGearStateRF "0";
BA_ "Confidence" SG_ 707 VCRIGHT_windowVehGearStateRR 0;
BA_ "GenSigSNA" SG_ 707 VCRIGHT_windowVehGearStateRR "0";
BA_ "Confidence" SG_ 707 VCRIGHT_windowSpeedTableStatusRF 0;
BA_ "GenSigSNA" SG_ 707 VCRIGHT_windowSpeedTableStatusRF "0";
BA_ "Confidence" SG_ 707 VCRIGHT_windowSpeedTableStatusRR 0;
BA_ "GenSigSNA" SG_ 707 VCRIGHT_windowSpeedTableStatusRR "0";
VAL_ 755 UI_hvacReqTempSetpointLeft 26 "HI" 0 "LO" ;
VAL_ 755 UI_hvacReqAutoBlowerLevel 4 "VERY_HIGH" 3 "HIGH" 2 "MEDIUM" 1 "LOW" 0 "VERY_LOW" ;
VAL_ 755 UI_hvacReqTempSetpointRight 26 "HI" 0 "LO" ;
VAL_ 755 UI_hvacReqAirDistributionMode 7 "MANUAL_DEFROST_PANEL_FLOOR" 6 "MANUAL_DEFROST_PANEL" 5 "MANUAL_DEFROST_FLOOR" 4 "MANUAL_DEFROST" 3 "MANUAL_PANEL_FLOOR" 2 "MANUAL_PANEL" 1 "MANUAL_FLOOR" 0 "AUTO" ;
VAL_ 755 UI_hvacReqBlowerSegment 11 "AUTO" 10 "10" 9 "9" 8 "8" 7 "7" 6 "6" 5 "5" 4 "4" 3 "3" 2 "2" 1 "1" 0 "OFF" ;
VAL_ 755 UI_hvacReqRecirc 2 "FRESH" 1 "RECIRC" 0 "AUTO" ;
VAL_ 755 UI_hvacReqACDisable 2 "ON" 1 "OFF" 0 "AUTO" ;
VAL_ 755 UI_hvacDefogState 3 "AUTO_DEFOG" 2 "DEFROST" 1 "DEFOG" 0 "NONE" ;
VAL_ 755 UI_hvacReqUserPowerState 4 "OVERHEAT_PROTECT" 3 "OVERHEAT_PROTECT_FANONLY" 2 "PRECONDITION" 1 "ON" 0 "OFF" ;
VAL_ 755 UI_hvacReqSecondRowState 4 "HIGH" 3 "MED" 2 "LOW" 1 "OFF" 0 "AUTO" ;
VAL_ 755 UI_hvacReqKeepClimateOn 3 "KEEP_CLIMATE_ON_REQ_PARTY" 2 "KEEP_CLIMATE_ON_REQ_DOG" 1 "KEEP_CLIMATE_ON_REQ_ON" 0 "KEEP_CLIMATE_ON_REQ_OFF" ;
VAL_ 755 UI_hvacReqTempSetpointCOP 2 "HIGH" 1 "MEDIUM" 0 "LOW" ;
VAL_ 755 UI_hvacClimateNudgeStatus 4 "CLOSED_WITH_EXTERIOR_NUDGE" 3 "OPEN_WITH_NUDGE" 2 "OPEN_NO_NUDGE" 1 "CLOSED_WITH_NUDGE" 0 "CLOSED_NO_NUDGE" ;
VAL_ 777 UI_gpsAccuracy 127 "SNA" ;
VAL_ 1523 UI_odometer 16777215 "SNA" ;
VAL_ 948 UI_usbFrontHubPowerStateRequest 2 "POWER_ON" 1 "POWER_NO_PREFERENCE" 0 "POWER_REQUEST_SNA" ;
VAL_ 827 UI_chargeTimeUntilTerminationPct 2047 "SNA" 1440 "MAXVAL" ;
VAL_ 827 UI_chargeTimeUntilReadyToDepart 2047 "SNA" 1440 "MAXVAL" ;
VAL_ 661 UI_powerRationalityConfigIndex 255 "INVALID" 11 "VCRIGHT_DYNAMIC_CURVE_CUTOFF_CONFIG" 10 "VCRIGHT_STATIC_CURVE_CUTOFF_CONFIG" 9 "VCRIGHT_FAST_BLOW_CUTOFF_CONFIG" 8 "VCLEFT_DYNAMIC_CURVE_CUTOFF_CONFIG" 7 "VCLEFT_STATIC_CURVE_CUTOFF_CONFIG" 6 "VCLEFT_FAST_BLOW_CUTOFF_CONFIG" 5 "VCRIGHT_DYNAMIC_CURVE_CONFIG" 4 "VCRIGHT_STATIC_CURVE_CONFIG" 3 "VCRIGHT_FAST_BLOW_CONFIG" 2 "VCLEFT_DYNAMIC_CURVE_CONFIG" 1 "VCLEFT_STATIC_CURVE_CONFIG" 0 "VCLEFT_FAST_BLOW_CONFIG" ;
VAL_ 661 UI_vcleftCfgRationalityThreshold 15 "VC_THRESHOLD_CONFIG_15" 14 "VC_THRESHOLD_CONFIG_14" 13 "VC_THRESHOLD_CONFIG_13" 12 "VC_THRESHOLD_CONFIG_12" 11 "VC_THRESHOLD_CONFIG_11" 10 "VC_THRESHOLD_CONFIG_10" 9 "VC_THRESHOLD_CONFIG_9" 8 "VC_THRESHOLD_CONFIG_8" 7 "VC_THRESHOLD_CONFIG_7" 6 "VC_THRESHOLD_CONFIG_6" 5 "VC_THRESHOLD_CONFIG_5" 4 "VC_THRESHOLD_CONFIG_4" 3 "VC_THRESHOLD_CONFIG_3" 2 "VC_THRESHOLD_CONFIG_2" 1 "VC_THRESHOLD_CONFIG_1" 0 "SNA" ;
VAL_ 661 UI_vcleftCfgRationalityTime0 15 "VC_THRESHOLD_CONFIG_15" 14 "VC_THRESHOLD_CONFIG_14" 13 "VC_THRESHOLD_CONFIG_13" 12 "VC_THRESHOLD_CONFIG_12" 11 "VC_THRESHOLD_CONFIG_11" 10 "VC_THRESHOLD_CONFIG_10" 9 "VC_THRESHOLD_CONFIG_9" 8 "VC_THRESHOLD_CONFIG_8" 7 "VC_THRESHOLD_CONFIG_7" 6 "VC_THRESHOLD_CONFIG_6" 5 "VC_THRESHOLD_CONFIG_5" 4 "VC_THRESHOLD_CONFIG_4" 3 "VC_THRESHOLD_CONFIG_3" 2 "VC_THRESHOLD_CONFIG_2" 1 "VC_THRESHOLD_CONFIG_1" 0 "SNA" ;
VAL_ 661 UI_vcleftCfgRationalityThre_0001 15 "VC_THRESHOLD_CONFIG_15" 14 "VC_THRESHOLD_CONFIG_14" 13 "VC_THRESHOLD_CONFIG_13" 12 "VC_THRESHOLD_CONFIG_12" 11 "VC_THRESHOLD_CONFIG_11" 10 "VC_THRESHOLD_CONFIG_10" 9 "VC_THRESHOLD_CONFIG_9" 8 "VC_THRESHOLD_CONFIG_8" 7 "VC_THRESHOLD_CONFIG_7" 6 "VC_THRESHOLD_CONFIG_6" 5 "VC_THRESHOLD_CONFIG_5" 4 "VC_THRESHOLD_CONFIG_4" 3 "VC_THRESHOLD_CONFIG_3" 2 "VC_THRESHOLD_CONFIG_2" 1 "VC_THRESHOLD_CONFIG_1" 0 "SNA" ;
VAL_ 661 UI_vcleftCfgRationalityTime1 15 "VC_THRESHOLD_CONFIG_15" 14 "VC_THRESHOLD_CONFIG_14" 13 "VC_THRESHOLD_CONFIG_13" 12 "VC_THRESHOLD_CONFIG_12" 11 "VC_THRESHOLD_CONFIG_11" 10 "VC_THRESHOLD_CONFIG_10" 9 "VC_THRESHOLD_CONFIG_9" 8 "VC_THRESHOLD_CONFIG_8" 7 "VC_THRESHOLD_CONFIG_7" 6 "VC_THRESHOLD_CONFIG_6" 5 "VC_THRESHOLD_CONFIG_5" 4 "VC_THRESHOLD_CONFIG_4" 3 "VC_THRESHOLD_CONFIG_3" 2 "VC_THRESHOLD_CONFIG_2" 1 "VC_THRESHOLD_CONFIG_1" 0 "SNA" ;
VAL_ 661 UI_vcleftCfgRationalityStaticA 65535 "SNA" ;
VAL_ 661 UI_vcleftCfgRationalityStaticB -32768 "SNA" ;
VAL_ 661 UI_vcleftCfgRationalityStaticC -32768 "SNA" ;
VAL_ 661 UI_vcleftCfgRationalityDynamicA 65535 "SNA" ;
VAL_ 661 UI_vcleftCfgRationalityDynamicB -32768 "SNA" ;
VAL_ 661 UI_vcleftCfgRationalityDynamicC -32768 "SNA" ;
VAL_ 661 UI_vcrightCfgRationalityThreshol 15 "VC_THRESHOLD_CONFIG_15" 14 "VC_THRESHOLD_CONFIG_14" 13 "VC_THRESHOLD_CONFIG_13" 12 "VC_THRESHOLD_CONFIG_12" 11 "VC_THRESHOLD_CONFIG_11" 10 "VC_THRESHOLD_CONFIG_10" 9 "VC_THRESHOLD_CONFIG_9" 8 "VC_THRESHOLD_CONFIG_8" 7 "VC_THRESHOLD_CONFIG_7" 6 "VC_THRESHOLD_CONFIG_6" 5 "VC_THRESHOLD_CONFIG_5" 4 "VC_THRESHOLD_CONFIG_4" 3 "VC_THRESHOLD_CONFIG_3" 2 "VC_THRESHOLD_CONFIG_2" 1 "VC_THRESHOLD_CONFIG_1" 0 "SNA" ;
VAL_ 661 UI_vcrightCfgRationalityTime0 15 "VC_THRESHOLD_CONFIG_15" 14 "VC_THRESHOLD_CONFIG_14" 13 "VC_THRESHOLD_CONFIG_13" 12 "VC_THRESHOLD_CONFIG_12" 11 "VC_THRESHOLD_CONFIG_11" 10 "VC_THRESHOLD_CONFIG_10" 9 "VC_THRESHOLD_CONFIG_9" 8 "VC_THRESHOLD_CONFIG_8" 7 "VC_THRESHOLD_CONFIG_7" 6 "VC_THRESHOLD_CONFIG_6" 5 "VC_THRESHOLD_CONFIG_5" 4 "VC_THRESHOLD_CONFIG_4" 3 "VC_THRESHOLD_CONFIG_3" 2 "VC_THRESHOLD_CONFIG_2" 1 "VC_THRESHOLD_CONFIG_1" 0 "SNA" ;
VAL_ 661 UI_vcrightCfgRationalityThr_0001 15 "VC_THRESHOLD_CONFIG_15" 14 "VC_THRESHOLD_CONFIG_14" 13 "VC_THRESHOLD_CONFIG_13" 12 "VC_THRESHOLD_CONFIG_12" 11 "VC_THRESHOLD_CONFIG_11" 10 "VC_THRESHOLD_CONFIG_10" 9 "VC_THRESHOLD_CONFIG_9" 8 "VC_THRESHOLD_CONFIG_8" 7 "VC_THRESHOLD_CONFIG_7" 6 "VC_THRESHOLD_CONFIG_6" 5 "VC_THRESHOLD_CONFIG_5" 4 "VC_THRESHOLD_CONFIG_4" 3 "VC_THRESHOLD_CONFIG_3" 2 "VC_THRESHOLD_CONFIG_2" 1 "VC_THRESHOLD_CONFIG_1" 0 "SNA" ;
VAL_ 661 UI_vcrightCfgRationalityTime1 15 "VC_THRESHOLD_CONFIG_15" 14 "VC_THRESHOLD_CONFIG_14" 13 "VC_THRESHOLD_CONFIG_13" 12 "VC_THRESHOLD_CONFIG_12" 11 "VC_THRESHOLD_CONFIG_11" 10 "VC_THRESHOLD_CONFIG_10" 9 "VC_THRESHOLD_CONFIG_9" 8 "VC_THRESHOLD_CONFIG_8" 7 "VC_THRESHOLD_CONFIG_7" 6 "VC_THRESHOLD_CONFIG_6" 5 "VC_THRESHOLD_CONFIG_5" 4 "VC_THRESHOLD_CONFIG_4" 3 "VC_THRESHOLD_CONFIG_3" 2 "VC_THRESHOLD_CONFIG_2" 1 "VC_THRESHOLD_CONFIG_1" 0 "SNA" ;
VAL_ 661 UI_vcrightCfgRationalityStaticA 65535 "SNA" ;
VAL_ 661 UI_vcrightCfgRationalityStaticB -32768 "SNA" ;
VAL_ 661 UI_vcrightCfgRationalityStaticC -32768 "SNA" ;
VAL_ 661 UI_vcrightCfgRationalityDynamicA 65535 "SNA" ;
VAL_ 661 UI_vcrightCfgRationalityDynamicB -32768 "SNA" ;
VAL_ 661 UI_vcrightCfgRationalityDynamicC -32768 "SNA" ;
VAL_ 661 UI_vcleftCfgCutoffThreshold0 15 "VC_THRESHOLD_CONFIG_15" 14 "VC_THRESHOLD_CONFIG_14" 13 "VC_THRESHOLD_CONFIG_13" 12 "VC_THRESHOLD_CONFIG_12" 11 "VC_THRESHOLD_CONFIG_11" 10 "VC_THRESHOLD_CONFIG_10" 9 "VC_THRESHOLD_CONFIG_9" 8 "VC_THRESHOLD_CONFIG_8" 7 "VC_THRESHOLD_CONFIG_7" 6 "VC_THRESHOLD_CONFIG_6" 5 "VC_THRESHOLD_CONFIG_5" 4 "VC_THRESHOLD_CONFIG_4" 3 "VC_THRESHOLD_CONFIG_3" 2 "VC_THRESHOLD_CONFIG_2" 1 "VC_THRESHOLD_CONFIG_1" 0 "SNA" ;
VAL_ 661 UI_vcleftCfgCutoffTime0 15 "VC_THRESHOLD_CONFIG_15" 14 "VC_THRESHOLD_CONFIG_14" 13 "VC_THRESHOLD_CONFIG_13" 12 "VC_THRESHOLD_CONFIG_12" 11 "VC_THRESHOLD_CONFIG_11" 10 "VC_THRESHOLD_CONFIG_10" 9 "VC_THRESHOLD_CONFIG_9" 8 "VC_THRESHOLD_CONFIG_8" 7 "VC_THRESHOLD_CONFIG_7" 6 "VC_THRESHOLD_CONFIG_6" 5 "VC_THRESHOLD_CONFIG_5" 4 "VC_THRESHOLD_CONFIG_4" 3 "VC_THRESHOLD_CONFIG_3" 2 "VC_THRESHOLD_CONFIG_2" 1 "VC_THRESHOLD_CONFIG_1" 0 "SNA" ;
VAL_ 661 UI_vcleftCfgCutoffThreshold1 15 "VC_THRESHOLD_CONFIG_15" 14 "VC_THRESHOLD_CONFIG_14" 13 "VC_THRESHOLD_CONFIG_13" 12 "VC_THRESHOLD_CONFIG_12" 11 "VC_THRESHOLD_CONFIG_11" 10 "VC_THRESHOLD_CONFIG_10" 9 "VC_THRESHOLD_CONFIG_9" 8 "VC_THRESHOLD_CONFIG_8" 7 "VC_THRESHOLD_CONFIG_7" 6 "VC_THRESHOLD_CONFIG_6" 5 "VC_THRESHOLD_CONFIG_5" 4 "VC_THRESHOLD_CONFIG_4" 3 "VC_THRESHOLD_CONFIG_3" 2 "VC_THRESHOLD_CONFIG_2" 1 "VC_THRESHOLD_CONFIG_1" 0 "SNA" ;
VAL_ 661 UI_vcleftCfgCutoffTime1 15 "VC_THRESHOLD_CONFIG_15" 14 "VC_THRESHOLD_CONFIG_14" 13 "VC_THRESHOLD_CONFIG_13" 12 "VC_THRESHOLD_CONFIG_12" 11 "VC_THRESHOLD_CONFIG_11" 10 "VC_THRESHOLD_CONFIG_10" 9 "VC_THRESHOLD_CONFIG_9" 8 "VC_THRESHOLD_CONFIG_8" 7 "VC_THRESHOLD_CONFIG_7" 6 "VC_THRESHOLD_CONFIG_6" 5 "VC_THRESHOLD_CONFIG_5" 4 "VC_THRESHOLD_CONFIG_4" 3 "VC_THRESHOLD_CONFIG_3" 2 "VC_THRESHOLD_CONFIG_2" 1 "VC_THRESHOLD_CONFIG_1" 0 "SNA" ;
VAL_ 661 UI_vcleftCfgCutoffStaticA 65535 "SNA" ;
VAL_ 661 UI_vcleftCfgCutoffStaticB -32768 "SNA" ;
VAL_ 661 UI_vcleftCfgCutoffStaticC -32768 "SNA" ;
VAL_ 661 UI_vcleftCfgCutoffDynamicA 65535 "SNA" ;
VAL_ 661 UI_vcleftCfgCutoffDynamicB -32768 "SNA" ;
VAL_ 661 UI_vcleftCfgCutoffDynamicC -32768 "SNA" ;
VAL_ 661 UI_vcrightCfgCutoffThreshold0 15 "VC_THRESHOLD_CONFIG_15" 14 "VC_THRESHOLD_CONFIG_14" 13 "VC_THRESHOLD_CONFIG_13" 12 "VC_THRESHOLD_CONFIG_12" 11 "VC_THRESHOLD_CONFIG_11" 10 "VC_THRESHOLD_CONFIG_10" 9 "VC_THRESHOLD_CONFIG_9" 8 "VC_THRESHOLD_CONFIG_8" 7 "VC_THRESHOLD_CONFIG_7" 6 "VC_THRESHOLD_CONFIG_6" 5 "VC_THRESHOLD_CONFIG_5" 4 "VC_THRESHOLD_CONFIG_4" 3 "VC_THRESHOLD_CONFIG_3" 2 "VC_THRESHOLD_CONFIG_2" 1 "VC_THRESHOLD_CONFIG_1" 0 "SNA" ;
VAL_ 661 UI_vcrightCfgCutoffTime0 15 "VC_THRESHOLD_CONFIG_15" 14 "VC_THRESHOLD_CONFIG_14" 13 "VC_THRESHOLD_CONFIG_13" 12 "VC_THRESHOLD_CONFIG_12" 11 "VC_THRESHOLD_CONFIG_11" 10 "VC_THRESHOLD_CONFIG_10" 9 "VC_THRESHOLD_CONFIG_9" 8 "VC_THRESHOLD_CONFIG_8" 7 "VC_THRESHOLD_CONFIG_7" 6 "VC_THRESHOLD_CONFIG_6" 5 "VC_THRESHOLD_CONFIG_5" 4 "VC_THRESHOLD_CONFIG_4" 3 "VC_THRESHOLD_CONFIG_3" 2 "VC_THRESHOLD_CONFIG_2" 1 "VC_THRESHOLD_CONFIG_1" 0 "SNA" ;
VAL_ 661 UI_vcrightCfgCutoffThreshold1 15 "VC_THRESHOLD_CONFIG_15" 14 "VC_THRESHOLD_CONFIG_14" 13 "VC_THRESHOLD_CONFIG_13" 12 "VC_THRESHOLD_CONFIG_12" 11 "VC_THRESHOLD_CONFIG_11" 10 "VC_THRESHOLD_CONFIG_10" 9 "VC_THRESHOLD_CONFIG_9" 8 "VC_THRESHOLD_CONFIG_8" 7 "VC_THRESHOLD_CONFIG_7" 6 "VC_THRESHOLD_CONFIG_6" 5 "VC_THRESHOLD_CONFIG_5" 4 "VC_THRESHOLD_CONFIG_4" 3 "VC_THRESHOLD_CONFIG_3" 2 "VC_THRESHOLD_CONFIG_2" 1 "VC_THRESHOLD_CONFIG_1" 0 "SNA" ;
VAL_ 661 UI_vcrightCfgCutoffTime1 15 "VC_THRESHOLD_CONFIG_15" 14 "VC_THRESHOLD_CONFIG_14" 13 "VC_THRESHOLD_CONFIG_13" 12 "VC_THRESHOLD_CONFIG_12" 11 "VC_THRESHOLD_CONFIG_11" 10 "VC_THRESHOLD_CONFIG_10" 9 "VC_THRESHOLD_CONFIG_9" 8 "VC_THRESHOLD_CONFIG_8" 7 "VC_THRESHOLD_CONFIG_7" 6 "VC_THRESHOLD_CONFIG_6" 5 "VC_THRESHOLD_CONFIG_5" 4 "VC_THRESHOLD_CONFIG_4" 3 "VC_THRESHOLD_CONFIG_3" 2 "VC_THRESHOLD_CONFIG_2" 1 "VC_THRESHOLD_CONFIG_1" 0 "SNA" ;
VAL_ 661 UI_vcrightCfgCutoffStaticA 65535 "SNA" ;
VAL_ 661 UI_vcrightCfgCutoffStaticB -32768 "SNA" ;
VAL_ 661 UI_vcrightCfgCutoffStaticC -32768 "SNA" ;
VAL_ 661 UI_vcrightCfgCutoffDynamicA 65535 "SNA" ;
VAL_ 661 UI_vcrightCfgCutoffDynamicB -32768 "SNA" ;
VAL_ 661 UI_vcrightCfgCutoffDynamicC -32768 "SNA" ;
VAL_ 723 UI_solarAzimuthAngle -32768 "SNA" ;
VAL_ 723 UI_solarAzimuthAngleCarRef 255 "SNA" ;
VAL_ 723 UI_isSunUp 3 "SUN_SNA" 1 "SUN_UP" 0 "SUN_DOWN" ;
VAL_ 723 UI_solarElevationAngle 127 "SNA" ;
VAL_ 851 UI_autopilotTrial 3 "ACTIVE" 2 "STOP" 1 "START" 0 "NONE" ;
VAL_ 851 UI_factoryReset 3 "CUSTOMER" 2 "DIAGNOSTIC" 1 "DEVELOPER" 0 "NONE_SNA" ;
VAL_ 851 UI_cellNetworkTechnology 15 "CELL_NETWORK_SNA" 14 "CELL_NETWORK_NGRAN" 13 "CELL_NETWORK_5GSA" 12 "CELL_NETWORK_5GNSA" 11 "CELL_NETWORK_LTE5GCN" 10 "CELL_NETWORK_WCDMA" 9 "CELL_NETWORK_CDMA" 8 "CELL_NETWORK_GSM" 7 "CELL_NETWORK_LTE" 6 "CELL_NETWORK_HSPA" 5 "CELL_NETWORK_HSUPA" 4 "CELL_NETWORK_HSDPA" 3 "CELL_NETWORK_UMTS" 2 "CELL_NETWORK_EDGE" 1 "CELL_NETWORK_GPRS" 0 "CELL_NETWORK_NONE" ;
VAL_ 851 UI_cellSignalBars 7 "SNA" 5 "FIVE" 4 "FOUR" 3 "THREE" 2 "TWO" 1 "ONE" 0 "ZERO" ;
VAL_ 851 UI_trailerModeTelltale 3 "TRAILER_MODE_TELLTALE_RED" 2 "TRAILER_MODE_TELLTALE_YELLOW" 1 "TRAILER_MODE_TELLTALE_BLUE" 0 "TRAILER_MODE_TELLTALE_OFF" ;
VAL_ 663 UI_adaptiveRideRequest 3 "ADAPTIVE_RIDE_REQUEST_ADVANCED" 2 "ADAPTIVE_RIDE_REQUEST_SPORT" 1 "ADAPTIVE_RIDE_REQUEST_AUTO" 0 "ADAPTIVE_RIDE_REQUEST_COMFORT" ;
VAL_ 663 UI_suspensionLoweringRequest 3 "SNA" 2 "AUTO" 1 "ALWAYS" 0 "NEVER" ;
VAL_ 663 UI_geofenceLevelingRequest 5 "GEOFENCE_LEVELING_REQUEST_SNA" 4 "GEOFENCE_LEVELING_REQUEST_VERY_HIGH_PERSIST" 3 "GEOFENCE_LEVELING_REQUEST_HIGH_PERSIST" 2 "GEOFENCE_LEVELING_REQUEST_VERY_HIGH_TEMPORARY" 1 "GEOFENCE_LEVELING_REQUEST_HIGH_TEMPORARY" 0 "GEOFENCE_LEVELING_REQUEST_NONE" ;
VAL_ 663 UI_jackModeToggleRequest 1 "ACTIVE" 0 "NONE" ;
VAL_ 663 UI_roadRoughnessLookahead 127 "SNA" ;
VAL_ 663 UI_roadRoughnessStart 31 "SNA" ;
VAL_ 663 UI_mapVersionUsed 255 "SNA" ;
VAL_ 663 UI_suspensionLevelRequest 7 "VERY_HIGH_LEVEL_PERSIST" 6 "HIGH_LEVEL_PERSIST" 5 "VERY_HIGH_LEVEL_TEMPORARY" 4 "HIGH_LEVEL_TEMPORARY" 3 "STANDARD_LEVEL" 2 "LOW_LEVEL" 1 "VERY_LOW_LEVEL" 0 "NONE" ;
VAL_ 627 UI_powerStateRequest 3 "DRIVE_SUMMON" 2 "ACCESSORY_PLUS" 1 "ACCESSORY" 0 "IDLE" ;
VAL_ 627 UI_wiperMode 3 "WIPER_MODE_PARK" 2 "WIPER_MODE_NORMAL" 1 "WIPER_MODE_SERVICE" 0 "WIPER_MODE_SNA" ;
VAL_ 627 UI_steeringBacklightEnabled 1 "ENABLED" 0 "DISABLED" ;
VAL_ 627 UI_steeringButtonMode 7 "STEERING_BUTTON_MODE_SEATS" 6 "STEERING_BUTTON_MODE_WIPERS" 5 "STEERING_BUTTON_MODE_HEADLIGHT_RIGHT" 4 "STEERING_BUTTON_MODE_HEADLIGHT_LEFT" 3 "STEERING_BUTTON_MODE_MIRROR_RIGHT" 2 "STEERING_BUTTON_MODE_MIRROR_LEFT" 1 "STEERING_BUTTON_MODE_STEERING_COLUMN_ADJ" 0 "STEERING_BUTTON_MODE_OFF" ;
VAL_ 627 UI_lockRequest 7 "UI_LOCK_REQUEST_SNA" 4 "UI_LOCK_REQUEST_REMOTE_LOCK" 3 "UI_LOCK_REQUEST_REMOTE_UNLOCK" 2 "UI_LOCK_REQUEST_UNLOCK" 1 "UI_LOCK_REQUEST_LOCK" 0 "UI_LOCK_REQUEST_IDLE" ;
VAL_ 627 UI_mirrorFoldRequest 3 "MIRROR_FOLD_REQUEST_SNA" 2 "MIRROR_FOLD_REQUEST_PRESENT" 1 "MIRROR_FOLD_REQUEST_RETRACT" 0 "MIRROR_FOLD_REQUEST_IDLE" ;
VAL_ 627 UI_remoteStartRequest 4 "UI_REMOTE_START_REQUEST_SNA" 1 "UI_REMOTE_START_REQUEST_START" 0 "UI_REMOTE_START_REQUEST_IDLE" ;
VAL_ 627 UI_displayBrightnessLevel 255 "SNA" ;
VAL_ 627 UI_frontLeftSeatHeatReq 3 "HEATER_REQUEST_LEVEL3" 2 "HEATER_REQUEST_LEVEL2" 1 "HEATER_REQUEST_LEVEL1" 0 "HEATER_REQUEST_OFF" ;
VAL_ 627 UI_frontRightSeatHeatReq 3 "HEATER_REQUEST_LEVEL3" 2 "HEATER_REQUEST_LEVEL2" 1 "HEATER_REQUEST_LEVEL1" 0 "HEATER_REQUEST_OFF" ;
VAL_ 627 UI_rearLeftSeatHeatReq 3 "HEATER_REQUEST_LEVEL3" 2 "HEATER_REQUEST_LEVEL2" 1 "HEATER_REQUEST_LEVEL1" 0 "HEATER_REQUEST_OFF" ;
VAL_ 627 UI_rearCenterSeatHeatReq 3 "HEATER_REQUEST_LEVEL3" 2 "HEATER_REQUEST_LEVEL2" 1 "HEATER_REQUEST_LEVEL1" 0 "HEATER_REQUEST_OFF" ;
VAL_ 627 UI_rearRightSeatHeatReq 3 "HEATER_REQUEST_LEVEL3" 2 "HEATER_REQUEST_LEVEL2" 1 "HEATER_REQUEST_LEVEL1" 0 "HEATER_REQUEST_OFF" ;
VAL_ 627 UI_remoteClosureRequest 3 "UI_REMOTE_CLOSURE_REQUEST_SNA" 2 "UI_REMOTE_CLOSURE_REQUEST_FRONT_TRUNK_MOVE" 1 "UI_REMOTE_CLOSURE_REQUEST_REAR_TRUNK_MOVE" 0 "UI_REMOTE_CLOSURE_REQUEST_IDLE" ;
VAL_ 627 UI_wiperRequest 6 "WIPER_REQUEST_FAST_CONTINUOUS" 5 "WIPER_REQUEST_SLOW_CONTINUOUS" 4 "WIPER_REQUEST_FAST_INTERMITTENT" 3 "WIPER_REQUEST_SLOW_INTERMITTENT" 2 "WIPER_REQUEST_AUTO" 1 "WIPER_REQUEST_OFF" 0 "WIPER_REQUEST_SNA" ;
VAL_ 627 UI_domeLightSwitch 2 "DOME_LIGHT_SWITCH_AUTO" 1 "DOME_LIGHT_SWITCH_ON" 0 "DOME_LIGHT_SWITCH_OFF" ;
VAL_ 627 UI_driveStateRequest 1 "START" 0 "IDLE" ;
VAL_ 1285 SA_infoIndex 32 "Mux32" 31 "Mux31" 30 "Mux30" 29 "Mux29" 27 "Mux27" 26 "Mux26" 25 "Mux25" 11 "Mux11" 0 "Mux0" ;
VAL_ 1285 SA_region 6 "SA_REGION_INDIA" 5 "SA_REGION_SOUTH_KOREA" 4 "SA_REGION_AUSTRALIA" 3 "SA_REGION_JAPAN" 2 "SA_REGION_CHINA" 1 "SA_REGION_EU" 0 "SA_REGION_NA" ;
VAL_ 1847 VCFRONT_LVBMS_InfoIndex 5 "INVALID" 4 "SERIAL_NUMBER" 3 "BUILDTYPE" 2 "GITHASH" 1 "APP_USAGEID_CRC" 0 "PCBAID_ASSYID" ;
VAL_ 1847 VCFRONT_LVBMS_SubUsageId 65535 "SNA" ;
VAL_ 1847 VCFRONT_LVBMS_FWBuildType 4 "INFO_MFG_BUILD" 3 "INFO_TRACEABLE_CI_BUILD" 2 "INFO_LOCAL_BUILD" 1 "INFO_PLATFORM_BUILD" 0 "INFO_UNKNOWN_BUILD" ;
VAL_ 700 VCFRONT_LVThermalMotorsIndex 12 "END" 11 "COOLANT_FLOW_DIAGNOSTICS" 10 "WINDMILL_1" 9 "WINDMILL_0" 8 "PUMP_BATT_2" 7 "PUMP_BATT_1" 6 "PUMP_BATT_0" 5 "PUMP_PT_2" 4 "PUMP_PT_1" 3 "PUMP_PT_0" 2 "RAD_FAN_2" 1 "RAD_FAN_1" 0 "RAD_FAN_0" ;
VAL_ 700 VCFRONT_radiatorFanState 7 "VC_mlxControllerState_MIA" 6 "VC_mlxControllerState_FAULTED" 5 "VC_mlxControllerState_UV_TEST" 4 "VC_mlxControllerState_SELF_TEST" 3 "VC_mlxControllerState_STANDBY" 2 "VC_mlxControllerState_COLD_STARTUP" 1 "VC_mlxControllerState_ENABLE" 0 "VC_mlxControllerState_IDLE" ;
VAL_ 700 VCFRONT_radiatorFanTorque 1023 "SNA" ;
VAL_ 700 VCFRONT_radiatorFanIDc 127 "SNA" ;
VAL_ 700 VCFRONT_mlxLINCurrentSchedule 2 "DIAGNOSTIC" 1 "NORMAL" 0 "OFF" ;
VAL_ 700 VCFRONT_pumpPowertrainState 7 "VC_mlxControllerState_MIA" 6 "VC_mlxControllerState_FAULTED" 5 "VC_mlxControllerState_UV_TEST" 4 "VC_mlxControllerState_SELF_TEST" 3 "VC_mlxControllerState_STANDBY" 2 "VC_mlxControllerState_COLD_STARTUP" 1 "VC_mlxControllerState_ENABLE" 0 "VC_mlxControllerState_IDLE" ;
VAL_ 700 VCFRONT_pumpPowertrainTorque 1023 "SNA" ;
VAL_ 700 VCFRONT_pumpPowertrainIDc 127 "SNA" ;
VAL_ 700 VCFRONT_pumpBatteryState 7 "VC_mlxControllerState_MIA" 6 "VC_mlxControllerState_FAULTED" 5 "VC_mlxControllerState_UV_TEST" 4 "VC_mlxControllerState_SELF_TEST" 3 "VC_mlxControllerState_STANDBY" 2 "VC_mlxControllerState_COLD_STARTUP" 1 "VC_mlxControllerState_ENABLE" 0 "VC_mlxControllerState_IDLE" ;
VAL_ 700 VCFRONT_pumpBatteryTorque 1023 "SNA" ;
VAL_ 700 VCFRONT_pumpBatteryIDc 127 "SNA" ;
VAL_ 577 VCFRONT_coolantFlowBatReason 21 "AP_AIR_PURGE" 20 "DRIVERLESS_SELF_TEST" 19 "BATTERY_DISCHARGE_FLOW_REQ" 18 "DI_BURN_IN_FLOW_REQ" 17 "UI_FLOW_REQ" 16 "DI_PPR_FLOW_REQ" 15 "BMS_PPR_FLOW_REQ" 14 "HP_FLOW_REQ" 13 "DIS_FLOW_REQ" 12 "DI_FLOW_REQ" 11 "PCS_FLOW_REQ" 10 "PASSIVE_MANAGER_PT" 9 "ACTIVE_MANAGER_PT" 8 "OVERRIDE_PT" 7 "DAS_FLOW_REQ" 6 "BMS_FLOW_REQ" 5 "PASSIVE_MANAGER_BATT" 4 "ACTIVE_MANAGER_BATT" 3 "OVERRIDE_BATT" 2 "NO_FLOW_REQ" 1 "COOLANT_AIR_PURGE" 0 "NONE" ;
VAL_ 577 VCFRONT_coolantFlowPTReason 21 "AP_AIR_PURGE" 20 "DRIVERLESS_SELF_TEST" 19 "BATTERY_DISCHARGE_FLOW_REQ" 18 "DI_BURN_IN_FLOW_REQ" 17 "UI_FLOW_REQ" 16 "DI_PPR_FLOW_REQ" 15 "BMS_PPR_FLOW_REQ" 14 "HP_FLOW_REQ" 13 "DIS_FLOW_REQ" 12 "DI_FLOW_REQ" 11 "PCS_FLOW_REQ" 10 "PASSIVE_MANAGER_PT" 9 "ACTIVE_MANAGER_PT" 8 "OVERRIDE_PT" 7 "DAS_FLOW_REQ" 6 "BMS_FLOW_REQ" 5 "PASSIVE_MANAGER_BATT" 4 "ACTIVE_MANAGER_BATT" 3 "OVERRIDE_BATT" 2 "NO_FLOW_REQ" 1 "COOLANT_AIR_PURGE" 0 "NONE" ;
VAL_ 577 VCFRONT_wasteHeatRequestType 3 "WASTE_TYPE_BURN_IN" 2 "WASTE_TYPE_FULL" 1 "WASTE_TYPE_PARTIAL" 0 "WASTE_TYPE_NONE" ;
VAL_ 577 VCFRONT_coolantAirPurgeBatState 4 "AIR_PURGE_STATE_PENDING" 3 "AIR_PURGE_STATE_INTERRUPTED" 2 "AIR_PURGE_STATE_COMPLETE" 1 "AIR_PURGE_STATE_ACTIVE" 0 "AIR_PURGE_STATE_INACTIVE" ;
VAL_ 577 VCFRONT_coolantFlowTableConfig 1 "FLOW_TABLE_CONFIG_BMS_TYPE_5" 0 "FLOW_TABLE_CONFIG_DEFAULT" ;
VAL_ 1014 VCFRONT_lowBeamLeftStatus 3 "LIGHT_SNA" 2 "LIGHT_FAULT" 1 "LIGHT_ON" 0 "LIGHT_OFF" ;
VAL_ 1014 VCFRONT_lowBeamRightStatus 3 "LIGHT_SNA" 2 "LIGHT_FAULT" 1 "LIGHT_ON" 0 "LIGHT_OFF" ;
VAL_ 1014 VCFRONT_highBeamLeftStatus 3 "LIGHT_SNA" 2 "LIGHT_FAULT" 1 "LIGHT_ON" 0 "LIGHT_OFF" ;
VAL_ 1014 VCFRONT_highBeamRightStatus 3 "LIGHT_SNA" 2 "LIGHT_FAULT" 1 "LIGHT_ON" 0 "LIGHT_OFF" ;
VAL_ 1014 VCFRONT_DRLLeftStatus 3 "LIGHT_SNA" 2 "LIGHT_FAULT" 1 "LIGHT_ON" 0 "LIGHT_OFF" ;
VAL_ 1014 VCFRONT_DRLRightStatus 3 "LIGHT_SNA" 2 "LIGHT_FAULT" 1 "LIGHT_ON" 0 "LIGHT_OFF" ;
VAL_ 1014 VCFRONT_fogLeftStatus 3 "LIGHT_SNA" 2 "LIGHT_FAULT" 1 "LIGHT_ON" 0 "LIGHT_OFF" ;
VAL_ 1014 VCFRONT_fogRightStatus 3 "LIGHT_SNA" 2 "LIGHT_FAULT" 1 "LIGHT_ON" 0 "LIGHT_OFF" ;
VAL_ 1014 VCFRONT_sideMarkersStatus 3 "LIGHT_SNA" 2 "LIGHT_FAULT" 1 "LIGHT_ON" 0 "LIGHT_OFF" ;
VAL_ 1014 VCFRONT_sideRepeaterLeftStatus 3 "LIGHT_SNA" 2 "LIGHT_FAULT" 1 "LIGHT_ON" 0 "LIGHT_OFF" ;
VAL_ 1014 VCFRONT_sideRepeaterRightStatus 3 "LIGHT_SNA" 2 "LIGHT_FAULT" 1 "LIGHT_ON" 0 "LIGHT_OFF" ;
VAL_ 1014 VCFRONT_turnSignalLeftStatus 3 "LIGHT_SNA" 2 "LIGHT_FAULT" 1 "LIGHT_ON" 0 "LIGHT_OFF" ;
VAL_ 1014 VCFRONT_turnSignalRightStatus 3 "LIGHT_SNA" 2 "LIGHT_FAULT" 1 "LIGHT_ON" 0 "LIGHT_OFF" ;
VAL_ 1014 VCFRONT_parkLeftStatus 3 "LIGHT_SNA" 2 "LIGHT_FAULT" 1 "LIGHT_ON" 0 "LIGHT_OFF" ;
VAL_ 1014 VCFRONT_parkRightStatus 3 "LIGHT_SNA" 2 "LIGHT_FAULT" 1 "LIGHT_ON" 0 "LIGHT_OFF" ;
VAL_ 1014 VC_rightHeadlampHealth 7 "SMART_LIGHT_HEALTH_RESERVED" 6 "SMART_LIGHT_HEALTH_UPDATING" 5 "SMART_LIGHT_HEALTH_NOT_CONFIGURED" 4 "SMART_LIGHT_HEALTH_COMMS_OK_NO_LIGHT" 3 "SMART_LIGHT_HEALTH_OK" 2 "SMART_LIGHT_HEALTH_TIMEOUT" 1 "SMART_LIGHT_HEALTH_WAIT" 0 "SMART_LIGHT_HEALTH_OFF" ;
VAL_ 1014 VC_leftHeadlampHealth 7 "SMART_LIGHT_HEALTH_RESERVED" 6 "SMART_LIGHT_HEALTH_UPDATING" 5 "SMART_LIGHT_HEALTH_NOT_CONFIGURED" 4 "SMART_LIGHT_HEALTH_COMMS_OK_NO_LIGHT" 3 "SMART_LIGHT_HEALTH_OK" 2 "SMART_LIGHT_HEALTH_TIMEOUT" 1 "SMART_LIGHT_HEALTH_WAIT" 0 "SMART_LIGHT_HEALTH_OFF" ;
VAL_ 1014 VCFRONT_lightStatusMuxIndex 1 "ADVANCED_LIGHTING" 0 "HCM1_MIGRATION" ;
VAL_ 1014 VCFRONT_advancedDrivingBeamStatu 3 "ACTIVE_NO_COLUMNS_EXTINGUISHED" 2 "ACTIVE_SOME_COLUMNS_EXTINGUISHED" 1 "ENABLED_AND_INACTIVE" 0 "NOT_SUPPORTED_OR_DISABLED" ;
VAL_ 1014 VCFRONT_headlampRoadClass 3 "WET" 2 "MOTORWAY" 1 "TOWNLIGHT" 0 "NOMINAL" ;
VAL_ 1013 VCFRONT_indicatorLeftRequest 2 "TURN_SIGNAL_ACTIVE_HIGH" 1 "TURN_SIGNAL_ACTIVE_LOW" 0 "TURN_SIGNAL_OFF" ;
VAL_ 1013 VCFRONT_indicatorRightRequest 2 "TURN_SIGNAL_ACTIVE_HIGH" 1 "TURN_SIGNAL_ACTIVE_LOW" 0 "TURN_SIGNAL_OFF" ;
VAL_ 1013 VCFRONT_hazardLightRequest 8 "HAZARD_REQUEST_UDS" 7 "HAZARD_REQUEST_DAS" 6 "HAZARD_REQUEST_CAR_ALARM" 5 "HAZARD_REQUEST_CRASH" 4 "HAZARD_REQUEST_MISLOCK" 3 "HAZARD_REQUEST_UNLOCK" 2 "HAZARD_REQUEST_LOCK" 1 "HAZARD_REQUEST_BUTTON" 0 "HAZARD_REQUEST_NONE" ;
VAL_ 1013 VCFRONT_ambientLightingBrightnes 255 "SNA" ;
VAL_ 1013 VCFRONT_switchLightingBrightness 255 "SNA" ;
VAL_ 1013 VCFRONT_highBeamControlState 3 "HIGH_BEAM_CONTROL_DAS_AUTO" 2 "HIGH_BEAM_CONTROL_LATCHED" 1 "HIGH_BEAM_CONTROL_INTERMITTENT" 0 "HIGH_BEAM_CONTROL_IDLE" ;
VAL_ 1013 VCFRONT_dynamicBrakeLightState 2 "DYNAMIC_BRAKE_LIGHT_ACTIVE_HIGH" 1 "DYNAMIC_BRAKE_LIGHT_ACTIVE_LOW" 0 "DYNAMIC_BRAKE_LIGHT_OFF" ;
VAL_ 1013 VCFRONT_lightingCoreState 15 "LIGHT_CORE_STATE_SNA" 5 "LIGHT_CORE_STATE_CUSTOM" 4 "LIGHT_CORE_STATE_LOW_BEAMS" 3 "LIGHT_CORE_STATE_DRL_PLUS_REAR_POS_PARK" 2 "LIGHT_CORE_STATE_DRL" 1 "LIGHT_CORE_STATE_POS_PARK" 0 "LIGHT_CORE_STATE_OFF" ;
VAL_ 1013 VCFRONT_turnIndicatorStalk 3 "SIMULATED_LATCHING_STALK_SNA" 2 "SIMULATED_LATCHING_STALK_RIGHT" 1 "SIMULATED_LATCHING_STALK_LEFT" 0 "SIMULATED_LATCHING_STALK_IDLE" ;
VAL_ 1013 VCFRONT_highBeamLatchingState 3 "LATCHING_STATE_LATCHED" 2 "LATCHING_STATE_LATCHING" 1 "LATCHING_STATE_UNLATCHED" 0 "LATCHING_STATE_SNA" ;
VAL_ 1013 VCFRONT_lightingCustomState 31 "CUSTOM_LIGHTING_STATE_RESERVED" 14 "CUSTOM_LIGHTING_STATE_ROBOTAXI_WELCOME_RAMP_DOWN" 13 "CUSTOM_LIGHTING_STATE_ROBOTAXI_WELCOME_RAMP_UP" 12 "CUSTOM_LIGHTING_STATE_WELCOME_GOODBYE_SYHL" 11 "CUSTOM_LIGHTING_STATE_WELCOME_GOODBYE_NIGHT" 10 "CUSTOM_LIGHTING_STATE_WELCOME_GOODBYE_DAY" 9 "CUSTOM_LIGHTING_STATE_WELCOME_GOODBYE_UNLOCK" 8 "CUSTOM_LIGHTING_STATE_WELCOME_GOODBYE_LOCK" 7 "CUSTOM_LIGHTING_STATE_SELFTEST" 6 "CUSTOM_LIGHTING_STATE_HAZARD_WARNING_LIGHTS_OFF" 5 "CUSTOM_LIGHTING_STATE_HAZARD_WARNING_LIGHTS_ON" 4 "CUSTOM_LIGHTING_STATE_HAZARD_WARNING_WAIT_FOR_HEADLAMP_POWER" 3 "CUSTOM_LIGHTING_STATE_SENTRY_AWARE_OFF" 2 "CUSTOM_LIGHTING_STATE_SENTRY_AWARE_RAMP_DOWN" 1 "CUSTOM_LIGHTING_STATE_SENTRY_AWARE_RAMP_UP" 0 "CUSTOM_LIGHTING_STATE_NONE" ;
VAL_ 1013 VCFRONT_indicatorLeftInternal 2 "TURN_SIGNAL_ACTIVE_HIGH" 1 "TURN_SIGNAL_ACTIVE_LOW" 0 "TURN_SIGNAL_OFF" ;
VAL_ 1013 VCFRONT_indicatorRightInternal 2 "TURN_SIGNAL_ACTIVE_HIGH" 1 "TURN_SIGNAL_ACTIVE_LOW" 0 "TURN_SIGNAL_OFF" ;
VAL_ 957 VCFRONT_energyLossIndex 4 "SINCE_LAST_CHARGE2" 3 "SINCE_LAST_CHARGE" 2 "SINCE_LAST_DRIVE2" 1 "SINCE_LAST_DRIVE" 0 "STATUS" ;
VAL_ 801 VCFRONT_tempCoolantBatInlet 1023 "SNA" ;
VAL_ 801 VCFRONT_tempCoolantPTInlet 2047 "SNA" ;
VAL_ 801 VCFRONT_coolantLevel 1 "FILLED" 0 "NOT_OK" ;
VAL_ 801 VCFRONT_brakeFluidLevel 2 "NORMAL" 1 "LOW" 0 "SNA" ;
VAL_ 801 VCFRONT_tempAmbient 0 "SNA" ;
VAL_ 801 VCFRONT_washerFluidLevel 2 "NORMAL" 1 "LOW" 0 "SNA" ;
VAL_ 801 VCFRONT_tempAmbientFiltered 0 "SNA" ;
VAL_ 1349 VCFRONT_systemStatusMuxIndex 2 "LOAD_SHED_STATUSES_AND_COMMANDS" 1 "ACTIVE_LOAD_SHED_REASONS" 0 "SYSTEM_DATA" ;
VAL_ 1349 VCFRONT_loadShedReason 256 "VCFRONT_LOAD_SHED_REASON_LV_HEALTH" 128 "VCFRONT_LOAD_SHED_REASON_PRECHARGE" 64 "VCFRONT_LOAD_SHED_REASON_CUSTOM" 32 "VCFRONT_LOAD_SHED_REASON_FACTORY" 16 "VCFRONT_LOAD_SHED_REASON_HV_FAULT" 8 "VCFRONT_LOAD_SHED_REASON_POST_CRASH" 4 "VCFRONT_LOAD_SHED_REASON_VCRIGHT_EFUSE_PROTECTION" 2 "VCFRONT_LOAD_SHED_REASON_VCLEFT_EFUSE_PROTECTION" 1 "VCFRONT_LOAD_SHED_REASON_DCDC_SATURATION" 0 "VCFRONT_LOAD_SHED_REASON_NONE" ;
VAL_ 1349 VCFRONT_VCRightEFuseLoadShedStag 31 "MAX" 0 "IDLE" ;
VAL_ 1349 VCFRONT_VCLeftEFuseLoadShedStage 31 "MAX" 0 "IDLE" ;
VAL_ 1349 VCFRONT_DCDCSaturationLoadShedSt 31 "MAX" 0 "IDLE" ;
VAL_ 1349 VCFRONT_vehicleLoadShedStage 3 "VEHICLE_LOADSHEDDING_STAGE_3" 2 "VEHICLE_LOADSHEDDING_STAGE_2" 1 "VEHICLE_LOADSHEDDING_STAGE_1" 0 "VEHICLE_LOADSHEDDING_STAGE_IDLE_OR_UNDEFINED" ;
VAL_ 1349 VCFRONT_HVFaultLoadShedStateDBG 3 "HV_FAULT_LOADSHED_SM_STATE_ACTIVE" 2 "HV_FAULT_LOADSHED_SM_STATE_BLOCKED" 1 "HV_FAULT_LOADSHED_SM_STATE_IDLE" 0 "HV_FAULT_LOADSHED_SM_STATE_INIT" ;
VAL_ 507 VCLEFT_TLCStatusIndex 2 "INVALID" 1 "1" 0 "0" ;
VAL_ 507 VCLEFT_TLCTemperature -128 "SNA" ;
VAL_ 507 VCLEFT_TLCLeftTurnVoltage 255 "SNA" ;
VAL_ 507 VCLEFT_TLCRightTurnVoltage 255 "SNA" ;
VAL_ 507 VCLEFT_TLCState_LeftTurn 5 "VCLEFT_TLC_LIGHT_STATE_SNA" 4 "VCLEFT_TLC_LIGHT_STATE_FAULT" 3 "VCLEFT_TLC_LIGHT_STATE_ON_WITH_LOAD" 2 "VCLEFT_TLC_LIGHT_STATE_ON_WITHOUT_LOAD" 1 "VCLEFT_TLC_LIGHT_STATE_OFF_WITH_LOAD" 0 "VCLEFT_TLC_LIGHT_STATE_OFF_WITHOUT_LOAD" ;
VAL_ 507 VCLEFT_TLCState_RightTurn 5 "VCLEFT_TLC_LIGHT_STATE_SNA" 4 "VCLEFT_TLC_LIGHT_STATE_FAULT" 3 "VCLEFT_TLC_LIGHT_STATE_ON_WITH_LOAD" 2 "VCLEFT_TLC_LIGHT_STATE_ON_WITHOUT_LOAD" 1 "VCLEFT_TLC_LIGHT_STATE_OFF_WITH_LOAD" 0 "VCLEFT_TLC_LIGHT_STATE_OFF_WITHOUT_LOAD" ;
VAL_ 507 VCLEFT_TLCState_Tail 5 "VCLEFT_TLC_LIGHT_STATE_SNA" 4 "VCLEFT_TLC_LIGHT_STATE_FAULT" 3 "VCLEFT_TLC_LIGHT_STATE_ON_WITH_LOAD" 2 "VCLEFT_TLC_LIGHT_STATE_ON_WITHOUT_LOAD" 1 "VCLEFT_TLC_LIGHT_STATE_OFF_WITH_LOAD" 0 "VCLEFT_TLC_LIGHT_STATE_OFF_WITHOUT_LOAD" ;
VAL_ 507 VCLEFT_TLCState_Stop 5 "VCLEFT_TLC_LIGHT_STATE_SNA" 4 "VCLEFT_TLC_LIGHT_STATE_FAULT" 3 "VCLEFT_TLC_LIGHT_STATE_ON_WITH_LOAD" 2 "VCLEFT_TLC_LIGHT_STATE_ON_WITHOUT_LOAD" 1 "VCLEFT_TLC_LIGHT_STATE_OFF_WITH_LOAD" 0 "VCLEFT_TLC_LIGHT_STATE_OFF_WITHOUT_LOAD" ;
VAL_ 507 VCLEFT_TLCState_Fog 5 "VCLEFT_TLC_LIGHT_STATE_SNA" 4 "VCLEFT_TLC_LIGHT_STATE_FAULT" 3 "VCLEFT_TLC_LIGHT_STATE_ON_WITH_LOAD" 2 "VCLEFT_TLC_LIGHT_STATE_ON_WITHOUT_LOAD" 1 "VCLEFT_TLC_LIGHT_STATE_OFF_WITH_LOAD" 0 "VCLEFT_TLC_LIGHT_STATE_OFF_WITHOUT_LOAD" ;
VAL_ 507 VCLEFT_TLCState_Reverse 5 "VCLEFT_TLC_LIGHT_STATE_SNA" 4 "VCLEFT_TLC_LIGHT_STATE_FAULT" 3 "VCLEFT_TLC_LIGHT_STATE_ON_WITH_LOAD" 2 "VCLEFT_TLC_LIGHT_STATE_ON_WITHOUT_LOAD" 1 "VCLEFT_TLC_LIGHT_STATE_OFF_WITH_LOAD" 0 "VCLEFT_TLC_LIGHT_STATE_OFF_WITHOUT_LOAD" ;
VAL_ 290 VCLEFT_doorStatus2Index 1 "MUX1" 0 "MUX0" ;
VAL_ 290 VCLEFT_BPillarCameraHeaterState 4 "HEATER_STATE_FAULT" 3 "HEATER_STATE_OFF_UNAVAILABLE" 2 "HEATER_STATE_OFF" 1 "HEATER_STATE_ON" 0 "HEATER_STATE_SNA" ;
VAL_ 290 VCLEFT_BPillarCameraHeaterCurren 63 "SNA" ;
VAL_ 1186 VCLEFT_etcBluetoothStatus 3 "ETC_BLUETOOTH_STATE_RESERVED" 2 "ETC_BLUETOOTH_STATE_ON" 1 "ETC_BLUETOOTH_STATE_OFF" 0 "ETC_BLUETOOTH_STATE_INACTIVE" ;
VAL_ 642 VCLEFT_hvacBlowerFeedbackIndex 1 "END" 0 "HVAC_FEEDBACK_SIGNALS" ;
VAL_ 642 VCLEFT_hvacBlowerOutputDuty 127 "SNA" ;
VAL_ 642 VCLEFT_hvacBlowerRPMTarget 1023 "SNA" ;
VAL_ 642 VCLEFT_hvacBlowerTorque 1023 "SNA" ;
VAL_ 642 VCLEFT_hvacBlowerFETTemp 127 "SNA" ;
VAL_ 642 VCLEFT_hvacBlowerIDc 127 "SNA" ;
VAL_ 642 VCLEFT_hvacBlowerMotorID 2 "VC_MOTOR_ID_BOSCH" 1 "VC_MOTOR_ID_DELTA" 0 "VC_MOTOR_ID_UNKNOWN" ;
VAL_ 1860 VCLEFT_systemRecallStatus 3 "RECALL_INTERRUPTED" 2 "RECALL_COMPLETE" 1 "RECALL_IN_PROGRESS" 0 "RECALL_SNA" ;
VAL_ 1860 VCLEFT_seatRecallStatus 3 "RECALL_INTERRUPTED" 2 "RECALL_COMPLETE" 1 "RECALL_IN_PROGRESS" 0 "RECALL_SNA" ;
VAL_ 1860 VCLEFT_columnRecallStatus 3 "RECALL_INTERRUPTED" 2 "RECALL_COMPLETE" 1 "RECALL_IN_PROGRESS" 0 "RECALL_SNA" ;
VAL_ 1860 VCLEFT_mirrorRecallStatus 3 "RECALL_INTERRUPTED" 2 "RECALL_COMPLETE" 1 "RECALL_IN_PROGRESS" 0 "RECALL_SNA" ;
VAL_ 610 VCLEFT_steeringColumnSMState 3 "STEERING_COLUMN_STATE_MANUAL_CONTROL" 2 "STEERING_COLUMN_STATE_CALIBRATE" 1 "STEERING_COLUMN_STATE_RECALL" 0 "STEERING_COLUMN_STATE_SNA" ;
VAL_ 610 VCLEFT_steeringColumnLastRequest 5 "STEERING_COLUMN_REQUEST_OUT" 4 "STEERING_COLUMN_REQUEST_IN" 3 "STEERING_COLUMN_REQUEST_DOWN" 2 "STEERING_COLUMN_REQUEST_UP" 1 "STEERING_COLUMN_REQUEST_NONE" 0 "STEERING_COLUMN_REQUEST_SNA" ;
VAL_ 706 VCLEFT_windowStatusIndex 1 "Mux1" 0 "Mux0" ;
VAL_ 706 VCLEFT_windowStateLF 10 "WINDOW_STATE_SHORT_RISE_REVERSE" 9 "WINDOW_STATE_SHORT_RISE" 8 "WINDOW_STATE_BACKDRIVE" 7 "WINDOW_STATE_MOVING_AUTO_DOWN" 6 "WINDOW_STATE_MOVING_AUTO_UP" 5 "WINDOW_STATE_SHORT_DROP_REVERSE" 4 "WINDOW_STATE_SHORT_DROP" 3 "WINDOW_STATE_BACKOFF" 2 "WINDOW_STATE_MOVING_DOWN" 1 "WINDOW_STATE_MOVING_UP" 0 "WINDOW_STATE_STOPPED" ;
VAL_ 706 VCLEFT_windowTrimClearMoveReques 3 "WINDOW_TRIM_CLEAR_MOVE_REQUEST_BACKDRIVE" 2 "WINDOW_TRIM_CLEAR_MOVE_REQUEST_RESEAL" 1 "WINDOW_TRIM_CLEAR_MOVE_REQUEST_IDLE" 0 "WINDOW_TRIM_CLEAR_MOVE_REQUEST_SNA" ;
VAL_ 706 VCLEFT_windowTrimClearActiveRequ 2 "WINDOW_TRIM_CLEAR_ACTIVE_REQUEST_ACTIVE" 1 "WINDOW_TRIM_CLEAR_ACTIVE_REQUEST_INACTIVE" 0 "WINDOW_TRIM_CLEAR_ACTIVE_REQUEST_SNA" ;
VAL_ 706 VCLEFT_windowPositionLF 1 "SNA" ;
VAL_ 706 VCLEFT_windowStateLR 10 "WINDOW_STATE_SHORT_RISE_REVERSE" 9 "WINDOW_STATE_SHORT_RISE" 8 "WINDOW_STATE_BACKDRIVE" 7 "WINDOW_STATE_MOVING_AUTO_DOWN" 6 "WINDOW_STATE_MOVING_AUTO_UP" 5 "WINDOW_STATE_SHORT_DROP_REVERSE" 4 "WINDOW_STATE_SHORT_DROP" 3 "WINDOW_STATE_BACKOFF" 2 "WINDOW_STATE_MOVING_DOWN" 1 "WINDOW_STATE_MOVING_UP" 0 "WINDOW_STATE_STOPPED" ;
VAL_ 706 VCLEFT_windowThermalModeLF 3 "WINDOW_THERMAL_MODE_CRITICAL" 2 "WINDOW_THERMAL_MODE_ALERT" 1 "WINDOW_THERMAL_MODE_NORMAL" 0 "WINDOW_THERMAL_MODE_SNA" ;
VAL_ 706 VCLEFT_windowStopReasonLF 6 "WINDOW_STOP_REASON_STATE_TIMEOUT" 5 "WINDOW_STOP_REASON_FULL_OPEN_SOFT_STOP" 4 "WINDOW_STOP_REASON_STOP_REQUEST" 3 "WINDOW_STOP_REASON_TARGET_REACHED" 2 "WINDOW_STOP_REASON_NEW_REQUEST" 1 "WINDOW_STOP_REASON_DOOR_OPEN_TRIM_PROTECT" 0 "WINDOW_STOP_REASON_NONE" ;
VAL_ 706 VCLEFT_windowStopReqReasonLF 8 "WINDOW_STOP_REQUEST_REASON_EXTERNAL_REQUEST" 7 "WINDOW_STOP_REQUEST_REASON_FULL_OPEN_SOFT_STOP" 6 "WINDOW_STOP_REQUEST_REASON_STATE_TIMEOUT" 5 "WINDOW_STOP_REQUEST_REASON_STALL" 4 "WINDOW_STOP_REQUEST_REASON_THERMAL" 3 "WINDOW_STOP_REQUEST_REASON_REAR_LOCKOUT" 2 "WINDOW_STOP_REQUEST_REASON_SWITCH_RELEASED" 1 "WINDOW_STOP_REQUEST_REASON_SWITCH_CANCEL_AUTO_MOVEMENT" 0 "WINDOW_STOP_REQUEST_REASON_NONE" ;
VAL_ 706 VCLEFT_windowThermalModeLR 3 "WINDOW_THERMAL_MODE_CRITICAL" 2 "WINDOW_THERMAL_MODE_ALERT" 1 "WINDOW_THERMAL_MODE_NORMAL" 0 "WINDOW_THERMAL_MODE_SNA" ;
VAL_ 706 VCLEFT_windowStopReasonLR 6 "WINDOW_STOP_REASON_STATE_TIMEOUT" 5 "WINDOW_STOP_REASON_FULL_OPEN_SOFT_STOP" 4 "WINDOW_STOP_REASON_STOP_REQUEST" 3 "WINDOW_STOP_REASON_TARGET_REACHED" 2 "WINDOW_STOP_REASON_NEW_REQUEST" 1 "WINDOW_STOP_REASON_DOOR_OPEN_TRIM_PROTECT" 0 "WINDOW_STOP_REASON_NONE" ;
VAL_ 706 VCLEFT_windowStopReqReasonLR 8 "WINDOW_STOP_REQUEST_REASON_EXTERNAL_REQUEST" 7 "WINDOW_STOP_REQUEST_REASON_FULL_OPEN_SOFT_STOP" 6 "WINDOW_STOP_REQUEST_REASON_STATE_TIMEOUT" 5 "WINDOW_STOP_REQUEST_REASON_STALL" 4 "WINDOW_STOP_REQUEST_REASON_THERMAL" 3 "WINDOW_STOP_REQUEST_REASON_REAR_LOCKOUT" 2 "WINDOW_STOP_REQUEST_REASON_SWITCH_RELEASED" 1 "WINDOW_STOP_REQUEST_REASON_SWITCH_CANCEL_AUTO_MOVEMENT" 0 "WINDOW_STOP_REQUEST_REASON_NONE" ;
VAL_ 706 VCLEFT_windowControlStateLF 2 "WINDOW_CONTROL_STATE_GOING_TO_POSITION" 1 "WINDOW_CONTROL_STATE_CLOSING" 0 "WINDOW_CONTROL_STATE_IDLE" ;
VAL_ 706 VCLEFT_windowCtrlUnavailableLF 7 "WINDOW_CONTROL_UNAVAILABLE_REASON_WINDOW_MOVING" 6 "WINDOW_CONTROL_UNAVAILABLE_REASON_VEHICLE_IN_DRIVE" 5 "WINDOW_CONTROL_UNAVAILABLE_REASON_UNCALIBRATED" 4 "WINDOW_CONTROL_UNAVAILABLE_REASON_THERMAL_LIMIT" 3 "WINDOW_CONTROL_UNAVAILABLE_REASON_PINCH" 2 "WINDOW_CONTROL_UNAVAILABLE_REASON_SWITCH_PRESSED" 1 "WINDOW_CONTROL_UNAVAILABLE_REASON_UNEXPECTED" 0 "WINDOW_CONTROL_UNAVAILABLE_REASON_NONE" ;
VAL_ 706 VCLEFT_windowControlStateLR 2 "WINDOW_CONTROL_STATE_GOING_TO_POSITION" 1 "WINDOW_CONTROL_STATE_CLOSING" 0 "WINDOW_CONTROL_STATE_IDLE" ;
VAL_ 706 VCLEFT_windowCtrlUnavailableLR 7 "WINDOW_CONTROL_UNAVAILABLE_REASON_WINDOW_MOVING" 6 "WINDOW_CONTROL_UNAVAILABLE_REASON_VEHICLE_IN_DRIVE" 5 "WINDOW_CONTROL_UNAVAILABLE_REASON_UNCALIBRATED" 4 "WINDOW_CONTROL_UNAVAILABLE_REASON_THERMAL_LIMIT" 3 "WINDOW_CONTROL_UNAVAILABLE_REASON_PINCH" 2 "WINDOW_CONTROL_UNAVAILABLE_REASON_SWITCH_PRESSED" 1 "WINDOW_CONTROL_UNAVAILABLE_REASON_UNEXPECTED" 0 "WINDOW_CONTROL_UNAVAILABLE_REASON_NONE" ;
VAL_ 706 VCLEFT_windowPositionStateLF 7 "WINDOW_POSITION_CLOSED_TRIM_CLEAR" 6 "WINDOW_POSITION_FULL_OPEN" 5 "WINDOW_POSITION_PARTIAL_OPEN" 4 "WINDOW_POSITION_DAS_LIMITED" 3 "WINDOW_POSITION_VENT" 2 "WINDOW_POSITION_CRACKED" 1 "WINDOW_POSITION_CLOSED" 0 "WINDOW_POSITION_UNKNOWN" ;
VAL_ 706 VCLEFT_windowPositionStateLR 7 "WINDOW_POSITION_CLOSED_TRIM_CLEAR" 6 "WINDOW_POSITION_FULL_OPEN" 5 "WINDOW_POSITION_PARTIAL_OPEN" 4 "WINDOW_POSITION_DAS_LIMITED" 3 "WINDOW_POSITION_VENT" 2 "WINDOW_POSITION_CRACKED" 1 "WINDOW_POSITION_CLOSED" 0 "WINDOW_POSITION_UNKNOWN" ;
VAL_ 706 VCLEFT_windowVehGearStateLF 2 "WINDOW_VEHICLE_GEAR_STATE_IN_GEAR" 1 "WINDOW_VEHICLE_GEAR_STATE_PARK" 0 "WINDOW_VEHICLE_GEAR_STATE_UNKNOWN_SNA" ;
VAL_ 706 VCLEFT_windowVehGearStateLR 2 "WINDOW_VEHICLE_GEAR_STATE_IN_GEAR" 1 "WINDOW_VEHICLE_GEAR_STATE_PARK" 0 "WINDOW_VEHICLE_GEAR_STATE_UNKNOWN_SNA" ;
VAL_ 706 VCLEFT_windowSpeedTableStatusLF 2 "WINDOW_SPEED_TABLE_STATUS_FULLY_BUILT" 1 "WINDOW_SPEED_TABLE_STATUS_SENSITIVE_BUILT" 0 "WINDOW_SPEED_TABLE_STATUS_EMPTY_SNA" ;
VAL_ 706 VCLEFT_windowSpeedTableStatusLR 2 "WINDOW_SPEED_TABLE_STATUS_FULLY_BUILT" 1 "WINDOW_SPEED_TABLE_STATUS_SENSITIVE_BUILT" 0 "WINDOW_SPEED_TABLE_STATUS_EMPTY_SNA" ;
VAL_ 643 VCRIGHT_PTCRequestMode 4 "SEQ_ROD_CIO" 3 "SEQ_ROD_COI" 2 "DIRECT" 1 "DUTY" 0 "POWER" ;
VAL_ 291 VCRIGHT_doorStatus2Index 1 "MUX1" 0 "MUX0" ;
VAL_ 291 VCRIGHT_BPillarCameraHeaterState 4 "HEATER_STATE_FAULT" 3 "HEATER_STATE_OFF_UNAVAILABLE" 2 "HEATER_STATE_OFF" 1 "HEATER_STATE_ON" 0 "HEATER_STATE_SNA" ;
VAL_ 291 VCRIGHT_BPillarCameraHeaterCurre 63 "SNA" ;
VAL_ 524 VCRIGHT_tempEvaporator 2047 "SNA" ;
VAL_ 524 VCRIGHT_tempEvaporatorTarget 255 "SNA" ;
VAL_ 524 VCRIGHT_tempAmbientRaw 0 "SNA" ;
VAL_ 524 VCRIGHT_hvacPerfTestState 2 "BLOWING" 1 "WAITING" 0 "STOPPED" ;
VAL_ 995 VCRIGHT_brakeLightStatus 3 "LIGHT_SNA" 2 "LIGHT_FAULT" 1 "LIGHT_ON" 0 "LIGHT_OFF" ;
VAL_ 995 VCRIGHT_tailLightStatus 3 "LIGHT_SNA" 2 "LIGHT_FAULT" 1 "LIGHT_ON" 0 "LIGHT_OFF" ;
VAL_ 995 VCRIGHT_turnSignalStatus 3 "LIGHT_SNA" 2 "LIGHT_FAULT" 1 "LIGHT_ON" 0 "LIGHT_OFF" ;
VAL_ 995 VCRIGHT_reverseLightStatus 3 "LIGHT_SNA" 2 "LIGHT_FAULT" 1 "LIGHT_ON" 0 "LIGHT_OFF" ;
VAL_ 995 VCRIGHT_rearFogLightStatus 3 "LIGHT_SNA" 2 "LIGHT_FAULT" 1 "LIGHT_ON" 0 "LIGHT_OFF" ;
VAL_ 995 VCRIGHT_fasciaReverseLightStatus 3 "LIGHT_SNA" 2 "LIGHT_FAULT" 1 "LIGHT_ON" 0 "LIGHT_OFF" ;
VAL_ 995 VCRIGHT_fasciaRearFogStatus 3 "LIGHT_SNA" 2 "LIGHT_FAULT" 1 "LIGHT_ON" 0 "LIGHT_OFF" ;
VAL_ 995 VCRIGHT_fasciaTailLightStatus 3 "LIGHT_SNA" 2 "LIGHT_FAULT" 1 "LIGHT_ON" 0 "LIGHT_OFF" ;
VAL_ 995 VCRIGHT_fasciaLeftTurnSignalStat 3 "LIGHT_SNA" 2 "LIGHT_FAULT" 1 "LIGHT_ON" 0 "LIGHT_OFF" ;
VAL_ 995 VCRIGHT_fasciaRightTurnSignalSta 3 "LIGHT_SNA" 2 "LIGHT_FAULT" 1 "LIGHT_ON" 0 "LIGHT_OFF" ;
VAL_ 995 VCRIGHT_CHMSLLightStatus 3 "LIGHT_SNA" 2 "LIGHT_FAULT" 1 "LIGHT_ON" 0 "LIGHT_OFF" ;
VAL_ 1859 VCRIGHT_systemRecallStatus 3 "RECALL_INTERRUPTED" 2 "RECALL_COMPLETE" 1 "RECALL_IN_PROGRESS" 0 "RECALL_SNA" ;
VAL_ 1859 VCRIGHT_seatRecallStatus 3 "RECALL_INTERRUPTED" 2 "RECALL_COMPLETE" 1 "RECALL_IN_PROGRESS" 0 "RECALL_SNA" ;
VAL_ 1859 VCRIGHT_mirrorRecallStatus 3 "RECALL_INTERRUPTED" 2 "RECALL_COMPLETE" 1 "RECALL_IN_PROGRESS" 0 "RECALL_SNA" ;
VAL_ 899 VCRIGHT_thsTemperature 255 "SNA" ;
VAL_ 899 VCRIGHT_thsState 4 "IDLE" 3 "WAIT_CRC_RESPONSE" 2 "WAIT_CRC_REQUEST" 1 "CONFIG" 0 "INIT" ;
VAL_ 899 VCRIGHT_thsLINCurrentSchedule 7 "OTHER" 3 "DIAGNOSTIC" 2 "CONFIG" 1 "MAIN" 0 "OFF" ;
VAL_ 899 VCRIGHT_thsHumidity 127 "SNA" ;
VAL_ 899 VCRIGHT_estimatedVehicleSituatio 2 "VEHICLE_SITUATION_OUTDOOR" 1 "VEHICLE_SITUATION_INDOOR" 0 "VEHICLE_SITUATION_UNKNOWN" ;
VAL_ 899 VCRIGHT_thsSolarLoadInfrared 1023 "SNA" ;
VAL_ 899 VCRIGHT_thsSolarLoadVisible 1023 "SNA" ;
VAL_ 899 VCRIGHT_estimatedThsSolarLoad 1023 "SNA" ;
VAL_ 1059 VCRIGHT_nmKeepAwakeReason 31 "VCRIGHT_KEEPAWAKE_REASON_MULTIPLE" 17 "VCRIGHT_KEEPAWAKE_REASON_DEFOG_CMD" 16 "VCRIGHT_KEEPAWAKE_REASON_DEFOG_CAMERA" 15 "VCRIGHT_KEEPAWAKE_REASON_VOC_PURGE" 14 "VCRIGHT_KEEPAWAKE_REASON_OTHER" 12 "VCRIGHT_KEEPAWAKE_REASON_TRUNK_SWITCH" 11 "VCRIGHT_KEEPAWAKE_REASON_HVAC_EVAP_DRYING" 10 "VCRIGHT_KEEPAWAKE_REASON_UDS_ACTIVE" 9 "VCRIGHT_KEEPAWAKE_REASON_TRUNK_LIGHT" 8 "VCRIGHT_KEEPAWAKE_REASON_SEAT" 7 "VCRIGHT_KEEPAWAKE_REASON_HANDLE" 6 "VCRIGHT_KEEPAWAKE_REASON_EPB_SUMMON_ACTIVE" 5 "VCRIGHT_KEEPAWAKE_REASON_CLOSURE_LATCH" 4 "VCRIGHT_KEEPAWAKE_REASON_HVAC_PRECONDITIONING" 3 "VCRIGHT_KEEPAWAKE_REASON_HVAC_CABIN_PURGE" 2 "VCRIGHT_KEEPAWAKE_REASON_EPB_NOT_SECURE" 1 "VCRIGHT_KEEPAWAKE_REASON_EPB_STATE_NOT_SAVED" 0 "VCRIGHT_KEEPAWAKE_REASON_NONE_SNA" ;
VAL_ 1059 VCRIGHT_nmWakeUpReason 15 "VCRIGHT_WAKEUP_REASON_UNKNOWN" 14 "VCRIGHT_WAKEUP_REASON_DEFOG_CMD" 13 "VCRIGHT_WAKEUP_REASON_DEFOG_CAMERA" 12 "VCRIGHT_WAKEUP_REASON_VOC_PURGE" 11 "VCRIGHT_WAKEUP_REASON_POWER_ON_RESET" 10 "VCRIGHT_WAKEUP_REASON_CABIN_HOT" 9 "VCRIGHT_WAKEUP_REASON_TRUNK_LATCH" 8 "VCRIGHT_WAKEUP_REASON_TRUNK_SWITCH" 7 "VCRIGHT_WAKEUP_REASON_LIN_RX" 6 "VCRIGHT_WAKEUP_REASON_EXTERIOR_HANDLE" 5 "VCRIGHT_WAKEUP_REASON_INTERIOR_HANDLE" 4 "VCRIGHT_WAKEUP_REASON_DOOR_LATCH" 3 "VCRIGHT_WAKEUP_REASON_RESET" 2 "VCRIGHT_WAKEUP_REASON_SWITCH_INPUT" 1 "VCRIGHT_WAKEUP_REASON_ECU_SPECIFIC" 0 "VCRIGHT_WAKEUP_REASON_NONE" ;
VAL_ 1059 VCRIGHT_nmDebugWakeUp 2147483648 "WKPU_31" 1073741824 "WKPU_30" 536870912 "WKPU_29" 268435456 "WKPU_28" 134217728 "WKPU_27" 67108864 "WKPU_26" 33554432 "WKPU_25" 16777216 "WKPU_24" 8388608 "WKPU_23" 4194304 "WKPU_22" 2097152 "WKPU_21" 1048576 "WKPU_20" 524288 "WKPU_19" 262144 "WKPU_18" 131072 "WKPU_17" 65536 "WKPU_16" 32768 "WKPU_15" 16384 "WKPU_14" 8192 "WKPU_13" 4096 "WKPU_12" 2048 "WKPU_11" 1024 "WKPU_10" 512 "WKPU_9" 256 "WKPU_8" 128 "WKPU_7" 64 "WKPU_6" 32 "WKPU_5" 16 "WKPU_4" 8 "WKPU_3" 4 "WKPU_2" 2 "WKPU_1" 1 "WKPU_0" 0 "WKPU_NONE" ;
VAL_ 1059 VCRIGHT_nmEthKeepAwakeReason 15 "VCRIGHT_ETH_KEEPAWAKE_REASON_MULTIPLE" 14 "VCRIGHT_ETH_KEEPAWAKE_REASON_OTHER" 6 "VCRIGHT_ETH_KEEPAWAKE_REASON_TEMP_SENSE_COP_VARIANT_ACTIVE" 5 "VCRIGHT_ETH_KEEPAWAKE_REASON_TEMP_SENSE_POLL" 4 "VCRIGHT_ETH_KEEPAWAKE_REASON_TEMP_SENSE_VCSEC_WAKE" 3 "VCRIGHT_ETH_KEEPAWAKE_REASON_TEMP_SENSE_DWELL_TIME_END" 2 "VCRIGHT_ETH_KEEPAWAKE_REASON_TEMP_SENSE_TRANSITION_FROM_OFF" 1 "VCRIGHT_ETH_KEEPAWAKE_REASON_TEMP_SENSE_TRANSITION_FROM_ACC" 0 "VCRIGHT_ETH_KEEPAWAKE_REASON_NONE_SNA" ;
VAL_ 1059 VCRIGHT_nmChKeepAwakeReason 15 "VCRIGHT_CH_KEEPAWAKE_REASON_MULTIPLE" 14 "VCRIGHT_CH_KEEPAWAKE_REASON_OTHER" 2 "VCRIGHT_CH_KEEPAWAKE_REASON_DEFOG_CMD" 1 "VCRIGHT_CH_KEEPAWAKE_REASON_DEFOG_CAMERA" 0 "VCRIGHT_CH_KEEPAWAKE_REASON_NONE_SNA" ;
VAL_ 707 VCRIGHT_windowStatusIndex 1 "Mux1" 0 "Mux0" ;
VAL_ 707 VCRIGHT_windowStateRF 10 "WINDOW_STATE_SHORT_RISE_REVERSE" 9 "WINDOW_STATE_SHORT_RISE" 8 "WINDOW_STATE_BACKDRIVE" 7 "WINDOW_STATE_MOVING_AUTO_DOWN" 6 "WINDOW_STATE_MOVING_AUTO_UP" 5 "WINDOW_STATE_SHORT_DROP_REVERSE" 4 "WINDOW_STATE_SHORT_DROP" 3 "WINDOW_STATE_BACKOFF" 2 "WINDOW_STATE_MOVING_DOWN" 1 "WINDOW_STATE_MOVING_UP" 0 "WINDOW_STATE_STOPPED" ;
VAL_ 707 VCRIGHT_windowTrimClearMoveReque 3 "WINDOW_TRIM_CLEAR_MOVE_REQUEST_BACKDRIVE" 2 "WINDOW_TRIM_CLEAR_MOVE_REQUEST_RESEAL" 1 "WINDOW_TRIM_CLEAR_MOVE_REQUEST_IDLE" 0 "WINDOW_TRIM_CLEAR_MOVE_REQUEST_SNA" ;
VAL_ 707 VCRIGHT_windowTrimClearActiveReq 2 "WINDOW_TRIM_CLEAR_ACTIVE_REQUEST_ACTIVE" 1 "WINDOW_TRIM_CLEAR_ACTIVE_REQUEST_INACTIVE" 0 "WINDOW_TRIM_CLEAR_ACTIVE_REQUEST_SNA" ;
VAL_ 707 VCRIGHT_windowPositionRF 1 "SNA" ;
VAL_ 707 VCRIGHT_windowStateRR 10 "WINDOW_STATE_SHORT_RISE_REVERSE" 9 "WINDOW_STATE_SHORT_RISE" 8 "WINDOW_STATE_BACKDRIVE" 7 "WINDOW_STATE_MOVING_AUTO_DOWN" 6 "WINDOW_STATE_MOVING_AUTO_UP" 5 "WINDOW_STATE_SHORT_DROP_REVERSE" 4 "WINDOW_STATE_SHORT_DROP" 3 "WINDOW_STATE_BACKOFF" 2 "WINDOW_STATE_MOVING_DOWN" 1 "WINDOW_STATE_MOVING_UP" 0 "WINDOW_STATE_STOPPED" ;
VAL_ 707 VCRIGHT_windowThermalModeRF 3 "WINDOW_THERMAL_MODE_CRITICAL" 2 "WINDOW_THERMAL_MODE_ALERT" 1 "WINDOW_THERMAL_MODE_NORMAL" 0 "WINDOW_THERMAL_MODE_SNA" ;
VAL_ 707 VCRIGHT_windowStopReasonRF 6 "WINDOW_STOP_REASON_STATE_TIMEOUT" 5 "WINDOW_STOP_REASON_FULL_OPEN_SOFT_STOP" 4 "WINDOW_STOP_REASON_STOP_REQUEST" 3 "WINDOW_STOP_REASON_TARGET_REACHED" 2 "WINDOW_STOP_REASON_NEW_REQUEST" 1 "WINDOW_STOP_REASON_DOOR_OPEN_TRIM_PROTECT" 0 "WINDOW_STOP_REASON_NONE" ;
VAL_ 707 VCRIGHT_windowStopReqReasonRF 8 "WINDOW_STOP_REQUEST_REASON_EXTERNAL_REQUEST" 7 "WINDOW_STOP_REQUEST_REASON_FULL_OPEN_SOFT_STOP" 6 "WINDOW_STOP_REQUEST_REASON_STATE_TIMEOUT" 5 "WINDOW_STOP_REQUEST_REASON_STALL" 4 "WINDOW_STOP_REQUEST_REASON_THERMAL" 3 "WINDOW_STOP_REQUEST_REASON_REAR_LOCKOUT" 2 "WINDOW_STOP_REQUEST_REASON_SWITCH_RELEASED" 1 "WINDOW_STOP_REQUEST_REASON_SWITCH_CANCEL_AUTO_MOVEMENT" 0 "WINDOW_STOP_REQUEST_REASON_NONE" ;
VAL_ 707 VCRIGHT_windowThermalModeRR 3 "WINDOW_THERMAL_MODE_CRITICAL" 2 "WINDOW_THERMAL_MODE_ALERT" 1 "WINDOW_THERMAL_MODE_NORMAL" 0 "WINDOW_THERMAL_MODE_SNA" ;
VAL_ 707 VCRIGHT_windowStopReasonRR 6 "WINDOW_STOP_REASON_STATE_TIMEOUT" 5 "WINDOW_STOP_REASON_FULL_OPEN_SOFT_STOP" 4 "WINDOW_STOP_REASON_STOP_REQUEST" 3 "WINDOW_STOP_REASON_TARGET_REACHED" 2 "WINDOW_STOP_REASON_NEW_REQUEST" 1 "WINDOW_STOP_REASON_DOOR_OPEN_TRIM_PROTECT" 0 "WINDOW_STOP_REASON_NONE" ;
VAL_ 707 VCRIGHT_windowStopReqReasonRR 8 "WINDOW_STOP_REQUEST_REASON_EXTERNAL_REQUEST" 7 "WINDOW_STOP_REQUEST_REASON_FULL_OPEN_SOFT_STOP" 6 "WINDOW_STOP_REQUEST_REASON_STATE_TIMEOUT" 5 "WINDOW_STOP_REQUEST_REASON_STALL" 4 "WINDOW_STOP_REQUEST_REASON_THERMAL" 3 "WINDOW_STOP_REQUEST_REASON_REAR_LOCKOUT" 2 "WINDOW_STOP_REQUEST_REASON_SWITCH_RELEASED" 1 "WINDOW_STOP_REQUEST_REASON_SWITCH_CANCEL_AUTO_MOVEMENT" 0 "WINDOW_STOP_REQUEST_REASON_NONE" ;
VAL_ 707 VCRIGHT_windowControlStateRF 2 "WINDOW_CONTROL_STATE_GOING_TO_POSITION" 1 "WINDOW_CONTROL_STATE_CLOSING" 0 "WINDOW_CONTROL_STATE_IDLE" ;
VAL_ 707 VCRIGHT_windowCtrlUnavailableRF 7 "WINDOW_CONTROL_UNAVAILABLE_REASON_WINDOW_MOVING" 6 "WINDOW_CONTROL_UNAVAILABLE_REASON_VEHICLE_IN_DRIVE" 5 "WINDOW_CONTROL_UNAVAILABLE_REASON_UNCALIBRATED" 4 "WINDOW_CONTROL_UNAVAILABLE_REASON_THERMAL_LIMIT" 3 "WINDOW_CONTROL_UNAVAILABLE_REASON_PINCH" 2 "WINDOW_CONTROL_UNAVAILABLE_REASON_SWITCH_PRESSED" 1 "WINDOW_CONTROL_UNAVAILABLE_REASON_UNEXPECTED" 0 "WINDOW_CONTROL_UNAVAILABLE_REASON_NONE" ;
VAL_ 707 VCRIGHT_windowControlStateRR 2 "WINDOW_CONTROL_STATE_GOING_TO_POSITION" 1 "WINDOW_CONTROL_STATE_CLOSING" 0 "WINDOW_CONTROL_STATE_IDLE" ;
VAL_ 707 VCRIGHT_windowCtrlUnavailableRR 7 "WINDOW_CONTROL_UNAVAILABLE_REASON_WINDOW_MOVING" 6 "WINDOW_CONTROL_UNAVAILABLE_REASON_VEHICLE_IN_DRIVE" 5 "WINDOW_CONTROL_UNAVAILABLE_REASON_UNCALIBRATED" 4 "WINDOW_CONTROL_UNAVAILABLE_REASON_THERMAL_LIMIT" 3 "WINDOW_CONTROL_UNAVAILABLE_REASON_PINCH" 2 "WINDOW_CONTROL_UNAVAILABLE_REASON_SWITCH_PRESSED" 1 "WINDOW_CONTROL_UNAVAILABLE_REASON_UNEXPECTED" 0 "WINDOW_CONTROL_UNAVAILABLE_REASON_NONE" ;
VAL_ 707 VCRIGHT_windowPositionStateRF 7 "WINDOW_POSITION_CLOSED_TRIM_CLEAR" 6 "WINDOW_POSITION_FULL_OPEN" 5 "WINDOW_POSITION_PARTIAL_OPEN" 4 "WINDOW_POSITION_DAS_LIMITED" 3 "WINDOW_POSITION_VENT" 2 "WINDOW_POSITION_CRACKED" 1 "WINDOW_POSITION_CLOSED" 0 "WINDOW_POSITION_UNKNOWN" ;
VAL_ 707 VCRIGHT_windowPositionStateRR 7 "WINDOW_POSITION_CLOSED_TRIM_CLEAR" 6 "WINDOW_POSITION_FULL_OPEN" 5 "WINDOW_POSITION_PARTIAL_OPEN" 4 "WINDOW_POSITION_DAS_LIMITED" 3 "WINDOW_POSITION_VENT" 2 "WINDOW_POSITION_CRACKED" 1 "WINDOW_POSITION_CLOSED" 0 "WINDOW_POSITION_UNKNOWN" ;
VAL_ 707 VCRIGHT_windowVehGearStateRF 2 "WINDOW_VEHICLE_GEAR_STATE_IN_GEAR" 1 "WINDOW_VEHICLE_GEAR_STATE_PARK" 0 "WINDOW_VEHICLE_GEAR_STATE_UNKNOWN_SNA" ;
VAL_ 707 VCRIGHT_windowVehGearStateRR 2 "WINDOW_VEHICLE_GEAR_STATE_IN_GEAR" 1 "WINDOW_VEHICLE_GEAR_STATE_PARK" 0 "WINDOW_VEHICLE_GEAR_STATE_UNKNOWN_SNA" ;
VAL_ 707 VCRIGHT_windowSpeedTableStatusRF 2 "WINDOW_SPEED_TABLE_STATUS_FULLY_BUILT" 1 "WINDOW_SPEED_TABLE_STATUS_SENSITIVE_BUILT" 0 "WINDOW_SPEED_TABLE_STATUS_EMPTY_SNA" ;
VAL_ 707 VCRIGHT_windowSpeedTableStatusRR 2 "WINDOW_SPEED_TABLE_STATUS_FULLY_BUILT" 1 "WINDOW_SPEED_TABLE_STATUS_SENSITIVE_BUILT" 0 "WINDOW_SPEED_TABLE_STATUS_EMPTY_SNA" ;
